[part 1 of 2: packages /EcuInstances to /CommunicationClusters/CAN1_Cluster4]
AUTOSAR XML (schema 00046)
package /EcuInstances
  ecu instance ECU4_CRN:
    associated-com-i-pdu-group=[ECU4_CRN_CAN1_Cluster4_Tx_PNC_All_Active, ECU4_CRN_CAN1_Cluster4_Tx_PNC_09, ECU4_CRN_CAN1_Cluster4_Tx_PNC_00, ECU4_CRN_CAN1_Cluster4_Rx_PNC_All_Active, ECU4_CRN_CAN1_Cluster4_Rx_PNC_09, ECU4_CRN_CAN1_Cluster4_Rx_PNC_00, ECU4_CRN_CANFD1_Cluster4_Tx_PNC_All_Active, ECU4_CRN_CANFD1_Cluster4_Tx_PNC_36, ECU4_CRN_CANFD1_Cluster4_Tx_PNC_00, ECU4_CRN_CANFD1_Cluster4_Rx_PNC_All_Active, ECU4_CRN_CANFD1_Cluster4_Rx_PNC_36, ECU4_CRN_CANFD1_Cluster4_Rx_PNC_00, PKG_Eth_Cluster4_1/ECU4_CRN_Eth_Cluster4_Tx_PNC_All_Active, PKG_Eth_Cluster4_127/ECU4_CRN_Eth_Cluster4_Tx_PNC_All_Active, PKG_Eth_Cluster4_20/ECU4_CRN_Eth_Cluster4_Tx_PNC_All_Active, PKG_Eth_Cluster4_127/ECU4_CRN_Eth_Cluster4_Tx_PNC_09, PKG_Eth_Cluster4_20/ECU4_CRN_Eth_Cluster4_Tx_PNC_09, ECU4_CRN_Eth_Cluster4_Tx_PNC_18, ECU4_CRN_Eth_Cluster4_Tx_PNC_27, PKG_Eth_Cluster4_127/ECU4_CRN_Eth_Cluster4_Tx_PNC_36, PKG_Eth_Cluster4_20/ECU4_CRN_Eth_Cluster4_Tx_PNC_36, PKG_Eth_Cluster4_127/ECU4_CRN_Eth_Cluster4_Tx_PNC_45, PKG_Eth_Cluster4_20/ECU4_CRN_Eth_Cluster4_Tx_PNC_45, PKG_Eth_Cluster4_127/ECU4_CRN_Eth_Cluster4_Tx_PNC_54, PKG_Eth_Cluster4_20/ECU4_CRN_Eth_Cluster4_Tx_PNC_54, PKG_Eth_Cluster4_127/ECU4_CRN_Eth_Cluster4_Tx_PNC_00, PKG_Eth_Cluster4_20/ECU4_CRN_Eth_Cluster4_Tx_PNC_00, PKG_Eth_Cluster4_2/ECU4_CRN_Eth_Cluster4_Rx_PNC_All_Active, PKG_Eth_Cluster4_20/ECU4_CRN_Eth_Cluster4_Rx_PNC_All_Active, ECU4_CRN_Eth_Cluster4_Rx_PNC_09, ECU4_CRN_Eth_Cluster4_Rx_PNC_36, ECU4_CRN_Eth_Cluster4_Rx_PNC_45, ECU4_CRN_Eth_Cluster4_Rx_PNC_54, ECU4_CRN_Eth_Cluster4_Rx_PNC_00, TxNorm_ECU4_CRN_LIN5_Cluster4, RxNorm_ECU4_CRN_LIN5_Cluster4]
    com-configuration-gw-time-base=0.005
    com-configuration-rx-time-base=0.005
    com-configuration-tx-time-base=0.005
    eth-switch-port-group-derivation=true
    pn-reset-time=1.1
    pnc-prepare-sleep-timer=1.3
    sleep-mode-supported=true
    wake-up-over-bus-supported=true
    can communication controller ECU4_CRN_CAN1_Cluster4: wake-up-by-controller-supported=true, can-controller-attributes=can-controller-configuration-requirements={max-number-of-time-quanta-per-bit=20, max-sample-point=81.25, max-sync-jump-width=20, min-number-of-time-quanta-per-bit=15, min-sample-point=80, min-sync-jump-width=18.75}
    can communication controller ECU4_CRN_CANFD1_Cluster4: wake-up-by-controller-supported=true, can-controller-attributes=can-controller-configuration-requirements={can-controller-fd-requirements={max-number-of-time-quanta-per-bit=20, max-sample-point=80, max-sync-jump-width=25, min-number-of-time-quanta-per-bit=20, min-sample-point=75, min-sync-jump-width=20, padding-value=0, tx-bit-rate-switch=true}, max-number-of-time-quanta-per-bit=80, max-sample-point=80, max-sync-jump-width=20, min-number-of-time-quanta-per-bit=80, min-sample-point=80, min-sync-jump-width=20}
    ethernet communication controller ECU4_CRN_Eth_Cluster4: mac-unicast-address=00:11:22:33:44:04, maximum-receive-buffer-length=1522, maximum-transmit-buffer-length=1522
      coupling port COUPLING_PORT: connection-negotiation-behavior=MASTER, coupling-port-details=global-time-props=propagation-delay=0, coupling-port-role=STANDARD-PORT, mac-multicast-address=[MACMULTICASTADDRESS_01_00_5e_01_00_08, MACMULTICASTADDRESS_01_00_5e_7f_00_01], physical-layer-type=100BASE-T1  # ECU4_CRN
        vlan-memberships:
          default-priority=0, send-activity=NOT-SENT, vlan=Eth_Cluster4_1
          default-priority=0, send-activity=NOT-SENT, vlan=Eth_Cluster4_2
          default-priority=5, send-activity=NOT-SENT, vlan=Eth_Cluster4_20
          default-priority=5, send-activity=NOT-SENT, vlan=Eth_Cluster4_127
    lin master ECU4_CRN_LIN5_Cluster4: wake-up-by-controller-supported=true, protocol-version=LIN2.1, time-base=0.005, time-base-jitter=0.000176
      lin-slave-config configured-nad=5, function-id=0, initial-nad=5, supplier-id=3, variant-id=0:
        ident IDENT_ECU_IF_Cluster4_LIN_S4
    can communication connector ECU4_CRN_CAN1_Cluster4_6it1ke922hxi7y4c8scsqzzry: comm-controller=ECU4_CRN_CAN1_Cluster4, pnc-gateway-type=ACTIVE, pnc-wakeup-data-mask=131328
    can communication connector ECU4_CRN_CANFD1_Cluster4_bx4qzxpu7xp7napnh6bsrtlzq: comm-controller=ECU4_CRN_CANFD1_Cluster4, pnc-gateway-type=ACTIVE, pnc-wakeup-data-mask=17592186044672
    ethernet communication connector ECU4_CRN_Eth_Cluster4_7f3fu4rgtopbi2t35la2b13rd: comm-controller=ECU4_CRN_Eth_Cluster4, pnc-gateway-type=NONE, maximum-transmission-unit=1500, neighbor-cache-size=128, network-endpoint=NE_dhcpv4AndFixed_169_254_17_4, pnc-filter-data-mask=4620710844295151872
    ethernet communication connector ECU4_CRN_Eth_Cluster4_3g6xoesclytkmkqofl9pi6ol1: comm-controller=ECU4_CRN_Eth_Cluster4, pnc-gateway-type=PASSIVE, maximum-transmission-unit=1500, neighbor-cache-size=128, network-endpoint=[NE_Multicast_Rx_fixed_239_127_0_1, NE_fixed_10_127_1_4], pnc-filter-data-mask=4620710844295151872
    ethernet communication connector ECU4_CRN_Eth_Cluster4_a4tivcve7b3dlvxw1emxbqzmz: comm-controller=ECU4_CRN_Eth_Cluster4, pnc-gateway-type=NONE, maximum-transmission-unit=1500, neighbor-cache-size=128, network-endpoint=[NE_Multicast_Rx_fixed_239_2_0_17, NE_fixed_10_2_1_4], pnc-filter-data-mask=4620710844295151872
    ethernet communication connector ECU4_CRN_Eth_Cluster4_3l8iyw65auc022so95pkbhyzp: comm-controller=ECU4_CRN_Eth_Cluster4, pnc-gateway-type=NONE, maximum-transmission-unit=1500, neighbor-cache-size=128, network-endpoint=[NE_fixed_10_20_1_4, NE_Multicast_Rx_Any, NE_Multicast_Rx_fixed_239_20_0_2], pnc-filter-data-mask=4620710844295151872
    lin communication connector ECU4_CRN_LIN5_Cluster4_b21l9awrmlmhxxw03j6k8wiqt: comm-controller=ECU4_CRN_LIN5_Cluster4
package /Systems
  system SYSTEM_XDIS: category=SYSTEM_EXTRACT, container-i-pdu-header-byte-order=big-endian, ecu-extract-version=2020.45.00, pnc-vector-length=7, pnc-vector-offset=1, system-version=2020.45.00
package /SystemSignalGroups
  24 x system signal group:
    COM_C04_SGR01_P05: system-signal=[COM_C04_Sig004, CRC_COM_C04_SGR01_P05, SQC_COM_C04_SGR01_P05]
    COM_C04_SGR01_P05_5t2743h81pbparal6h2spw309: system-signal=[COM_C04_Sig004, CRC_COM_C04_SGR01_P05, SQC_COM_C04_SGR01_P05]  # COM_C04_SGR01_P05 (degraded)
    DI_Odo_Pr5_ST3: system-signal=[CRC_DI_Odo_Pr5_ST3, Odo_ST3, SQC_DI_Odo_Pr5_ST3]  # DriverInformation Odometer
    DI_Odo_Pr5_ST3_e68xmtlkywxgxsdwekdjjhw3t: system-signal=[CRC_DI_Odo_Pr5_ST3, Odo_ST3, SQC_DI_Odo_Pr5_ST3]  # DriverInformation Odometer (degraded)
    Diag_RoE_C04_SigGrp01: system-signal=[Diag_RoE_C04_Sig00, Diag_RoE_C04_Sig01, Diag_RoE_C04_Sig02, Diag_RoE_C04_Sig03, Diag_RoE_C04_Sig04, Diag_RoE_C04_Sig05, Diag_RoE_C04_Sig06, Diag_RoE_C04_Sig07]  # Diag RoE C14 Sig Grp 01
    Diag_RoE_C04_SigGrp01_2ksq5hjijyze6lf3nboiafq6k: system-signal=[Diag_RoE_C04_Sig00, Diag_RoE_C04_Sig01, Diag_RoE_C04_Sig02, Diag_RoE_C04_Sig03, Diag_RoE_C04_Sig04, Diag_RoE_C04_Sig05, Diag_RoE_C04_Sig06, Diag_RoE_C04_Sig07]  # Diag RoE C14 Sig Grp 01 (degraded)
    Ign_Stat_Pr5_ST3: system-signal=[CRC_Ign_Stat_Pr5_ST3, ISw_Stat_ST3, KG_StartSw_Psd_ST3, SQC_Ign_Stat_Pr5_ST3, Veh_Op_Mode_ST3]  # Zuendungsstatus / Ignition state
    Ign_Stat_Pr5_ST3_csgs1dv6drms80o1i9p49677w: system-signal=[CRC_Ign_Stat_Pr5_ST3, ISw_Stat_ST3, KG_StartSw_Psd_ST3, SQC_Ign_Stat_Pr5_ST3, Veh_Op_Mode_ST3]  # Zuendungsstatus (degraded) / Ignition state (degraded)
    PT4_PTCoor4_Pr5_ST3: system-signal=[CRC_PT4_PTCoor4_Pr5_ST3, PT4_PTCoor_EngStartPN14_Stat_ST3, PT4_PTCoor_PT_Rdy_ST3, PT4_PTCoor_SSA_EngSp_ST3, Rsrv1_PT4_PTCoor_PT_Rdy_Pr5_ST3, SQC_PT4_PTCoor4_Pr5_ST3]
    PT4_PTCoor4_Pr5_ST3_af4fxb1ykieox3itqdfzs0kpb: system-signal=[CRC_PT4_PTCoor4_Pr5_ST3, PT4_PTCoor_EngStartPN14_Stat_ST3, PT4_PTCoor_PT_Rdy_ST3, PT4_PTCoor_SSA_EngSp_ST3, Rsrv1_PT4_PTCoor_PT_Rdy_Pr5_ST3, SQC_PT4_PTCoor4_Pr5_ST3]  # PT4_PTCoor4_Pr5_ST3 (degraded)
    VehSpd8_Pr5_ST3: system-signal=[CRC_VehSpd8_Pr5_ST3, SQC_VehSpd8_Pr5_ST3, VehSpd8_ST3]  # Fahrzeug Spd 8 ST3 / vehicle Spd 8 ST3
    VehSpd8_Pr5_ST3_168m1ogyookfwuxfakr38tbmv: system-signal=[CRC_VehSpd8_Pr5_ST3, SQC_VehSpd8_Pr5_ST3, VehSpd8_ST3]  # Fahrzeug Spd 8 ST3 (degraded) / vehicle Spd 8 ST3 (degraded)
    VSS_TP_Auth_ST3: system-signal=[VSS_TP_Auth_0_ST3, VSS_TP_Auth_1_ST3, VSS_TP_Auth_2_ST3, VSS_TP_Auth_3_ST3, VSS_TP_Auth_4_ST3, VSS_TP_Auth_5_ST3, VSS_TP_Auth_6_ST3, VSS_TP_Auth_7_ST3]  # VSS-Transportprotokoll für Authentifizierung / Vehicle Security System Transport Protocol for authentication broadcast
    VSS_TP_Auth_ST3_6j4id7sghlvlbroli4wjozjik: system-signal=[VSS_TP_Auth_0_ST3, VSS_TP_Auth_1_ST3, VSS_TP_Auth_2_ST3, VSS_TP_Auth_3_ST3, VSS_TP_Auth_4_ST3, VSS_TP_Auth_5_ST3, VSS_TP_Auth_6_ST3, VSS_TP_Auth_7_ST3]  # VSS-Transportprotokoll für Authentifizierung (degraded) / Vehicle Security System Transport Protocol for authentication broadcast (degraded)
    VSS_TP_RealTmOffset_ST3: system-signal=[VSS_TP_RealTmOffset_0_ST3, VSS_TP_RealTmOffset_1_ST3, VSS_TP_RealTmOffset_2_ST3, VSS_TP_RealTmOffset_3_ST3, VSS_TP_RealTmOffset_4_ST3, VSS_TP_RealTmOffset_5_ST3, VSS_TP_RealTmOffset_6_ST3, VSS_TP_RealTmOffset_7_ST3]  # VSS-Transportprotokoll für Echtzeit-Offset / Vehicle Security System Transport Protocol for real time offset broadcast
    VSS_TP_RealTmOffset_ST3_1t7vc44gftc0wv35k5kgc2in9: system-signal=[VSS_TP_RealTmOffset_0_ST3, VSS_TP_RealTmOffset_1_ST3, VSS_TP_RealTmOffset_2_ST3, VSS_TP_RealTmOffset_3_ST3, VSS_TP_RealTmOffset_4_ST3, VSS_TP_RealTmOffset_5_ST3, VSS_TP_RealTmOffset_6_ST3, VSS_TP_RealTmOffset_7_ST3]  # VSS-Transportprotokoll für Echtzeit-Offset (degraded) / Vehicle Security System Transport Protocol for real time offset broadcast (degraded)
    VSS_TP_SecTickCount_Lvl1_ST3: system-signal=[VSS_TP_SecTickCount_Lvl1_0_ST3, VSS_TP_SecTickCount_Lvl1_1_ST3, VSS_TP_SecTickCount_Lvl1_2_ST3, VSS_TP_SecTickCount_Lvl1_3_ST3, VSS_TP_SecTickCount_Lvl1_4_ST3, VSS_TP_SecTickCount_Lvl1_5_ST3, VSS_TP_SecTickCount_Lvl1_6_ST3, VSS_TP_SecTickCount_Lvl1_7_ST3]  # VSS-Transportprotokoll für sichere Zeit Stufe 1 / Vehicle Security System Transport Protocol for secure tick count level #1
    VSS_TP_SecTickCount_Lvl1_ST3_mzmfdqtqz5kvv1kfpvg0kql3: system-signal=[VSS_TP_SecTickCount_Lvl1_0_ST3, VSS_TP_SecTickCount_Lvl1_1_ST3, VSS_TP_SecTickCount_Lvl1_2_ST3, VSS_TP_SecTickCount_Lvl1_3_ST3, VSS_TP_SecTickCount_Lvl1_4_ST3, VSS_TP_SecTickCount_Lvl1_5_ST3, VSS_TP_SecTickCount_Lvl1_6_ST3, VSS_TP_SecTickCount_Lvl1_7_ST3]  # VSS-Transportprotokoll für sichere Zeit Stufe 1 (degraded) / Vehicle Security System Transport Protocol for secure tick count level #1 (degraded)
    VSS_TP_SecTickCount_Lvl2_ST3: system-signal=[VSS_TP_SecTickCount_Lvl2_0_ST3, VSS_TP_SecTickCount_Lvl2_1_ST3, VSS_TP_SecTickCount_Lvl2_2_ST3, VSS_TP_SecTickCount_Lvl2_3_ST3, VSS_TP_SecTickCount_Lvl2_4_ST3, VSS_TP_SecTickCount_Lvl2_5_ST3, VSS_TP_SecTickCount_Lvl2_6_ST3, VSS_TP_SecTickCount_Lvl2_7_ST3]  # VSS-Transportprotokoll für sichere Zeit Stufe 2 / Vehicle Security System Transport Protocol for secure tick count level #2
    VSS_TP_SecTickCount_Lvl2_ST3_9eubq13iosat764o0lqh5xb6r: system-signal=[VSS_TP_SecTickCount_Lvl2_0_ST3, VSS_TP_SecTickCount_Lvl2_1_ST3, VSS_TP_SecTickCount_Lvl2_2_ST3, VSS_TP_SecTickCount_Lvl2_3_ST3, VSS_TP_SecTickCount_Lvl2_4_ST3, VSS_TP_SecTickCount_Lvl2_5_ST3, VSS_TP_SecTickCount_Lvl2_6_ST3, VSS_TP_SecTickCount_Lvl2_7_ST3]  # VSS-Transportprotokoll für sichere Zeit Stufe 2 (degraded) / Vehicle Security System Transport Protocol for secure tick count level #2 (degraded)
    VSS_TP_SharedSecret_ST3: system-signal=[VSS_TP_SharedSecret_0_ST3, VSS_TP_SharedSecret_1_ST3, VSS_TP_SharedSecret_2_ST3, VSS_TP_SharedSecret_3_ST3, VSS_TP_SharedSecret_4_ST3, VSS_TP_SharedSecret_5_ST3, VSS_TP_SharedSecret_6_ST3, VSS_TP_SharedSecret_7_ST3]  # VSS-Transportprotokoll für gemeinsames Geheimnis / Vehicle Security System Transport Protocol for shared secret broadcast
    VSS_TP_SharedSecret_ST3_8pj4t8t4rm3tw3pk5hj7vonti: system-signal=[VSS_TP_SharedSecret_0_ST3, VSS_TP_SharedSecret_1_ST3, VSS_TP_SharedSecret_2_ST3, VSS_TP_SharedSecret_3_ST3, VSS_TP_SharedSecret_4_ST3, VSS_TP_SharedSecret_5_ST3, VSS_TP_SharedSecret_6_ST3, VSS_TP_SharedSecret_7_ST3]  # VSS-Transportprotokoll für gemeinsames Geheimnis (degraded) / Vehicle Security System Transport Protocol for shared secret broadcast (degraded)
    VSS_TP_VIN_ST3: system-signal=[VSS_TP_VIN_0_ST3, VSS_TP_VIN_1_ST3, VSS_TP_VIN_2_ST3, VSS_TP_VIN_3_ST3, VSS_TP_VIN_4_ST3, VSS_TP_VIN_5_ST3, VSS_TP_VIN_6_ST3, VSS_TP_VIN_7_ST3]  # VSS-Transportprotokoll für Fahrzeugidentifikationsnummer / Vehicle Security System Transport Protocol for Vehicle Identification Number
    VSS_TP_VIN_ST3_bz1xsv84cxzl09j028gn39p69: system-signal=[VSS_TP_VIN_0_ST3, VSS_TP_VIN_1_ST3, VSS_TP_VIN_2_ST3, VSS_TP_VIN_3_ST3, VSS_TP_VIN_4_ST3, VSS_TP_VIN_5_ST3, VSS_TP_VIN_6_ST3, VSS_TP_VIN_7_ST3]  # VSS-Transportprotokoll für Fahrzeugidentifikationsnummer (degraded) / Vehicle Security System Transport Protocol for Vehicle Identification Number (degraded)
package /Pdus/CAN1_Cluster4/PKG_CAN1_Cluster4
  pdu Ign_Stat_ST3: length=4, minimum-delay=0.02, transmission-mode-true-timing={cyclic-timing={time-offset=0.01, time-period=0.1}, event-controlled-timing=number-of-repetitions=0}, unused-bit-pattern=255  # Zuendungsstatus / Ignition state
    signal CRC_Ign_Stat_Pr5_ST3: start 0, 16 bit, little-endian, data-type-policy=OVERRIDE, i-signal-type=PRIMITIVE, init-value=20886, base-type=uint16, data-constr=c16_CRC_woSNA, transfer-property=PENDING  # CRC-Checksumme der Signal Gruppe gemäß AUTOSAR Profil 5 / CRC-checksum of signal group according to AUTOSAR Profile 5
    signal ISw_Stat_ST3: start 24, 3 bit, little-endian, data-type-policy=OVERRIDE, i-signal-type=PRIMITIVE, init-value=7, base-type=uint8, invalid-value=7, compu-method=c03_ISw_Stat, data-constr=c03_ISw_Stat, transfer-property=TRIGGERED-ON-CHANGE  # Klemmenstatus / Ignition switch state
    signal KG_StartSw_Psd_ST3: start 31, 1 bit, little-endian, data-type-policy=OVERRIDE, i-signal-type=PRIMITIVE, init-value=0, base-type=boolean, transfer-property=TRIGGERED-ON-CHANGE  # Keyless Go Starttaster betätigt / Keyless Go start switch pressed
    signal SQC_Ign_Stat_Pr5_ST3: start 16, 8 bit, little-endian, data-type-policy=OVERRIDE, i-signal-type=PRIMITIVE, init-value=0, base-type=uint8, compu-method=none_1_0, data-constr=c08_0_255_1_SNA_na, transfer-property=PENDING  # Sequenzzähler / Sequence counter
    signal Veh_Op_Mode_ST3: start 27, 4 bit, little-endian, data-type-policy=OVERRIDE, i-signal-type=PRIMITIVE, init-value=0, base-type=uint8, invalid-value=15, compu-method=c04_VehOpMode, data-constr=c04_VehOpMode, transfer-property=TRIGGERED-ON-CHANGE  # Fahrzeug Betriebsmodus / Operating Mode Vehicle
    mapping Ign_Stat_Pr5_ST3_csgs1dv6drms80o1i9p49677w: i-signal-group=Ign_Stat_ST3/Ign_Stat_Pr5_ST3_csgs1dv6drms80o1i9p49677w, packing-byte-order=little-endian, transfer-property=TRIGGERED-ON-CHANGE
  dcm i pdu SDU_DIAG_C10_ExtEth_RQ_CAN1_CTP: length=4095, diag-pdu-type=DIAG-REQUEST
  dcm i pdu SDU_DIAG_C10_ExtEth_RS_CAN1_CTP: length=4095, diag-pdu-type=DIAG-RESPONSE
  dcm i pdu SDU_DIAG_C10_IntEth_RQ_CAN1_CTP: length=4095, diag-pdu-type=DIAG-REQUEST
  dcm i pdu SDU_DIAG_C10_IntEth_RS_CAN1_CTP: length=4095, diag-pdu-type=DIAG-RESPONSE
  dcm i pdu SDU_DIAG_GLOBAL_ExtEth_RQ_CAN1_ST3: length=7, diag-pdu-type=DIAG-REQUEST
  dcm i pdu SDU_DIAG_GLOBAL_IntEth_RQ_CAN1_ST3: length=7, diag-pdu-type=DIAG-REQUEST
package /Pdus/CANFD1_Cluster4/PKG_CANFD1_Cluster4
  secured i pdu C04_CANFD_1_Container_ST3_C04_CANFD_1_Container_ST3_Ign_Stat_ST3_secured: length=8, contained-i-pdu-props={collection-semantics=LAST-IS-BEST, header-id-short-header=32768, timeout=0.01, trigger=NEVER}, authentication-props=SECOC_AP_CMAC_AES_128_24, freshness-props=SECOC_FP_10000_40_8_true, payload=C04_CANFD_1_Container_ST3_C04_CANFD_1_Container_ST3_Ign_Stat_ST3_eexaxtkd214droewntksh6wv, secure-communication-props={authentication-retries=0, data-id=28212, freshness-value-id=1}
  dcm i pdu SDU_DIAG_C19_ExtEth_RQ_CANFD1_CTP: length=4095, diag-pdu-type=DIAG-REQUEST
  dcm i pdu SDU_DIAG_C19_ExtEth_RS_CANFD1_CTP: length=4095, diag-pdu-type=DIAG-RESPONSE
  dcm i pdu SDU_DIAG_C19_IntEth_RQ_CANFD1_CTP: length=4095, diag-pdu-type=DIAG-REQUEST
  dcm i pdu SDU_DIAG_C19_IntEth_RS_CANFD1_CTP: length=4095, diag-pdu-type=DIAG-RESPONSE
  dcm i pdu SDU_DIAG_ECU4_CTP_03_ExtCAN_RQ_FD1_ST3: length=4095, diag-pdu-type=DIAG-REQUEST
  dcm i pdu SDU_DIAG_ECU4_CTP_03_ExtCAN_RS_FD1_ST3: length=4095, diag-pdu-type=DIAG-RESPONSE
  dcm i pdu SDU_DIAG_GLOBAL_ExtCAN_RQ_CANFD1_ST3: length=7, diag-pdu-type=DIAG-REQUEST
  dcm i pdu SDU_DIAG_GLOBAL_ExtEth_RQ_CANFD1_ST3: length=7, diag-pdu-type=DIAG-REQUEST
  dcm i pdu SDU_DIAG_GLOBAL_IntEth_RQ_CANFD1_ST3: length=7, diag-pdu-type=DIAG-REQUEST
  pdu SDU_TPA_CANFD_Eth_ST3: length=800, minimum-delay=0.005, transmission-mode-true-timing=event-controlled-timing=number-of-repetitions=0
    signal TPA_CANFD_Eth_ST3_ISignal: start 0, 6400 bit, opaque, i-signal-type=ARRAY, base-type=uint8, dynamic-length=true, transfer-property=TRIGGERED  # Transport Protokoll zwischen CAN-FD ECU und Ethernet ECU / Transport protocol between CAN-FD ECU and Ethernet ECU
  pdu SDU_TPA_Eth_CANFD_ST3: length=55, minimum-delay=0.005, transmission-mode-true-timing=event-controlled-timing=number-of-repetitions=0
    signal TPA_Eth_CANFD_ST3_ISignal: start 0, 440 bit, opaque, i-signal-type=ARRAY, base-type=uint8, dynamic-length=true, transfer-property=TRIGGERED  # Transport Protokoll zwischen Ethernet ECU und CAN-FD ECU / Transport protocol between Ethernet ECU and CAN-FD ECU
package /Pdus/CANFD1_Cluster4/PKG_CANFD1_Cluster4/C04_CANFD_1_Container_ST3
  pdu C04_CANFD_1_Container_ST3_Ign_Stat_ST3: length=4, minimum-delay=0.02, transmission-mode-true-timing={cyclic-timing=time-period=0.1, event-controlled-timing=number-of-repetitions=0}, unused-bit-pattern=255  # Zuendungsstatus / Ignition state
    signal CRC_Ign_Stat_Pr5_ST3: start 0, 16 bit, little-endian, data-type-policy=OVERRIDE, i-signal-type=PRIMITIVE, init-value=20886, base-type=uint16, data-constr=c16_CRC_woSNA, transfer-property=PENDING  # CRC-Checksumme der Signal Gruppe gemäß AUTOSAR Profil 5 / CRC-checksum of signal group according to AUTOSAR Profile 5
    signal ISw_Stat_ST3: start 24, 3 bit, little-endian, data-type-policy=OVERRIDE, i-signal-type=PRIMITIVE, init-value=7, base-type=uint8, invalid-value=7, compu-method=c03_ISw_Stat, data-constr=c03_ISw_Stat, transfer-property=TRIGGERED-ON-CHANGE  # Klemmenstatus / Ignition switch state
    signal KG_StartSw_Psd_ST3: start 31, 1 bit, little-endian, data-type-policy=OVERRIDE, i-signal-type=PRIMITIVE, init-value=0, base-type=boolean, transfer-property=TRIGGERED-ON-CHANGE  # Keyless Go Starttaster betätigt / Keyless Go start switch pressed
    signal SQC_Ign_Stat_Pr5_ST3: start 16, 8 bit, little-endian, data-type-policy=OVERRIDE, i-signal-type=PRIMITIVE, init-value=0, base-type=uint8, compu-method=none_1_0, data-constr=c08_0_255_1_SNA_na, transfer-property=PENDING  # Sequenzzähler / Sequence counter
    signal Veh_Op_Mode_ST3: start 27, 4 bit, little-endian, data-type-policy=OVERRIDE, i-signal-type=PRIMITIVE, init-value=0, base-type=uint8, invalid-value=15, compu-method=c04_VehOpMode, data-constr=c04_VehOpMode, transfer-property=TRIGGERED-ON-CHANGE  # Fahrzeug Betriebsmodus / Operating Mode Vehicle
    mapping Ign_Stat_Pr5_ST3_csgs1dv6drms80o1i9p49677w: i-signal-group=C04_CANFD_1_Container_ST3_Ign_Stat_ST3/Ign_Stat_Pr5_ST3_csgs1dv6drms80o1i9p49677w, packing-byte-order=little-endian, transfer-property=TRIGGERED-ON-CHANGE
  pdu C04_CANFD_1_Container_ST3_VSS_TP_Auth_ST3: length=8, contained-i-pdu-props={collection-semantics=LAST-IS-BEST, header-id-short-header=4259841, timeout=0.01, trigger=NEVER}, minimum-delay=0.02, transmission-mode-true-timing=event-controlled-timing=number-of-repetitions=0, unused-bit-pattern=255  # VSS-Transportprotokoll für Authentifizierung / Vehicle Security System Transport Protocol for authentication broadcast
    signal VSS_TP_Auth_0_ST3: start 0, 8 bit, little-endian, data-type-policy=OVERRIDE, i-signal-type=PRIMITIVE, init-value=255, base-type=uint8, data-constr=c08_UInt_SNA_na  # VSS-Transportprotokoll für Authentifizierung, Byte 0 / Vehicle Security System Transport Protocol for authentication broadcast, Byte 0
    signal VSS_TP_Auth_1_ST3: start 8, 8 bit, little-endian, data-type-policy=OVERRIDE, i-signal-type=PRIMITIVE, init-value=255, base-type=uint8, data-constr=c08_UInt_SNA_na  # VSS-Transportprotokoll für Authentifizierung, Byte 1 / Vehicle Security System Transport Protocol for authentication broadcast, Byte 1
    signal VSS_TP_Auth_2_ST3: start 16, 8 bit, little-endian, data-type-policy=OVERRIDE, i-signal-type=PRIMITIVE, init-value=255, base-type=uint8, data-constr=c08_UInt_SNA_na  # VSS-Transportprotokoll für Authentifizierung, Byte 2 / Vehicle Security System Transport Protocol for authentication broadcast, Byte 2
    signal VSS_TP_Auth_3_ST3: start 24, 8 bit, little-endian, data-type-policy=OVERRIDE, i-signal-type=PRIMITIVE, init-value=255, base-type=uint8, data-constr=c08_UInt_SNA_na  # VSS-Transportprotokoll für Authentifizierung, Byte 3 / Vehicle Security System Transport Protocol for authentication broadcast, Byte 3
    signal VSS_TP_Auth_4_ST3: start 32, 8 bit, little-endian, data-type-policy=OVERRIDE, i-signal-type=PRIMITIVE, init-value=255, base-type=uint8, data-constr=c08_UInt_SNA_na  # VSS-Transportprotokoll für Authentifizierung, Byte 4 / Vehicle Security System Transport Protocol for authentication broadcast, Byte 4
    signal VSS_TP_Auth_5_ST3: start 40, 8 bit, little-endian, data-type-policy=OVERRIDE, i-signal-type=PRIMITIVE, init-value=255, base-type=uint8, data-constr=c08_UInt_SNA_na  # VSS-Transportprotokoll für Authentifizierung, Byte 5 / Vehicle Security System Transport Protocol for authentication broadcast, Byte 5
    signal VSS_TP_Auth_6_ST3: start 48, 8 bit, little-endian, data-type-policy=OVERRIDE, i-signal-type=PRIMITIVE, init-value=255, base-type=uint8, data-constr=c08_UInt_SNA_na  # VSS-Transportprotokoll für Authentifizierung, Byte 6 / Vehicle Security System Transport Protocol for authentication broadcast, Byte 6
    signal VSS_TP_Auth_7_ST3: start 56, 8 bit, little-endian, data-type-policy=OVERRIDE, i-signal-type=PRIMITIVE, init-value=255, base-type=uint8, data-constr=c08_UInt_SNA_na  # VSS-Transportprotokoll für Authentifizierung, Byte 7 / Vehicle Security System Transport Protocol for authentication broadcast, Byte 7
    mapping VSS_TP_Auth_ST3_6j4id7sghlvlbroli4wjozjik: i-signal-group=C04_CANFD_1_Container_ST3_VSS_TP_Auth_ST3/VSS_TP_Auth_ST3_6j4id7sghlvlbroli4wjozjik, packing-byte-order=little-endian, transfer-property=TRIGGERED
  pdu C04_CANFD_1_Container_ST3_VSS_TP_RealTmOffset_ST3: length=8, contained-i-pdu-props={collection-semantics=LAST-IS-BEST, header-id-short-header=4259842, timeout=0.01, trigger=NEVER}, minimum-delay=0.02, transmission-mode-true-timing=event-controlled-timing=number-of-repetitions=0, unused-bit-pattern=255  # VSS-Transportprotokoll für Echtzeit-Offset / Vehicle Security System Transport Protocol for real time offset broadcast
    signal VSS_TP_RealTmOffset_0_ST3: start 0, 8 bit, little-endian, data-type-policy=OVERRIDE, i-signal-type=PRIMITIVE, init-value=255, base-type=uint8, data-constr=c08_UInt_SNA_na  # VSS-Transportprotokoll für Echtzeit-Offset, Byte 0 / Vehicle Security System Transport Protocol for real time offset broadcast, Byte 0
    signal VSS_TP_RealTmOffset_1_ST3: start 8, 8 bit, little-endian, data-type-policy=OVERRIDE, i-signal-type=PRIMITIVE, init-value=255, base-type=uint8, data-constr=c08_UInt_SNA_na  # VSS-Transportprotokoll für Echtzeit-Offset, Byte 1 / Vehicle Security System Transport Protocol for real time offset broadcast, Byte 1
    signal VSS_TP_RealTmOffset_2_ST3: start 16, 8 bit, little-endian, data-type-policy=OVERRIDE, i-signal-type=PRIMITIVE, init-value=255, base-type=uint8, data-constr=c08_UInt_SNA_na  # VSS-Transportprotokoll für Echtzeit-Offset, Byte 2 / Vehicle Security System Transport Protocol for real time offset broadcast, Byte 2
    signal VSS_TP_RealTmOffset_3_ST3: start 24, 8 bit, little-endian, data-type-policy=OVERRIDE, i-signal-type=PRIMITIVE, init-value=255, base-type=uint8, data-constr=c08_UInt_SNA_na  # VSS-Transportprotokoll für Echtzeit-Offset, Byte 3 / Vehicle Security System Transport Protocol for real time offset broadcast, Byte 3
    signal VSS_TP_RealTmOffset_4_ST3: start 32, 8 bit, little-endian, data-type-policy=OVERRIDE, i-signal-type=PRIMITIVE, init-value=255, base-type=uint8, data-constr=c08_UInt_SNA_na  # VSS-Transportprotokoll für Echtzeit-Offset, Byte 4 / Vehicle Security System Transport Protocol for real time offset broadcast, Byte 4
    signal VSS_TP_RealTmOffset_5_ST3: start 40, 8 bit, little-endian, data-type-policy=OVERRIDE, i-signal-type=PRIMITIVE, init-value=255, base-type=uint8, data-constr=c08_UInt_SNA_na  # VSS-Transportprotokoll für Echtzeit-Offset, Byte 5 / Vehicle Security System Transport Protocol for real time offset broadcast, Byte 5
    signal VSS_TP_RealTmOffset_6_ST3: start 48, 8 bit, little-endian, data-type-policy=OVERRIDE, i-signal-type=PRIMITIVE, init-value=255, base-type=uint8, data-constr=c08_UInt_SNA_na  # VSS-Transportprotokoll für Echtzeit-Offset, Byte 6 / Vehicle Security System Transport Protocol for real time offset broadcast, Byte 6
    signal VSS_TP_RealTmOffset_7_ST3: start 56, 8 bit, little-endian, data-type-policy=OVERRIDE, i-signal-type=PRIMITIVE, init-value=255, base-type=uint8, data-constr=c08_UInt_SNA_na  # VSS-Transportprotokoll für Echtzeit-Offset, Byte 7 / Vehicle Security System Transport Protocol for real time offset broadcast, Byte 7
    mapping VSS_TP_RealTmOffset_ST3_1t7vc44gftc0wv35k5kgc2in9: i-signal-group=C04_CANFD_1_Container_ST3_VSS_TP_RealTmOffset_ST3/VSS_TP_RealTmOffset_ST3_1t7vc44gftc0wv35k5kgc2in9, packing-byte-order=little-endian, transfer-property=TRIGGERED
  pdu C04_CANFD_1_Container_ST3_VSS_TP_SecTickCount_Lvl2_ST3: length=8, contained-i-pdu-props={collection-semantics=LAST-IS-BEST, header-id-short-header=4259845, timeout=0, trigger=ALWAYS}, minimum-delay=0.02, transmission-mode-true-timing=event-controlled-timing=number-of-repetitions=0, unused-bit-pattern=255  # VSS-Transportprotokoll für sichere Zeit Stufe 2 / Vehicle Security System Transport Protocol for secure tick count level #2
    signal VSS_TP_SecTickCount_Lvl2_0_ST3: start 0, 8 bit, little-endian, data-type-policy=OVERRIDE, i-signal-type=PRIMITIVE, init-value=255, base-type=uint8, data-constr=c08_UInt_SNA_na  # VSS-Transportprotokoll für sichere Zeit Stufe 2, Byte 0 / Vehicle Security System Transport Protocol for secure tick count level #2, Byte 0
    signal VSS_TP_SecTickCount_Lvl2_1_ST3: start 8, 8 bit, little-endian, data-type-policy=OVERRIDE, i-signal-type=PRIMITIVE, init-value=255, base-type=uint8, data-constr=c08_UInt_SNA_na  # VSS-Transportprotokoll für sichere Zeit Stufe 2, Byte 1 / Vehicle Security System Transport Protocol for secure tick count level #2, Byte 1
    signal VSS_TP_SecTickCount_Lvl2_2_ST3: start 16, 8 bit, little-endian, data-type-policy=OVERRIDE, i-signal-type=PRIMITIVE, init-value=255, base-type=uint8, data-constr=c08_UInt_SNA_na  # VSS-Transportprotokoll für sichere Zeit Stufe 2, Byte 2 / Vehicle Security System Transport Protocol for secure tick count level #2, Byte 2
    signal VSS_TP_SecTickCount_Lvl2_3_ST3: start 24, 8 bit, little-endian, data-type-policy=OVERRIDE, i-signal-type=PRIMITIVE, init-value=255, base-type=uint8, data-constr=c08_UInt_SNA_na  # VSS-Transportprotokoll für sichere Zeit Stufe 2, Byte 3 / Vehicle Security System Transport Protocol for secure tick count level #2, Byte 3
    signal VSS_TP_SecTickCount_Lvl2_4_ST3: start 32, 8 bit, little-endian, data-type-policy=OVERRIDE, i-signal-type=PRIMITIVE, init-value=255, base-type=uint8, data-constr=c08_UInt_SNA_na  # VSS-Transportprotokoll für sichere Zeit Stufe 2, Byte 4 / Vehicle Security System Transport Protocol for secure tick count level #2, Byte 4
    signal VSS_TP_SecTickCount_Lvl2_5_ST3: start 40, 8 bit, little-endian, data-type-policy=OVERRIDE, i-signal-type=PRIMITIVE, init-value=255, base-type=uint8, data-constr=c08_UInt_SNA_na  # VSS-Transportprotokoll für sichere Zeit Stufe 2, Byte 5 / Vehicle Security System Transport Protocol for secure tick count level #2, Byte 5
    signal VSS_TP_SecTickCount_Lvl2_6_ST3: start 48, 8 bit, little-endian, data-type-policy=OVERRIDE, i-signal-type=PRIMITIVE, init-value=255, base-type=uint8, data-constr=c08_UInt_SNA_na  # VSS-Transportprotokoll für sichere Zeit Stufe 2, Byte 6 / Vehicle Security System Transport Protocol for secure tick count level #2, Byte 6
    signal VSS_TP_SecTickCount_Lvl2_7_ST3: start 56, 8 bit, little-endian, data-type-policy=OVERRIDE, i-signal-type=PRIMITIVE, init-value=255, base-type=uint8, data-constr=c08_UInt_SNA_na  # VSS-Transportprotokoll für sichere Zeit Stufe 2, Byte 7 / Vehicle Security System Transport Protocol for secure tick count level #2, Byte 7
    mapping VSS_TP_SecTickCount_Lvl2_ST3_9eubq13iosat764o0lqh5xb6r: i-signal-group=C04_CANFD_1_Container_ST3_VSS_TP_SecTickCount_Lvl2_ST3/VSS_TP_SecTickCount_Lvl2_ST3_9eubq13iosat764o0lqh5xb6r, packing-byte-order=little-endian, transfer-property=TRIGGERED
  pdu C04_CANFD_1_Container_ST3_VSS_TP_SharedSecret_ST3: length=8, contained-i-pdu-props={collection-semantics=LAST-IS-BEST, header-id-short-header=4259843, timeout=0.01, trigger=NEVER}, minimum-delay=0.02, transmission-mode-true-timing=event-controlled-timing=number-of-repetitions=0, unused-bit-pattern=255  # VSS-Transportprotokoll für gemeinsames Geheimnis / Vehicle Security System Transport Protocol for shared secret broadcast
    signal VSS_TP_SharedSecret_0_ST3: start 0, 8 bit, little-endian, data-type-policy=OVERRIDE, i-signal-type=PRIMITIVE, init-value=255, base-type=uint8, data-constr=c08_UInt_SNA_na  # VSS-Transportprotokoll für gemeinsames Geheimnis, Byte 0 / Vehicle Security System Transport Protocol for shared secret broadcast, Byte 0
    signal VSS_TP_SharedSecret_1_ST3: start 8, 8 bit, little-endian, data-type-policy=OVERRIDE, i-signal-type=PRIMITIVE, init-value=255, base-type=uint8, data-constr=c08_UInt_SNA_na  # VSS-Transportprotokoll für gemeinsames Geheimnis, Byte 1 / Vehicle Security System Transport Protocol for shared secret broadcast, Byte 1
    signal VSS_TP_SharedSecret_2_ST3: start 16, 8 bit, little-endian, data-type-policy=OVERRIDE, i-signal-type=PRIMITIVE, init-value=255, base-type=uint8, data-constr=c08_UInt_SNA_na  # VSS-Transportprotokoll für gemeinsames Geheimnis, Byte 2 / Vehicle Security System Transport Protocol for shared secret broadcast, Byte 2
    signal VSS_TP_SharedSecret_3_ST3: start 24, 8 bit, little-endian, data-type-policy=OVERRIDE, i-signal-type=PRIMITIVE, init-value=255, base-type=uint8, data-constr=c08_UInt_SNA_na  # VSS-Transportprotokoll für gemeinsames Geheimnis, Byte 3 / Vehicle Security System Transport Protocol for shared secret broadcast, Byte 3
    signal VSS_TP_SharedSecret_4_ST3: start 32, 8 bit, little-endian, data-type-policy=OVERRIDE, i-signal-type=PRIMITIVE, init-value=255, base-type=uint8, data-constr=c08_UInt_SNA_na  # VSS-Transportprotokoll für gemeinsames Geheimnis, Byte 4 / Vehicle Security System Transport Protocol for shared secret broadcast, Byte 4
    signal VSS_TP_SharedSecret_5_ST3: start 40, 8 bit, little-endian, data-type-policy=OVERRIDE, i-signal-type=PRIMITIVE, init-value=255, base-type=uint8, data-constr=c08_UInt_SNA_na  # VSS-Transportprotokoll für gemeinsames Geheimnis, Byte 5 / Vehicle Security System Transport Protocol for shared secret broadcast, Byte 5
    signal VSS_TP_SharedSecret_6_ST3: start 48, 8 bit, little-endian, data-type-policy=OVERRIDE, i-signal-type=PRIMITIVE, init-value=255, base-type=uint8, data-constr=c08_UInt_SNA_na  # VSS-Transportprotokoll für gemeinsames Geheimnis, Byte 6 / Vehicle Security System Transport Protocol for shared secret broadcast, Byte 6
    signal VSS_TP_SharedSecret_7_ST3: start 56, 8 bit, little-endian, data-type-policy=OVERRIDE, i-signal-type=PRIMITIVE, init-value=255, base-type=uint8, data-constr=c08_UInt_SNA_na  # VSS-Transportprotokoll für gemeinsames Geheimnis, Byte 7 / Vehicle Security System Transport Protocol for shared secret broadcast, Byte 7
    mapping VSS_TP_SharedSecret_ST3_8pj4t8t4rm3tw3pk5hj7vonti: i-signal-group=C04_CANFD_1_Container_ST3_VSS_TP_SharedSecret_ST3/VSS_TP_SharedSecret_ST3_8pj4t8t4rm3tw3pk5hj7vonti, packing-byte-order=little-endian, transfer-property=TRIGGERED
  pdu C04_CANFD_1_Container_ST3_VSS_TP_VIN_ST3: length=8, contained-i-pdu-props={collection-semantics=LAST-IS-BEST, header-id-short-header=4259840, timeout=0.01, trigger=NEVER}, minimum-delay=0.02, transmission-mode-true-timing=event-controlled-timing=number-of-repetitions=0, unused-bit-pattern=255  # VSS-Transportprotokoll für Fahrzeugidentifikationsnummer / Vehicle Security System Transport Protocol for Vehicle Identification Number
    signal VSS_TP_VIN_0_ST3: start 0, 8 bit, little-endian, data-type-policy=OVERRIDE, i-signal-type=PRIMITIVE, init-value=63, base-type=uint8, data-constr=c08_UInt_SNA_na  # VSS-Transportprotokoll für Fahrzeugidentifikationsnummer, Byte 0 / Vehicle Security System Transport Protocol for Vehicle Identification Number, Byte 0
    signal VSS_TP_VIN_1_ST3: start 8, 8 bit, little-endian, data-type-policy=OVERRIDE, i-signal-type=PRIMITIVE, init-value=63, base-type=uint8, data-constr=c08_UInt_SNA_na  # VSS-Transportprotokoll für Fahrzeugidentifikationsnummer, Byte 1 / Vehicle Security System Transport Protocol for Vehicle Identification Number, Byte 1
    signal VSS_TP_VIN_2_ST3: start 16, 8 bit, little-endian, data-type-policy=OVERRIDE, i-signal-type=PRIMITIVE, init-value=63, base-type=uint8, data-constr=c08_UInt_SNA_na  # VSS-Transportprotokoll für Fahrzeugidentifikationsnummer, Byte 2 / Vehicle Security System Transport Protocol for Vehicle Identification Number, Byte 2
    signal VSS_TP_VIN_3_ST3: start 24, 8 bit, little-endian, data-type-policy=OVERRIDE, i-signal-type=PRIMITIVE, init-value=63, base-type=uint8, data-constr=c08_UInt_SNA_na  # VSS-Transportprotokoll für Fahrzeugidentifikationsnummer, Byte 3 / Vehicle Security System Transport Protocol for Vehicle Identification Number, Byte 3
    signal VSS_TP_VIN_4_ST3: start 32, 8 bit, little-endian, data-type-policy=OVERRIDE, i-signal-type=PRIMITIVE, init-value=63, base-type=uint8, data-constr=c08_UInt_SNA_na  # VSS-Transportprotokoll für Fahrzeugidentifikationsnummer, Byte 4 / Vehicle Security System Transport Protocol for Vehicle Identification Number, Byte 4
    signal VSS_TP_VIN_5_ST3: start 40, 8 bit, little-endian, data-type-policy=OVERRIDE, i-signal-type=PRIMITIVE, init-value=63, base-type=uint8, data-constr=c08_UInt_SNA_na  # VSS-Transportprotokoll für Fahrzeugidentifikationsnummer, Byte 5 / Vehicle Security System Transport Protocol for Vehicle Identification Number, Byte 5
    signal VSS_TP_VIN_6_ST3: start 48, 8 bit, little-endian, data-type-policy=OVERRIDE, i-signal-type=PRIMITIVE, init-value=63, base-type=uint8, data-constr=c08_UInt_SNA_na  # VSS-Transportprotokoll für Fahrzeugidentifikationsnummer, Byte 6 / Vehicle Security System Transport Protocol for Vehicle Identification Number, Byte 6
    signal VSS_TP_VIN_7_ST3: start 56, 8 bit, little-endian, data-type-policy=OVERRIDE, i-signal-type=PRIMITIVE, init-value=63, base-type=uint8, data-constr=c08_UInt_SNA_na  # VSS-Transportprotokoll für Fahrzeugidentifikationsnummer, Byte 7 / Vehicle Security System Transport Protocol for Vehicle Identification Number, Byte 7
    mapping VSS_TP_VIN_ST3_bz1xsv84cxzl09j028gn39p69: i-signal-group=C04_CANFD_1_Container_ST3_VSS_TP_VIN_ST3/VSS_TP_VIN_ST3_bz1xsv84cxzl09j028gn39p69, packing-byte-order=little-endian, transfer-property=TRIGGERED
package /Pdus/CANFD1_Cluster4/PKG_CANFD1_Cluster4/COM_C04_Frm05
  pdu COM_C04_Frm05_COM_C04_Pdu05: length=16, contained-i-pdu-props={collection-semantics=QUEUED, header-id-short-header=4194817, timeout=0.01, trigger=NEVER}, minimum-delay=0.1, transmission-mode-true-timing=event-controlled-timing=number-of-repetitions=0, unused-bit-pattern=255  # COM C04 Pdu 05
    signal COM_C04_Sig004: start 24, 32 bit, little-endian, data-type-policy=OVERRIDE, i-signal-type=PRIMITIVE, init-value=4294967295, base-type=uint32, invalid-value=4294967295, data-constr=DT_Uint32  # COM C04 Sig 004
    signal COM_C04_Sig005: start 56, 32 bit, little-endian, data-type-policy=OVERRIDE, i-signal-type=PRIMITIVE, init-value=2147483647, base-type=sint32, data-constr=DT_SInt32, transfer-property=TRIGGERED  # COM C04 Sig 005
    signal CRC_COM_C04_SGR01_P05: start 0, 16 bit, little-endian, data-type-policy=OVERRIDE, i-signal-type=PRIMITIVE, init-value=13866, base-type=uint16, data-constr=c16_CRC_woSNA_1  # CRC-Checksumme der Signal Gruppe gemäß AUTOSAR Profil 5 / CRC-checksum of signal group according to AUTOSAR Profile 5
    signal SQC_COM_C04_SGR01_P05: start 16, 8 bit, little-endian, data-type-policy=OVERRIDE, i-signal-type=PRIMITIVE, init-value=0, base-type=uint8, compu-method=none_1_0, data-constr=c08_0_255_1_SNA_na  # Sequenzzähler / Sequence counter
    mapping COM_C04_SGR01_P05_5t2743h81pbparal6h2spw309: i-signal-group=COM_C04_SGR01_P05_5t2743h81pbparal6h2spw309, packing-byte-order=little-endian, transfer-property=TRIGGERED
  pdu COM_C04_Frm05_COM_C04_Pdu06: length=16, contained-i-pdu-props={collection-semantics=QUEUED, header-id-short-header=4194818, timeout=0.01, trigger=NEVER}, minimum-delay=0.005, transmission-mode-true-timing=event-controlled-timing={number-of-repetitions=100, repetition-period=0.1}, unused-bit-pattern=0  # COM C04 Pdu 06
    signal COM_C04_Sig006: start 0, 16 bit, little-endian, data-type-policy=OVERRIDE, i-signal-type=PRIMITIVE, init-value=65535, base-type=uint16, data-constr=DT_Uint16, transfer-property=TRIGGERED-ON-CHANGE  # COM C04 Sig 006
    signal COM_C04_Sig007: start 32, 16 bit, little-endian, data-type-policy=OVERRIDE, i-signal-type=PRIMITIVE, init-value=32767, base-type=sint16, data-constr=sint16_s16, transfer-property=TRIGGERED-ON-CHANGE  # COM C04 Sig 007
  pdu COM_C04_Frm05_COM_C04_Pdu07: length=4, contained-i-pdu-props={collection-semantics=QUEUED, header-id-short-header=4194819, timeout=0.01, trigger=NEVER}, minimum-delay=0.1, transmission-mode-true-timing={cyclic-timing={time-offset=0, time-period=0.5}, event-controlled-timing=number-of-repetitions=0}, unused-bit-pattern=255  # COM C04 Pdu 07
    signal COM_C04_Sig008: start 0, 32 bit, little-endian, data-type-policy=OVERRIDE, i-signal-type=PRIMITIVE, init-value=-1, base-type=sint32, data-constr=DT_SInt32, transfer-property=TRIGGERED-ON-CHANGE  # replicated from COM C04 Sig 008
package /Pdus/CANFD1_Cluster4/PKG_CANFD1_Cluster4/COM_C19_Frm02
  pdu COM_C19_Frm02_COM_C19_Pdu02: length=16, contained-i-pdu-props={collection-semantics=QUEUED, header-id-short-header=1638657, timeout=0.01, trigger=NEVER}, minimum-delay=0.01, transmission-mode-true-timing=event-controlled-timing=number-of-repetitions=0, unused-bit-pattern=255  # COM C04 Pdu 05
    signal COM_C19_Sig002: start 32, 32 bit, little-endian, data-type-policy=OVERRIDE, i-signal-type=PRIMITIVE, init-value=-1, base-type=sint32, data-constr=DT_SInt32, transfer-property=TRIGGERED, to ECU4_CRN
    signal COM_C19_Sig003: start 0, 32 bit, little-endian, data-type-policy=OVERRIDE, i-signal-type=PRIMITIVE, init-value=4294967295, base-type=uint32, invalid-value=4294967295, data-constr=DT_Uint32, transfer-property=TRIGGERED, to ECU4_CRN
  pdu COM_C19_Frm02_COM_C19_Pdu03: length=4, contained-i-pdu-props={collection-semantics=QUEUED, header-id-short-header=1638658, timeout=0.01, trigger=NEVER}, minimum-delay=0.01, transmission-mode-true-timing=event-controlled-timing=number-of-repetitions=0, unused-bit-pattern=255  # COM C04 Pdu 07
    signal COM_C19_Sig004: start 0, 32 bit, little-endian, data-type-policy=OVERRIDE, i-signal-type=PRIMITIVE, init-value=-1, base-type=sint32, data-constr=DT_SInt32, transfer-property=TRIGGERED, to ECU4_CRN
  pdu COM_C19_Frm02_COM_C19_Pdu04: length=16, contained-i-pdu-props={collection-semantics=QUEUED, header-id-short-header=1638659, timeout=0.01, trigger=NEVER}, minimum-delay=0.01, transmission-mode-true-timing=event-controlled-timing=number-of-repetitions=0, unused-bit-pattern=0  # COM C04 Pdu 06
    signal COM_C19_Sig005: start 32, 16 bit, little-endian, data-type-policy=OVERRIDE, i-signal-type=PRIMITIVE, init-value=32767, base-type=sint16, data-constr=sint16_s16, transfer-property=TRIGGERED, to ECU4_CRN
    signal COM_C19_Sig006: start 0, 16 bit, little-endian, data-type-policy=OVERRIDE, i-signal-type=PRIMITIVE, init-value=65535, base-type=uint16, data-constr=DT_Uint16, transfer-property=TRIGGERED, to ECU4_CRN
package /Pdus/Eth_Cluster4/PKG_Eth_Cluster4_20
  pdu CANFD_Eth_ST3_TPA: length=800, minimum-delay=0.02, transmission-mode-true-timing=event-controlled-timing=number-of-repetitions=0, unused-bit-pattern=255  # Transport Protokoll zwischen CAN-FD ECU und Ethernet ECU / Transport protocol between CAN-FD ECU and Ethernet ECU
    signal CANFD_Eth_ST3_TPA: start 0, 6400 bit, opaque, data-type-policy=OVERRIDE, i-signal-type=ARRAY, init-value=[0, 0, 0, 0, 0, 0, 0, 0, 0, 0, 0, 0, 0, 0, 0, 0, 0, 0, 0, 0, 0, 0, 0, 0, 0, 0, 0, 0, 0, 0, 0, 0, 0, 0, 0, 0, 0, 0, 0, 0, 0, 0, 0, 0, 0, 0, 0, 0, 0, 0, 0, 0, 0, 0, 0, 0, 0, 0, 0, 0, 0, 0, 0, 0, 0, 0, 0, 0, 0, 0, 0, 0, 0, 0, 0, 0, 0, 0, 0, 0, 0, 0, 0, 0, 0, 0, 0, 0, 0, 0, 0, 0, 0, 0, 0, 0, 0, 0, 0, 0, 0, 0, 0, 0, 0, 0, 0, 0, 0, 0, 0, 0, 0, 0, 0, 0, 0, 0, 0, 0, 0, 0, 0, 0, 0, 0, 0, 0, 0, 0, 0, 0, 0, 0, 0, 0, 0, 0, 0, 0, 0, 0, 0, 0, 0, 0, 0, 0, 0, 0, 0, 0, 0, 0, 0, 0, 0, 0, 0, 0, 0, 0, 0, 0, 0, 0, 0, 0, 0, 0, 0, 0, 0, 0, 0, 0, 0, 0, 0, 0, 0, 0, 0, 0, 0, 0, 0, 0, 0, 0, 0, 0, 0, 0, 0, 0, 0, 0, 0, 0, 0, 0, 0, 0, 0, 0, 0, 0, 0, 0, 0, 0, 0, 0, 0, 0, 0, 0, 0, 0, 0, 0, 0, 0, 0, 0, 0, 0, 0, 0, 0, 0, 0, 0, 0, 0, 0, 0, 0, 0, 0, 0, 0, 0, 0, 0, 0, 0, 0, 0, 0, 0, 0, 0, 0, 0, 0, 0, 0, 0, 0, 0, 0, 0, 0, 0, 0, 0, 0, 0, 0, 0, 0, 0, 0, 0, 0, 0, 0, 0, 0, 0, 0, 0, 0, 0, 0, 0, 0, 0, 0, 0, 0, 0, 0, 0, 0, 0, 0, 0, 0, 0, 0, 0, 0, 0, 0, 0, 0, 0, 0, 0, 0, 0, 0, 0, 0, 0, 0, 0, 0, 0, 0, 0, 0, 0, 0, 0, 0, 0, 0, 0, 0, 0, 0, 0, 0, 0, 0, 0, 0, 0, 0, 0, 0, 0, 0, 0, 0, 0, 0, 0, 0, 0, 0, 0, 0, 0, 0, 0, 0, 0, 0, 0, 0, 0, 0, 0, 0, 0, 0, 0, 0, 0, 0, 0, 0, 0, 0, 0, 0, 0, 0, 0, 0, 0, 0, 0, 0, 0, 0, 0, 0, 0, 0, 0, 0, 0, 0, 0, 0, 0, 0, 0, 0, 0, 0, 0, 0, 0, 0, 0, 0, 0, 0, 0, 0, 0, 0, 0, 0, 0, 0, 0, 0, 0, 0, 0, 0, 0, 0, 0, 0, 0, 0, 0, 0, 0, 0, 0, 0, 0, 0, 0, 0, 0, 0, 0, 0, 0, 0, 0, 0, 0, 0, 0, 0, 0, 0, 0, 0, 0, 0, 0, 0, 0, 0, 0, 0, 0, 0, 0, 0, 0, 0, 0, 0, 0, 0, 0, 0, 0, 0, 0, 0, 0, 0, 0, 0, 0, 0, 0, 0, 0, 0, 0, 0, 0, 0, 0, 0, 0, 0, 0, 0, 0, 0, 0, 0, 0, 0, 0, 0, 0, 0, 0, 0, 0, 0, 0, 0, 0, 0, 0, 0, 0, 0, 0, 0, 0, 0, 0, 0, 0, 0, 0, 0, 0, 0, 0, 0, 0, 0, 0, 0, 0, 0, 0, 0, 0, 0, 0, 0, 0, 0, 0, 0, 0, 0, 0, 0, 0, 0, 0, 0, 0, 0, 0, 0, 0, 0, 0, 0, 0, 0, 0, 0, 0, 0, 0, 0, 0, 0, 0, 0, 0, 0, 0, 0, 0, 0, 0, 0, 0, 0, 0, 0, 0, 0, 0, 0, 0, 0, 0, 0, 0, 0, 0, 0, 0, 0, 0, 0, 0, 0, 0, 0, 0, 0, 0, 0, 0, 0, 0, 0, 0, 0, 0, 0, 0, 0, 0, 0, 0, 0, 0, 0, 0, 0, 0, 0, 0, 0, 0, 0, 0, 0, 0, 0, 0, 0, 0, 0, 0, 0, 0, 0, 0, 0, 0, 0, 0, 0, 0, 0, 0, 0, 0, 0, 0, 0, 0, 0, 0, 0, 0, 0, 0, 0, 0, 0, 0, 0, 0, 0, 0, 0, 0, 0, 0, 0, 0, 0, 0, 0, 0, 0, 0, 0, 0, 0, 0, 0, 0, 0, 0, 0, 0, 0, 0, 0, 0, 0, 0, 0, 0, 0, 0, 0, 0, 0, 0, 0, 0, 0, 0, 0, 0, 0, 0, 0, 0, 0, 0, 0, 0, 0, 0, 0, 0, 0, 0, 0, 0, 0, 0, 0, 0, 0, 0, 0, 0, 0, 0, 0, 0, 0, 0, 0, 0, 0, 0, 0, 0, 0, 0, 0, 0, 0, 0, 0, 0, 0, 0, 0, 0, 0, 0, 0, 0, 0, 0, 0, 0, 0, 0, 0, 0, 0, 0, 0, 0, 0, 0, 0, 0, 0, 0, 0, 255], base-type=uint8, dynamic-length=true, transfer-property=TRIGGERED  # Transportprotokoll dummy Signal / transport protocol dummy signal
  pdu COM_C01_Pdu01_PN08: length=8, transmission-mode-true-timing=cyclic-timing=time-period=1, unused-bit-pattern=0
    signal COM_C01_Sig01_PN08: start 0, 8 bit, little-endian, data-type-policy=OVERRIDE, i-signal-type=PRIMITIVE, init-value=255, base-type=uint8, data-constr=DT_uint8, transfer-property=PENDING, to ECU4_CRN(timeout 1.1 s)
  pdu COM_C01_Pdu01_PN17: length=8, transmission-mode-true-timing=cyclic-timing=time-period=1, unused-bit-pattern=0
    signal COM_C01_Sig01_PN17: start 0, 8 bit, little-endian, data-type-policy=OVERRIDE, i-signal-type=PRIMITIVE, init-value=255, base-type=uint8, data-constr=DT_uint8, transfer-property=PENDING, to ECU4_CRN(timeout 1.1 s)
  pdu COM_C01_Pdu01_PN44: length=8, transmission-mode-true-timing=cyclic-timing=time-period=1, unused-bit-pattern=0
    signal COM_C01_Sig01_PN44: start 0, 8 bit, little-endian, data-type-policy=OVERRIDE, i-signal-type=PRIMITIVE, init-value=255, base-type=uint8, data-constr=DT_uint8, transfer-property=PENDING, to ECU4_CRN(timeout 1.1 s)
  pdu COM_C01_Pdu01_PN53: length=8, transmission-mode-true-timing=cyclic-timing=time-period=1, unused-bit-pattern=0
    signal COM_C01_Sig01_PN53: start 0, 8 bit, little-endian, data-type-policy=OVERRIDE, i-signal-type=PRIMITIVE, init-value=255, base-type=uint8, data-constr=DT_uint8, transfer-property=PENDING, to ECU4_CRN(timeout 1.1 s)
  pdu COM_C01_Pdu01_PN62: length=8, transmission-mode-true-timing=cyclic-timing=time-period=1, unused-bit-pattern=0
    signal COM_C01_Sig01_PN62: start 0, 8 bit, little-endian, data-type-policy=OVERRIDE, i-signal-type=PRIMITIVE, init-value=255, base-type=uint8, data-constr=DT_uint8, transfer-property=PENDING, to ECU4_CRN(timeout 1.1 s)
  pdu COM_C04_C08_Pdu02_TpConnection: length=5000, minimum-delay=0.04, transmission-mode-true-timing=event-controlled-timing=number-of-repetitions=0
    signal COM_C04_C08_Pdu02_TpConnection_ISignal: start 0, 1500 bit, opaque, i-signal-type=ARRAY, base-type=uint8, dynamic-length=true, transfer-property=TRIGGERED
  pdu COM_C04_C14_Pdu01_TpConnection: length=4095, minimum-delay=0.04, transmission-mode-true-timing=event-controlled-timing=number-of-repetitions=0
    signal COM_C04_C14_Pdu01_TpConnection_ISignal: start 0, 1500 bit, opaque, i-signal-type=ARRAY, base-type=uint8, dynamic-length=true, transfer-property=TRIGGERED
  pdu COM_C04_Pdu01_PN08: length=8, transmission-mode-true-timing=cyclic-timing={time-offset=0, time-period=1}, unused-bit-pattern=0
    signal COM_C04_Sig01_PN08: start 0, 8 bit, little-endian, data-type-policy=OVERRIDE, i-signal-type=PRIMITIVE, init-value=255, base-type=uint8, data-constr=DT_uint8, transfer-property=PENDING
  pdu COM_C04_Pdu01_PN17: length=8, transmission-mode-true-timing=cyclic-timing={time-offset=0.005, time-period=1}, unused-bit-pattern=0
    signal COM_C04_Sig01_PN17: start 0, 8 bit, little-endian, data-type-policy=OVERRIDE, i-signal-type=PRIMITIVE, init-value=255, base-type=uint8, data-constr=DT_uint8, transfer-property=PENDING
  pdu COM_C04_Pdu01_PN44: length=8, transmission-mode-true-timing=cyclic-timing={time-offset=0.01, time-period=1}, unused-bit-pattern=0
    signal COM_C04_Sig01_PN44: start 0, 8 bit, little-endian, data-type-policy=OVERRIDE, i-signal-type=PRIMITIVE, init-value=255, base-type=uint8, data-constr=DT_uint8, transfer-property=PENDING
  pdu COM_C04_Pdu01_PN53: length=8, transmission-mode-true-timing=cyclic-timing={time-offset=0.015, time-period=1}, unused-bit-pattern=0
    signal COM_C04_Sig01_PN53: start 0, 8 bit, little-endian, data-type-policy=OVERRIDE, i-signal-type=PRIMITIVE, init-value=255, base-type=uint8, data-constr=DT_uint8, transfer-property=PENDING
  pdu COM_C04_Pdu01_PN62: length=8, transmission-mode-true-timing=cyclic-timing={time-offset=0.02, time-period=1}, unused-bit-pattern=0
    signal COM_C04_Sig01_PN62: start 0, 8 bit, little-endian, data-type-policy=OVERRIDE, i-signal-type=PRIMITIVE, init-value=255, base-type=uint8, data-constr=DT_uint8, transfer-property=PENDING
  pdu COM_C04_Pdu02: length=10, transmission-mode-true-timing=event-controlled-timing=number-of-repetitions=0  # COM C04 PDU 02
    signal COM_C04_Sig002: start 0, 80 bit, opaque, data-transformations=SOME_IP_No_E2E_8Bit, data-type-policy=TRANSFORMING-I-SIGNAL, i-signal-type=ARRAY, someip-transformation-i-signal-props{transformer=SOME_IP_8Bit, implements-someip-string-handling=true, interface-version=1, message-type=RESPONSE}, transfer-property=TRIGGERED  # COM C04 Sig 002
  pdu COM_C04_Pdu02_Call: length=9, transmission-mode-true-timing=event-controlled-timing=number-of-repetitions=0  # COM C04 Pdu 02
    signal COM_C04_Sig002_Call: start 0, 72 bit, opaque, data-transformations=SOME_IP_No_E2E_8Bit, data-type-policy=TRANSFORMING-I-SIGNAL, i-signal-type=ARRAY, someip-transformation-i-signal-props{transformer=SOME_IP_8Bit, implements-someip-string-handling=true, interface-version=1, message-type=REQUEST}, transfer-property=TRIGGERED, to ECU4_CRN  # COM C04 Sig 002
  pdu COM_C04_Pdu03: length=3013, transmission-mode-true-timing=event-controlled-timing=number-of-repetitions=0  # COM P04 Pdu 03
    signal COM_C04_Sig003: start 0, 24104 bit, opaque, data-transformations=SOME_IP_Profile_6_8Bit, data-type-policy=TRANSFORMING-I-SIGNAL, i-signal-type=ARRAY, transfer-property=TRIGGERED  # COM C04 Sig 003
  pdu COM_C04_Pdu10: length=10, transmission-mode-true-timing=event-controlled-timing=number-of-repetitions=0  # COM C04 Pdu 10
    signal COM_C04_Sig110: start 0, 80 bit, opaque, data-transformations=SOME_IP_No_E2E_8Bit, data-type-policy=TRANSFORMING-I-SIGNAL, i-signal-type=ARRAY, someip-transformation-i-signal-props{transformer=SOME_IP_8Bit, implements-someip-string-handling=true, interface-version=1, message-type=NOTIFICATION}, transfer-property=TRIGGERED  # COM C04 Sig 110
  pdu COM_C04_Pdu11: length=15, transmission-mode-true-timing=event-controlled-timing=number-of-repetitions=0  # COM C04 Pdu 11
    signal COM_C04_Sig111: start 0, 120 bit, opaque, data-transformations=SOME_IP_No_E2E_8Bit, data-type-policy=TRANSFORMING-I-SIGNAL, i-signal-type=ARRAY, someip-transformation-i-signal-props{transformer=SOME_IP_8Bit, implements-someip-string-handling=true, interface-version=1, message-type=NOTIFICATION}, transfer-property=TRIGGERED  # COM C04 Sig 111
  pdu COM_C04_Pdu12: length=15, transmission-mode-true-timing=event-controlled-timing=number-of-repetitions=0  # COM C04 Pdu 12
    signal COM_C04_Sig112: start 0, 120 bit, opaque, data-transformations=SOME_IP_No_E2E_8Bit, data-type-policy=TRANSFORMING-I-SIGNAL, i-signal-type=ARRAY, someip-transformation-i-signal-props{transformer=SOME_IP_8Bit, implements-someip-string-handling=true, interface-version=1, message-type=NOTIFICATION}, transfer-property=TRIGGERED  # COM C04 Sig 112
  pdu COM_C04_Pdu13: length=15, transmission-mode-true-timing=event-controlled-timing=number-of-repetitions=0  # COM C04 Pdu 13
    signal COM_C04_Sig113: start 0, 120 bit, opaque, data-transformations=SOME_IP_No_E2E_8Bit, data-type-policy=TRANSFORMING-I-SIGNAL, i-signal-type=ARRAY, someip-transformation-i-signal-props{transformer=SOME_IP_8Bit, implements-someip-string-handling=true, interface-version=1, message-type=NOTIFICATION}, transfer-property=TRIGGERED  # COM C04 Sig 113
  pdu COM_C04_Pdu14: length=15, transmission-mode-true-timing=event-controlled-timing=number-of-repetitions=0  # COM C04 Pdu 14
    signal COM_C04_Sig114: start 0, 120 bit, opaque, data-transformations=SOME_IP_No_E2E_8Bit, data-type-policy=TRANSFORMING-I-SIGNAL, i-signal-type=ARRAY, someip-transformation-i-signal-props{transformer=SOME_IP_8Bit, implements-someip-string-handling=true, interface-version=1, message-type=NOTIFICATION}, transfer-property=TRIGGERED  # COM C04 Sig 114
  pdu COM_C04_Pdu15: length=15, transmission-mode-true-timing=event-controlled-timing=number-of-repetitions=0  # COM C04 Pdu 15
    signal COM_C04_Sig115: start 0, 120 bit, opaque, data-transformations=SOME_IP_No_E2E_8Bit, data-type-policy=TRANSFORMING-I-SIGNAL, i-signal-type=ARRAY, someip-transformation-i-signal-props{transformer=SOME_IP_8Bit, implements-someip-string-handling=true, interface-version=1, message-type=NOTIFICATION}, transfer-property=TRIGGERED  # COM C04 Sig 115
  pdu COM_C04_Pdu16: length=15, transmission-mode-true-timing=event-controlled-timing=number-of-repetitions=0  # COM C04 Pdu 16
    signal COM_C04_Sig116: start 0, 120 bit, opaque, data-transformations=SOME_IP_No_E2E_8Bit, data-type-policy=TRANSFORMING-I-SIGNAL, i-signal-type=ARRAY, someip-transformation-i-signal-props{transformer=SOME_IP_8Bit, implements-someip-string-handling=true, interface-version=1, message-type=NOTIFICATION}, transfer-property=TRIGGERED  # COM C04 Sig 116
  pdu COM_C04_Pdu17: length=15, transmission-mode-true-timing=event-controlled-timing=number-of-repetitions=0  # COM C04 Pdu 17
    signal COM_C04_Sig117: start 0, 120 bit, opaque, data-transformations=SOME_IP_No_E2E_8Bit, data-type-policy=TRANSFORMING-I-SIGNAL, i-signal-type=ARRAY, someip-transformation-i-signal-props{transformer=SOME_IP_8Bit, implements-someip-string-handling=true, interface-version=1, message-type=NOTIFICATION}, transfer-property=TRIGGERED  # COM C04 Sig 117
  pdu COM_C04_Pdu18: length=15, transmission-mode-true-timing=event-controlled-timing=number-of-repetitions=0  # COM C04 Pdu 18
    signal COM_C04_Sig118: start 0, 120 bit, opaque, data-transformations=SOME_IP_No_E2E_8Bit, data-type-policy=TRANSFORMING-I-SIGNAL, i-signal-type=ARRAY, someip-transformation-i-signal-props{transformer=SOME_IP_8Bit, implements-someip-string-handling=true, interface-version=1, message-type=NOTIFICATION}, transfer-property=TRIGGERED  # COM C04 Sig 118
  pdu COM_C04_Pdu19: length=15, transmission-mode-true-timing=event-controlled-timing=number-of-repetitions=0  # COM C04 Pdu 19
    signal COM_C04_Sig119: start 0, 120 bit, opaque, data-transformations=SOME_IP_No_E2E_8Bit, data-type-policy=TRANSFORMING-I-SIGNAL, i-signal-type=ARRAY, someip-transformation-i-signal-props{transformer=SOME_IP_8Bit, implements-someip-string-handling=true, interface-version=1, message-type=NOTIFICATION}, transfer-property=TRIGGERED  # COM C04 Sig 119
  pdu COM_C04_Pdu20: length=15, transmission-mode-true-timing=event-controlled-timing=number-of-repetitions=0  # COM C04 Pdu 20
    signal COM_C04_Sig120: start 0, 120 bit, opaque, data-transformations=SOME_IP_No_E2E_8Bit, data-type-policy=TRANSFORMING-I-SIGNAL, i-signal-type=ARRAY, someip-transformation-i-signal-props{transformer=SOME_IP_8Bit, implements-someip-string-handling=true, interface-version=1, message-type=NOTIFICATION}, transfer-property=TRIGGERED  # COM C04 Sig 120
  pdu COM_C04_Pdu21: length=9, transmission-mode-true-timing=cyclic-timing={time-offset=0.01, time-period=0.02}, unused-bit-pattern=255  # COM C04 Pdu 21
    signal COM_C04_Sig121: start 0, 4 bit, little-endian, data-type-policy=OVERRIDE, i-signal-type=PRIMITIVE, init-value=15, base-type=uint8, invalid-value=15, compu-method=COM_C04_Sig121, data-constr=COM_C04_Sig121, transfer-property=PENDING  # COM C04 Sig 121
    signal COM_C04_Sig221: start 14, 8 bit, little-endian, data-type-policy=OVERRIDE, i-signal-type=PRIMITIVE, init-value=255, base-type=uint8, invalid-value=255, compu-method=c08_perc_0_254_1, data-constr=c08_perc_0_254_1, transfer-property=PENDING  # COM C04 Sig 121
  pdu COM_C07_Pdu01_PN08: length=8, transmission-mode-true-timing=cyclic-timing=time-period=1, unused-bit-pattern=0
    signal COM_C07_Sig01_PN08: start 0, 8 bit, little-endian, data-type-policy=OVERRIDE, i-signal-type=PRIMITIVE, init-value=255, base-type=uint8, data-constr=DT_uint8, transfer-property=PENDING, to ECU4_CRN(timeout 1.1 s)
  pdu COM_C07_Pdu01_PN44: length=8, transmission-mode-true-timing=cyclic-timing=time-period=1, unused-bit-pattern=0
    signal COM_C07_Sig01_PN44: start 0, 8 bit, little-endian, data-type-policy=OVERRIDE, i-signal-type=PRIMITIVE, init-value=255, base-type=uint8, data-constr=DT_uint8, transfer-property=PENDING, to ECU4_CRN(timeout 1.1 s)
  pdu COM_C07_Pdu01_PN53: length=8, transmission-mode-true-timing=cyclic-timing=time-period=1, unused-bit-pattern=0
    signal COM_C07_Sig01_PN53: start 0, 8 bit, little-endian, data-type-policy=OVERRIDE, i-signal-type=PRIMITIVE, init-value=255, base-type=uint8, data-constr=DT_uint8, transfer-property=PENDING, to ECU4_CRN(timeout 1.1 s)
  pdu COM_C08_C04_Pdu02_TpConnection: length=5000, minimum-delay=0.04, transmission-mode-true-timing=event-controlled-timing=number-of-repetitions=0
    signal COM_C08_C04_Pdu02_TpConnection_ISignal: start 0, 1500 bit, opaque, i-signal-type=ARRAY, base-type=uint8, dynamic-length=true, transfer-property=TRIGGERED, to ECU4_CRN
  pdu COM_C0X_Pdu10: length=10, transmission-mode-true-timing=event-controlled-timing=number-of-repetitions=0  # COM C0X Pdu 10
    signal COM_C0X_Sig110: start 0, 80 bit, opaque, data-transformations=SOME_IP_No_E2E_8Bit, data-type-policy=TRANSFORMING-I-SIGNAL, i-signal-type=ARRAY, someip-transformation-i-signal-props{transformer=SOME_IP_8Bit, implements-someip-string-handling=true, interface-version=1, message-type=NOTIFICATION}, transfer-property=TRIGGERED, to ECU4_CRN  # COM C0X Sig 110
  pdu COM_C0X_Pdu11: length=15, transmission-mode-true-timing=event-controlled-timing=number-of-repetitions=0  # COM C0X Pdu 11
    signal COM_C0X_Sig111: start 0, 120 bit, opaque, data-transformations=SOME_IP_No_E2E_8Bit, data-type-policy=TRANSFORMING-I-SIGNAL, i-signal-type=ARRAY, someip-transformation-i-signal-props{transformer=SOME_IP_8Bit, implements-someip-string-handling=true, interface-version=1, message-type=NOTIFICATION}, transfer-property=TRIGGERED, to ECU4_CRN  # COM C0X Sig 111
  pdu COM_C0X_Pdu12: length=15, transmission-mode-true-timing=event-controlled-timing=number-of-repetitions=0  # COM C0X Pdu 12
    signal COM_C0X_Sig112: start 0, 120 bit, opaque, data-transformations=SOME_IP_No_E2E_8Bit, data-type-policy=TRANSFORMING-I-SIGNAL, i-signal-type=ARRAY, someip-transformation-i-signal-props{transformer=SOME_IP_8Bit, implements-someip-string-handling=true, interface-version=1, message-type=NOTIFICATION}, transfer-property=TRIGGERED, to ECU4_CRN  # COM C0X Sig 112
  pdu COM_C0X_Pdu13: length=15, transmission-mode-true-timing=event-controlled-timing=number-of-repetitions=0  # COM C0X Pdu 13
    signal COM_C0X_Sig113: start 0, 120 bit, opaque, data-transformations=SOME_IP_No_E2E_8Bit, data-type-policy=TRANSFORMING-I-SIGNAL, i-signal-type=ARRAY, someip-transformation-i-signal-props{transformer=SOME_IP_8Bit, implements-someip-string-handling=true, interface-version=1, message-type=NOTIFICATION}, transfer-property=TRIGGERED, to ECU4_CRN  # COM C0X Sig 113
  pdu COM_C0X_Pdu14: length=15, transmission-mode-true-timing=event-controlled-timing=number-of-repetitions=0  # COM C0X Pdu 14
    signal COM_C0X_Sig114: start 0, 120 bit, opaque, data-transformations=SOME_IP_No_E2E_8Bit, data-type-policy=TRANSFORMING-I-SIGNAL, i-signal-type=ARRAY, someip-transformation-i-signal-props{transformer=SOME_IP_8Bit, implements-someip-string-handling=true, interface-version=1, message-type=NOTIFICATION}, transfer-property=TRIGGERED, to ECU4_CRN  # COM C0X Sig 114
  pdu COM_C0X_Pdu15: length=15, transmission-mode-true-timing=event-controlled-timing=number-of-repetitions=0  # COM C0X Pdu 15
    signal COM_C0X_Sig115: start 0, 120 bit, opaque, data-transformations=SOME_IP_No_E2E_8Bit, data-type-policy=TRANSFORMING-I-SIGNAL, i-signal-type=ARRAY, someip-transformation-i-signal-props{transformer=SOME_IP_8Bit, implements-someip-string-handling=true, interface-version=1, message-type=NOTIFICATION}, transfer-property=TRIGGERED, to ECU4_CRN  # COM C0X Sig 115
  pdu COM_C0X_Pdu16: length=15, transmission-mode-true-timing=event-controlled-timing=number-of-repetitions=0  # COM C0X Pdu 16
    signal COM_C0X_Sig116: start 0, 120 bit, opaque, data-transformations=SOME_IP_No_E2E_8Bit, data-type-policy=TRANSFORMING-I-SIGNAL, i-signal-type=ARRAY, someip-transformation-i-signal-props{transformer=SOME_IP_8Bit, implements-someip-string-handling=true, interface-version=1, message-type=NOTIFICATION}, transfer-property=TRIGGERED, to ECU4_CRN  # COM C0X Sig 116
  pdu COM_C0X_Pdu17: length=15, transmission-mode-true-timing=event-controlled-timing=number-of-repetitions=0  # COM C0X Pdu 17
    signal COM_C0X_Sig117: start 0, 120 bit, opaque, data-transformations=SOME_IP_No_E2E_8Bit, data-type-policy=TRANSFORMING-I-SIGNAL, i-signal-type=ARRAY, someip-transformation-i-signal-props{transformer=SOME_IP_8Bit, implements-someip-string-handling=true, interface-version=1, message-type=NOTIFICATION}, transfer-property=TRIGGERED, to ECU4_CRN  # COM C0X Sig 117
  pdu COM_C0X_Pdu18: length=15, transmission-mode-true-timing=event-controlled-timing=number-of-repetitions=0  # COM C0X Pdu 18
    signal COM_C0X_Sig118: start 0, 120 bit, opaque, data-transformations=SOME_IP_No_E2E_8Bit, data-type-policy=TRANSFORMING-I-SIGNAL, i-signal-type=ARRAY, someip-transformation-i-signal-props{transformer=SOME_IP_8Bit, implements-someip-string-handling=true, interface-version=1, message-type=NOTIFICATION}, transfer-property=TRIGGERED, to ECU4_CRN  # COM C0X Sig 118
  pdu COM_C0X_Pdu19: length=15, transmission-mode-true-timing=event-controlled-timing=number-of-repetitions=0  # COM C0X Pdu 19
    signal COM_C0X_Sig119: start 0, 120 bit, opaque, data-transformations=SOME_IP_No_E2E_8Bit, data-type-policy=TRANSFORMING-I-SIGNAL, i-signal-type=ARRAY, someip-transformation-i-signal-props{transformer=SOME_IP_8Bit, implements-someip-string-handling=true, interface-version=1, message-type=NOTIFICATION}, transfer-property=TRIGGERED, to ECU4_CRN  # COM C0X Sig 119
  pdu COM_C0X_Pdu20: length=15, transmission-mode-true-timing=event-controlled-timing=number-of-repetitions=0  # COM C0X Pdu 20
    signal COM_C0X_Sig120: start 0, 120 bit, opaque, data-transformations=SOME_IP_No_E2E_8Bit, data-type-policy=TRANSFORMING-I-SIGNAL, i-signal-type=ARRAY, someip-transformation-i-signal-props{transformer=SOME_IP_8Bit, implements-someip-string-handling=true, interface-version=1, message-type=NOTIFICATION}, transfer-property=TRIGGERED, to ECU4_CRN  # COM C0X Sig 120
  pdu COM_C0X_Pdu21: length=9, minimum-delay=0.01, transmission-mode-true-timing={cyclic-timing=time-period=0.02, event-controlled-timing=number-of-repetitions=0}, unused-bit-pattern=255  # COM C0X Pdu 21
    signal COM_C0X_Sig121: start 0, 4 bit, little-endian, data-type-policy=OVERRIDE, i-signal-type=PRIMITIVE, init-value=15, base-type=uint8, invalid-value=15, compu-method=COM_C04_Sig121, data-constr=COM_C04_Sig121, transfer-property=TRIGGERED-ON-CHANGE, to ECU4_CRN  # COM C0X Sig 121
    signal COM_C0X_Sig221: start 14, 8 bit, little-endian, data-type-policy=OVERRIDE, i-signal-type=PRIMITIVE, init-value=255, base-type=uint8, invalid-value=255, compu-method=c08_perc_0_254_1, data-constr=c08_perc_0_254_1, transfer-property=PENDING, to ECU4_CRN  # COM C0X Sig 121
  pdu COM_C14_C04_Pdu01_TpConnection: length=4095, minimum-delay=0.04, transmission-mode-true-timing=event-controlled-timing=number-of-repetitions=0  # COM C14 C04 Pdu 01
    signal COM_C14_C04_Pdu01_TpConnection_ISignal: start 0, 1500 bit, opaque, i-signal-type=ARRAY, base-type=uint8, dynamic-length=true, transfer-property=TRIGGERED, to ECU4_CRN  # COM C14 C04 Pdu 01
  pdu DI_OdoSpeedometer_ST3: length=8, minimum-delay=0.1, transmission-mode-true-timing={cyclic-timing={time-offset=0, time-period=1}, event-controlled-timing=number-of-repetitions=0}, unused-bit-pattern=255  # Fahrerinformation Odometer und Tacho / DriverInformation Odometer and speedometer
    signal Odo_ST3: start 24, 24 bit, little-endian, data-type-policy=OVERRIDE, i-signal-type=PRIMITIVE, init-value=16777215, base-type=uint32, invalid-value=16777215, compu-method=c24_km_0_999999k9_0k1_Invld_SNA, data-constr=c24_km_0_999999k9_0k1_Invld_SNA, to ECU4_CRN  # Kilometerstand (für alle) / Odometer (for everyone)
    signal CRC_DI_Odo_Pr5_ST3: start 0, 16 bit, little-endian, data-type-policy=OVERRIDE, i-signal-type=PRIMITIVE, init-value=8633, base-type=uint16, data-constr=c16_CRC_woSNA, transfer-property=PENDING  # CRC-Checksumme der Signal Gruppe gemäß AUTOSAR Profil 5 / CRC-checksum of signal group according to AUTOSAR Profile 5
    signal SQC_DI_Odo_Pr5_ST3: start 16, 8 bit, little-endian, data-type-policy=OVERRIDE, i-signal-type=PRIMITIVE, init-value=0, base-type=uint8, compu-method=none_1_0, data-constr=c08_0_255_1_SNA_na, transfer-property=PENDING  # Sequenzzähler / Sequence counter
    signal VehSpd_Disp_ST3: start 48, 12 bit, little-endian, data-type-policy=OVERRIDE, i-signal-type=PRIMITIVE, init-value=4095, base-type=uint16, invalid-value=4095, compu-method=c12_km_p_h_0_409k4_0k1, data-constr=c12_km_p_h_0_409k4_0k1, transfer-property=PENDING  # Angezeigte Geschwindigkeit (ohne Zeigerdämpfung) / Displayed vehicle speed (without attenuation)
    mapping DI_Odo_Pr5_ST3_e68xmtlkywxgxsdwekdjjhw3t: i-signal-group=DI_Odo_Pr5_ST3_e68xmtlkywxgxsdwekdjjhw3t, packing-byte-order=little-endian, transfer-property=TRIGGERED-ON-CHANGE, update-indication-bit-position=63
  pdu Eth_CANFD_ST3_TPA: length=55, minimum-delay=0.02, transmission-mode-true-timing=event-controlled-timing=number-of-repetitions=0, unused-bit-pattern=255  # Transport Protokoll zwischen Ethernet ECU und CAN-FD ECU / Transport protocol between Ethernet ECU and CAN-FD ECU
    signal Eth_CANFD_ST3_TPA: start 0, 440 bit, opaque, data-type-policy=OVERRIDE, i-signal-type=ARRAY, init-value=[0, 0, 0, 0, 0, 0, 0, 0, 0, 0, 0, 0, 0, 0, 0, 0, 0, 0, 0, 0, 0, 0, 0, 0, 0, 0, 0, 0, 0, 0, 0, 0, 0, 0, 0, 0, 0, 0, 0, 0, 0, 0, 0, 0, 0, 0, 0, 0, 0, 0, 0, 0, 0, 0, 255], base-type=uint8, dynamic-length=true, transfer-property=TRIGGERED  # Transportprotokoll dummy Signal / transport protocol dummy signal
  pdu Ign_Stat_ST3: length=4, minimum-delay=0.02, transmission-mode-true-timing={cyclic-timing={time-offset=0.01, time-period=0.1}, event-controlled-timing=number-of-repetitions=0}, unused-bit-pattern=255  # Zuendungsstatus / Ignition state
    signal CRC_Ign_Stat_Pr5_ST3: start 0, 16 bit, little-endian, data-type-policy=OVERRIDE, i-signal-type=PRIMITIVE, init-value=20886, base-type=uint16, data-constr=c16_CRC_woSNA, transfer-property=PENDING, to ECU4_CRN  # CRC-Checksumme der Signal Gruppe gemäß AUTOSAR Profil 5 / CRC-checksum of signal group according to AUTOSAR Profile 5
    signal ISw_Stat_ST3: start 24, 3 bit, little-endian, data-type-policy=OVERRIDE, i-signal-type=PRIMITIVE, init-value=7, base-type=uint8, invalid-value=7, compu-method=c03_ISw_Stat, data-constr=c03_ISw_Stat, transfer-property=TRIGGERED-ON-CHANGE, to ECU4_CRN  # Klemmenstatus / Ignition switch state
    signal KG_StartSw_Psd_ST3: start 31, 1 bit, little-endian, data-type-policy=OVERRIDE, i-signal-type=PRIMITIVE, init-value=0, base-type=boolean, transfer-property=TRIGGERED-ON-CHANGE, to ECU4_CRN  # Keyless Go Starttaster betätigt / Keyless Go start switch pressed
    signal SQC_Ign_Stat_Pr5_ST3: start 16, 8 bit, little-endian, data-type-policy=OVERRIDE, i-signal-type=PRIMITIVE, init-value=0, base-type=uint8, compu-method=none_1_0, data-constr=c08_0_255_1_SNA_na, transfer-property=PENDING, to ECU4_CRN  # Sequenzzähler / Sequence counter
    signal Veh_Op_Mode_ST3: start 27, 4 bit, little-endian, data-type-policy=OVERRIDE, i-signal-type=PRIMITIVE, init-value=0, base-type=uint8, invalid-value=15, compu-method=c04_VehOpMode, data-constr=c04_VehOpMode, transfer-property=TRIGGERED-ON-CHANGE, to ECU4_CRN  # Fahrzeug Betriebsmodus / Operating Mode Vehicle
    mapping Ign_Stat_Pr5_ST3_csgs1dv6drms80o1i9p49677w: i-signal-group=Ign_Stat_ST3/Ign_Stat_Pr5_ST3_csgs1dv6drms80o1i9p49677w, packing-byte-order=little-endian, transfer-property=TRIGGERED-ON-CHANGE
  pdu PN14_Master_Stat1_ST3: length=8, transmission-mode-true-timing=cyclic-timing={time-offset=0.01, time-period=0.2}, unused-bit-pattern=255  # Status 12V Bordnetz Master / Powernetwork 12V master state
    signal PN14_ProdMd_Stat_ST3: start 5, 3 bit, little-endian, data-type-policy=OVERRIDE, i-signal-type=PRIMITIVE, init-value=7, base-type=uint8, invalid-value=7, compu-method=c03_PN14_ProdMd_Stat_ST3, data-constr=c03_PN14_ProdMd_Stat_ST3, transfer-property=PENDING, to ECU4_CRN  # Status des Bordnetz Produktionsmodus / Powernet production mode state
    signal PN14_SupBat_Volt_ST3: start 22, 10 bit, little-endian, data-type-policy=OVERRIDE, i-signal-type=PRIMITIVE, init-value=1023, base-type=uint16, invalid-value=1023, compu-method=c10_V_0_25k55_0k025, data-constr=c10_V_0_25k55_0k025, transfer-property=PENDING, to ECU4_CRN  # Versorgungsbatterie Istspannung / Supply battery voltage
    signal PN14_TransMd_Stat_ST3: start 0, 2 bit, little-endian, data-type-policy=OVERRIDE, i-signal-type=PRIMITIVE, init-value=3, base-type=uint8, invalid-value=3, compu-method=c02_TransMd_Stat, data-constr=c02_TransMd_Stat, transfer-property=PENDING, to ECU4_CRN  # Bordnetz Status Transportmodus / Powernet transport mode status
    signal PN14_DDP_Sw_Stat_ST3: start 2, 3 bit, little-endian, data-type-policy=OVERRIDE, i-signal-type=PRIMITIVE, init-value=0, base-type=uint8, invalid-value=7, compu-method=c03_PN14_TDP_Sw_Stat, data-constr=c03_PN14_TDP_Sw_Stat, transfer-property=PENDING  # Schalterstatus Tiefentladeschutz / Deep discharge protection switch state
    signal PN14_ExtBat_Charge_Actv_ST3: start 55, 2 bit, little-endian, data-type-policy=OVERRIDE, i-signal-type=PRIMITIVE, init-value=3, base-type=uint8, invalid-value=3, compu-method=c02_Ndef_False_True_ST3, data-constr=c02_Ndef_False_True_ST3, transfer-property=PENDING  # Externe Batterieladung erkannt / external barttery charging detected
    signal PN14_PNSec_RechargeEnable_ST3: start 53, 2 bit, little-endian, data-type-policy=OVERRIDE, i-signal-type=PRIMITIVE, init-value=3, base-type=uint8, invalid-value=3, compu-method=c02_Ndef_False_True_ST3, data-constr=c02_Ndef_False_True_ST3, transfer-property=PENDING  # Freigabe zum Nachladen der Sekundärbatterie / Enable for Recharge Secondary-Batterie
    signal PN14_ProdMd_BatStat_ST3: start 8, 7 bit, little-endian, data-type-policy=OVERRIDE, i-signal-type=PRIMITIVE, init-value=127, base-type=uint8, invalid-value=127, compu-method=c07_per_0to100_1_SNA, data-constr=c07_per_0to100_1_SNA, transfer-property=PENDING  # Der aktuelle Status der 12V Versorgungsbatterie während Produktions-Mode. / Actual 12V battery state during production mode
    signal PN14_SupBat_Curr_ST3: start 32, 13 bit, little-endian, data-type-policy=OVERRIDE, i-signal-type=PRIMITIVE, init-value=8191, base-type=uint16, invalid-value=8191, compu-method=c13_A_m409k6_409k4_0k1, data-constr=c13_A_m409k6_409k4_0k1, transfer-property=PENDING  # Versorgungsbatterie Iststrom / Supply battery current
    signal PN14_SupBat_Stat_ST3: start 15, 7 bit, little-endian, data-type-policy=OVERRIDE, i-signal-type=PRIMITIVE, init-value=127, base-type=uint8, invalid-value=127, compu-method=c07_0_111_1_SNA, data-constr=c07_0_111_1_SNA, transfer-property=PENDING  # Status Versorgungsbatterie / Supply battery state
    signal PN14_SupBat_Temp_ST3: start 45, 8 bit, little-endian, data-type-policy=OVERRIDE, i-signal-type=PRIMITIVE, init-value=255, base-type=uint8, invalid-value=255, compu-method=c08_degC_m40_85_0k5, data-constr=c08_degC_m40_85_0k5, transfer-property=PENDING  # Temperatur Versorgungsbatterie / Supply battery temperature
  pdu PT4_PTCoor4_ST3: length=4, minimum-delay=0.01, transmission-mode-true-timing={cyclic-timing={time-offset=0.005, time-period=0.1}, event-controlled-timing=number-of-repetitions=0}, unused-bit-pattern=255
    signal CRC_PT4_PTCoor4_Pr5_ST3: start 0, 16 bit, little-endian, data-type-policy=OVERRIDE, i-signal-type=PRIMITIVE, init-value=4203, base-type=uint16, data-constr=c16_CRC_woSNA, transfer-property=PENDING, to ECU4_CRN(timeout 1 s)  # CRC-Checksumme der Signal Gruppe gemäß AUTOSAR Profil 5 / CRC-checksum of signal group according to AUTOSAR Profile 5
    signal PT4_PTCoor_EngStartPN14_Stat_ST3: start 28, 3 bit, little-endian, data-type-policy=OVERRIDE, i-signal-type=PRIMITIVE, init-value=0, base-type=uint8, invalid-value=7, compu-method=c03_EngStartPN14_Stat, data-constr=c03_EngStartPN14_Stat, transfer-property=TRIGGERED-ON-CHANGE, to ECU4_CRN(timeout 1 s)  # Status PN14 bei Motorstart / PT4 Engine Start PN14 State
    signal PT4_PTCoor_PT_Rdy_ST3: start 24, 2 bit, little-endian, data-type-policy=OVERRIDE, i-signal-type=PRIMITIVE, init-value=0, base-type=uint8, invalid-value=3, compu-method=c02_PT_Rdy_V2, data-constr=c02_PT_Rdy_V2, transfer-property=TRIGGERED-ON-CHANGE, to ECU4_CRN(timeout 1 s)  # Antrieb bereit / Powertrain ready
    signal PT4_PTCoor_SSA_EngSp_ST3: start 26, 2 bit, little-endian, data-type-policy=OVERRIDE, i-signal-type=PRIMITIVE, init-value=3, base-type=uint8, invalid-value=3, compu-method=c02_Ndef_False_True_ST3, data-constr=c02_Ndef_False_True_ST3, transfer-property=TRIGGERED-ON-CHANGE, to ECU4_CRN(timeout 1 s)  # ASS Motorstopp / Stop/start automatic has engine stopped
    signal SQC_PT4_PTCoor4_Pr5_ST3: start 16, 8 bit, little-endian, data-type-policy=OVERRIDE, i-signal-type=PRIMITIVE, init-value=0, base-type=uint8, compu-method=none_1_0, data-constr=c08_0_255_1_SNA_na, transfer-property=PENDING, to ECU4_CRN(timeout 1 s)  # Sequenzzähler / Sequence counter
    signal Rsrv1_PT4_PTCoor_PT_Rdy_Pr5_ST3: start 31, 1 bit, little-endian, data-type-policy=OVERRIDE, i-signal-type=PRIMITIVE, init-value=1, base-type=uint8, data-constr=Rsrv01, transfer-property=PENDING, to ECU4_CRN  # Reserviert für zukünftige Verwendung / Reserved for future use
    mapping PT4_PTCoor4_Pr5_ST3_af4fxb1ykieox3itqdfzs0kpb: i-signal-group=PT4_PTCoor4_Pr5_ST3_af4fxb1ykieox3itqdfzs0kpb, packing-byte-order=little-endian, transfer-property=TRIGGERED-ON-CHANGE
  pdu VehSpd_8_ST3: length=4, transmission-mode-true-timing=cyclic-timing={time-offset=0.01, time-period=0.1}, unused-bit-pattern=255  # Fahrzeug Spd 8 Bit / Vehicle Spd 8 Bit
    signal CRC_VehSpd8_Pr5_ST3: start 0, 16 bit, little-endian, data-type-policy=OVERRIDE, i-signal-type=PRIMITIVE, init-value=19913, base-type=uint16, data-constr=c16_CRC_woSNA, to ECU4_CRN  # CRC-Checksumme der Signal Gruppe gemäß AUTOSAR Profil 5 / CRC-checksum of signal group according to AUTOSAR Profile 5
    signal SQC_VehSpd8_Pr5_ST3: start 16, 8 bit, little-endian, data-type-policy=OVERRIDE, i-signal-type=PRIMITIVE, init-value=0, base-type=uint8, compu-method=none_1_0, data-constr=c08_0_255_1_SNA_na, to ECU4_CRN  # Sequenzzähler / Sequence counter
    signal VehSpd8_ST3: start 24, 8 bit, little-endian, data-type-policy=OVERRIDE, i-signal-type=PRIMITIVE, init-value=255, base-type=uint8, invalid-value=255, compu-method=c08_km_p_h_0_254_1, data-constr=c08_km_p_h_0_254_1, to ECU4_CRN  # Eigengeschwindigkeit Fahrzeug / Vehicle speed
    mapping VehSpd8_Pr5_ST3_168m1ogyookfwuxfakr38tbmv: i-signal-group=VehSpd8_Pr5_ST3_168m1ogyookfwuxfakr38tbmv, packing-byte-order=little-endian, transfer-property=PENDING
  pdu VSS_TP_Auth_ST3: length=8, minimum-delay=0.02, transmission-mode-true-timing=event-controlled-timing=number-of-repetitions=0, unused-bit-pattern=255  # VSS-Transportprotokoll für Authentifizierung / Vehicle Security System Transport Protocol for authentication broadcast
    signal VSS_TP_Auth_0_ST3: start 0, 8 bit, little-endian, data-type-policy=OVERRIDE, i-signal-type=PRIMITIVE, init-value=255, base-type=uint8, data-constr=c08_UInt_SNA_na, to ECU4_CRN  # VSS-Transportprotokoll für Authentifizierung, Byte 0 / Vehicle Security System Transport Protocol for authentication broadcast, Byte 0
    signal VSS_TP_Auth_1_ST3: start 8, 8 bit, little-endian, data-type-policy=OVERRIDE, i-signal-type=PRIMITIVE, init-value=255, base-type=uint8, data-constr=c08_UInt_SNA_na, to ECU4_CRN  # VSS-Transportprotokoll für Authentifizierung, Byte 1 / Vehicle Security System Transport Protocol for authentication broadcast, Byte 1
    signal VSS_TP_Auth_2_ST3: start 16, 8 bit, little-endian, data-type-policy=OVERRIDE, i-signal-type=PRIMITIVE, init-value=255, base-type=uint8, data-constr=c08_UInt_SNA_na, to ECU4_CRN  # VSS-Transportprotokoll für Authentifizierung, Byte 2 / Vehicle Security System Transport Protocol for authentication broadcast, Byte 2
    signal VSS_TP_Auth_3_ST3: start 24, 8 bit, little-endian, data-type-policy=OVERRIDE, i-signal-type=PRIMITIVE, init-value=255, base-type=uint8, data-constr=c08_UInt_SNA_na, to ECU4_CRN  # VSS-Transportprotokoll für Authentifizierung, Byte 3 / Vehicle Security System Transport Protocol for authentication broadcast, Byte 3
    signal VSS_TP_Auth_4_ST3: start 32, 8 bit, little-endian, data-type-policy=OVERRIDE, i-signal-type=PRIMITIVE, init-value=255, base-type=uint8, data-constr=c08_UInt_SNA_na, to ECU4_CRN  # VSS-Transportprotokoll für Authentifizierung, Byte 4 / Vehicle Security System Transport Protocol for authentication broadcast, Byte 4
    signal VSS_TP_Auth_5_ST3: start 40, 8 bit, little-endian, data-type-policy=OVERRIDE, i-signal-type=PRIMITIVE, init-value=255, base-type=uint8, data-constr=c08_UInt_SNA_na, to ECU4_CRN  # VSS-Transportprotokoll für Authentifizierung, Byte 5 / Vehicle Security System Transport Protocol for authentication broadcast, Byte 5
    signal VSS_TP_Auth_6_ST3: start 48, 8 bit, little-endian, data-type-policy=OVERRIDE, i-signal-type=PRIMITIVE, init-value=255, base-type=uint8, data-constr=c08_UInt_SNA_na, to ECU4_CRN  # VSS-Transportprotokoll für Authentifizierung, Byte 6 / Vehicle Security System Transport Protocol for authentication broadcast, Byte 6
    signal VSS_TP_Auth_7_ST3: start 56, 8 bit, little-endian, data-type-policy=OVERRIDE, i-signal-type=PRIMITIVE, init-value=255, base-type=uint8, data-constr=c08_UInt_SNA_na, to ECU4_CRN  # VSS-Transportprotokoll für Authentifizierung, Byte 7 / Vehicle Security System Transport Protocol for authentication broadcast, Byte 7
    mapping VSS_TP_Auth_ST3_6j4id7sghlvlbroli4wjozjik: i-signal-group=VSS_TP_Auth_ST3/VSS_TP_Auth_ST3_6j4id7sghlvlbroli4wjozjik, packing-byte-order=little-endian, transfer-property=TRIGGERED
  pdu VSS_TP_RealTmOffset_ST3: length=8, minimum-delay=0.02, transmission-mode-true-timing=event-controlled-timing=number-of-repetitions=0, unused-bit-pattern=255  # VSS-Transportprotokoll für Echtzeit-Offset / Vehicle Security System Transport Protocol for real time offset broadcast
    signal VSS_TP_RealTmOffset_0_ST3: start 0, 8 bit, little-endian, data-type-policy=OVERRIDE, i-signal-type=PRIMITIVE, init-value=255, base-type=uint8, data-constr=c08_UInt_SNA_na, to ECU4_CRN  # VSS-Transportprotokoll für Echtzeit-Offset, Byte 0 / Vehicle Security System Transport Protocol for real time offset broadcast, Byte 0
    signal VSS_TP_RealTmOffset_1_ST3: start 8, 8 bit, little-endian, data-type-policy=OVERRIDE, i-signal-type=PRIMITIVE, init-value=255, base-type=uint8, data-constr=c08_UInt_SNA_na, to ECU4_CRN  # VSS-Transportprotokoll für Echtzeit-Offset, Byte 1 / Vehicle Security System Transport Protocol for real time offset broadcast, Byte 1
    signal VSS_TP_RealTmOffset_2_ST3: start 16, 8 bit, little-endian, data-type-policy=OVERRIDE, i-signal-type=PRIMITIVE, init-value=255, base-type=uint8, data-constr=c08_UInt_SNA_na, to ECU4_CRN  # VSS-Transportprotokoll für Echtzeit-Offset, Byte 2 / Vehicle Security System Transport Protocol for real time offset broadcast, Byte 2
    signal VSS_TP_RealTmOffset_3_ST3: start 24, 8 bit, little-endian, data-type-policy=OVERRIDE, i-signal-type=PRIMITIVE, init-value=255, base-type=uint8, data-constr=c08_UInt_SNA_na, to ECU4_CRN  # VSS-Transportprotokoll für Echtzeit-Offset, Byte 3 / Vehicle Security System Transport Protocol for real time offset broadcast, Byte 3
    signal VSS_TP_RealTmOffset_4_ST3: start 32, 8 bit, little-endian, data-type-policy=OVERRIDE, i-signal-type=PRIMITIVE, init-value=255, base-type=uint8, data-constr=c08_UInt_SNA_na, to ECU4_CRN  # VSS-Transportprotokoll für Echtzeit-Offset, Byte 4 / Vehicle Security System Transport Protocol for real time offset broadcast, Byte 4
    signal VSS_TP_RealTmOffset_5_ST3: start 40, 8 bit, little-endian, data-type-policy=OVERRIDE, i-signal-type=PRIMITIVE, init-value=255, base-type=uint8, data-constr=c08_UInt_SNA_na, to ECU4_CRN  # VSS-Transportprotokoll für Echtzeit-Offset, Byte 5 / Vehicle Security System Transport Protocol for real time offset broadcast, Byte 5
    signal VSS_TP_RealTmOffset_6_ST3: start 48, 8 bit, little-endian, data-type-policy=OVERRIDE, i-signal-type=PRIMITIVE, init-value=255, base-type=uint8, data-constr=c08_UInt_SNA_na, to ECU4_CRN  # VSS-Transportprotokoll für Echtzeit-Offset, Byte 6 / Vehicle Security System Transport Protocol for real time offset broadcast, Byte 6
    signal VSS_TP_RealTmOffset_7_ST3: start 56, 8 bit, little-endian, data-type-policy=OVERRIDE, i-signal-type=PRIMITIVE, init-value=255, base-type=uint8, data-constr=c08_UInt_SNA_na, to ECU4_CRN  # VSS-Transportprotokoll für Echtzeit-Offset, Byte 7 / Vehicle Security System Transport Protocol for real time offset broadcast, Byte 7
    mapping VSS_TP_RealTmOffset_ST3_1t7vc44gftc0wv35k5kgc2in9: i-signal-group=VSS_TP_RealTmOffset_ST3/VSS_TP_RealTmOffset_ST3_1t7vc44gftc0wv35k5kgc2in9, packing-byte-order=little-endian, transfer-property=TRIGGERED
  pdu VSS_TP_SecTickCount_Lvl1_ST3: length=8, minimum-delay=0.02, transmission-mode-true-timing=event-controlled-timing=number-of-repetitions=0, unused-bit-pattern=255  # VSS-Transportprotokoll für sichere Zeit Stufe 1 / Vehicle Security System Transport Protocol for secure tick count level #1
    signal VSS_TP_SecTickCount_Lvl1_0_ST3: start 0, 8 bit, little-endian, data-type-policy=OVERRIDE, i-signal-type=PRIMITIVE, init-value=255, base-type=uint8, data-constr=c08_UInt_SNA_na, to ECU4_CRN  # VSS-Transportprotokoll für sichere Zeit Stufe 1, Byte 0 / Vehicle Security System Transport Protocol for secure tick count level #1, Byte 0
    signal VSS_TP_SecTickCount_Lvl1_1_ST3: start 8, 8 bit, little-endian, data-type-policy=OVERRIDE, i-signal-type=PRIMITIVE, init-value=255, base-type=uint8, data-constr=c08_UInt_SNA_na, to ECU4_CRN  # VSS-Transportprotokoll für sichere Zeit Stufe 1, Byte 1 / Vehicle Security System Transport Protocol for secure tick count level #1, Byte 1
    signal VSS_TP_SecTickCount_Lvl1_2_ST3: start 16, 8 bit, little-endian, data-type-policy=OVERRIDE, i-signal-type=PRIMITIVE, init-value=255, base-type=uint8, data-constr=c08_UInt_SNA_na, to ECU4_CRN  # VSS-Transportprotokoll für sichere Zeit Stufe 1, Byte 2 / Vehicle Security System Transport Protocol for secure tick count level #1, Byte 2
    signal VSS_TP_SecTickCount_Lvl1_3_ST3: start 24, 8 bit, little-endian, data-type-policy=OVERRIDE, i-signal-type=PRIMITIVE, init-value=255, base-type=uint8, data-constr=c08_UInt_SNA_na, to ECU4_CRN  # VSS-Transportprotokoll für sichere Zeit Stufe 1, Byte 3 / Vehicle Security System Transport Protocol for secure tick count level #1, Byte 3
    signal VSS_TP_SecTickCount_Lvl1_4_ST3: start 32, 8 bit, little-endian, data-type-policy=OVERRIDE, i-signal-type=PRIMITIVE, init-value=255, base-type=uint8, data-constr=c08_UInt_SNA_na, to ECU4_CRN  # VSS-Transportprotokoll für sichere Zeit Stufe 1, Byte 4 / Vehicle Security System Transport Protocol for secure tick count level #1, Byte 4
    signal VSS_TP_SecTickCount_Lvl1_5_ST3: start 40, 8 bit, little-endian, data-type-policy=OVERRIDE, i-signal-type=PRIMITIVE, init-value=255, base-type=uint8, data-constr=c08_UInt_SNA_na, to ECU4_CRN  # VSS-Transportprotokoll für sichere Zeit Stufe 1, Byte 5 / Vehicle Security System Transport Protocol for secure tick count level #1, Byte 5
    signal VSS_TP_SecTickCount_Lvl1_6_ST3: start 48, 8 bit, little-endian, data-type-policy=OVERRIDE, i-signal-type=PRIMITIVE, init-value=255, base-type=uint8, data-constr=c08_UInt_SNA_na, to ECU4_CRN  # VSS-Transportprotokoll für sichere Zeit Stufe 1, Byte 6 / Vehicle Security System Transport Protocol for secure tick count level #1, Byte 6
    signal VSS_TP_SecTickCount_Lvl1_7_ST3: start 56, 8 bit, little-endian, data-type-policy=OVERRIDE, i-signal-type=PRIMITIVE, init-value=255, base-type=uint8, data-constr=c08_UInt_SNA_na, to ECU4_CRN  # VSS-Transportprotokoll für sichere Zeit Stufe 1, Byte 7 / Vehicle Security System Transport Protocol for secure tick count level #1, Byte 7
    mapping VSS_TP_SecTickCount_Lvl1_ST3_mzmfdqtqz5kvv1kfpvg0kql3: i-signal-group=VSS_TP_SecTickCount_Lvl1_ST3_mzmfdqtqz5kvv1kfpvg0kql3, packing-byte-order=little-endian, transfer-property=TRIGGERED
  pdu VSS_TP_SharedSecret_ST3: length=8, minimum-delay=0.02, transmission-mode-true-timing=event-controlled-timing=number-of-repetitions=0, unused-bit-pattern=255  # VSS-Transportprotokoll für gemeinsames Geheimnis / Vehicle Security System Transport Protocol for shared secret broadcast
    signal VSS_TP_SharedSecret_0_ST3: start 0, 8 bit, little-endian, data-type-policy=OVERRIDE, i-signal-type=PRIMITIVE, init-value=255, base-type=uint8, data-constr=c08_UInt_SNA_na, to ECU4_CRN  # VSS-Transportprotokoll für gemeinsames Geheimnis, Byte 0 / Vehicle Security System Transport Protocol for shared secret broadcast, Byte 0
    signal VSS_TP_SharedSecret_1_ST3: start 8, 8 bit, little-endian, data-type-policy=OVERRIDE, i-signal-type=PRIMITIVE, init-value=255, base-type=uint8, data-constr=c08_UInt_SNA_na, to ECU4_CRN  # VSS-Transportprotokoll für gemeinsames Geheimnis, Byte 1 / Vehicle Security System Transport Protocol for shared secret broadcast, Byte 1
    signal VSS_TP_SharedSecret_2_ST3: start 16, 8 bit, little-endian, data-type-policy=OVERRIDE, i-signal-type=PRIMITIVE, init-value=255, base-type=uint8, data-constr=c08_UInt_SNA_na, to ECU4_CRN  # VSS-Transportprotokoll für gemeinsames Geheimnis, Byte 2 / Vehicle Security System Transport Protocol for shared secret broadcast, Byte 2
    signal VSS_TP_SharedSecret_3_ST3: start 24, 8 bit, little-endian, data-type-policy=OVERRIDE, i-signal-type=PRIMITIVE, init-value=255, base-type=uint8, data-constr=c08_UInt_SNA_na, to ECU4_CRN  # VSS-Transportprotokoll für gemeinsames Geheimnis, Byte 3 / Vehicle Security System Transport Protocol for shared secret broadcast, Byte 3
    signal VSS_TP_SharedSecret_4_ST3: start 32, 8 bit, little-endian, data-type-policy=OVERRIDE, i-signal-type=PRIMITIVE, init-value=255, base-type=uint8, data-constr=c08_UInt_SNA_na, to ECU4_CRN  # VSS-Transportprotokoll für gemeinsames Geheimnis, Byte 4 / Vehicle Security System Transport Protocol for shared secret broadcast, Byte 4
    signal VSS_TP_SharedSecret_5_ST3: start 40, 8 bit, little-endian, data-type-policy=OVERRIDE, i-signal-type=PRIMITIVE, init-value=255, base-type=uint8, data-constr=c08_UInt_SNA_na, to ECU4_CRN  # VSS-Transportprotokoll für gemeinsames Geheimnis, Byte 5 / Vehicle Security System Transport Protocol for shared secret broadcast, Byte 5
    signal VSS_TP_SharedSecret_6_ST3: start 48, 8 bit, little-endian, data-type-policy=OVERRIDE, i-signal-type=PRIMITIVE, init-value=255, base-type=uint8, data-constr=c08_UInt_SNA_na, to ECU4_CRN  # VSS-Transportprotokoll für gemeinsames Geheimnis, Byte 6 / Vehicle Security System Transport Protocol for shared secret broadcast, Byte 6
    signal VSS_TP_SharedSecret_7_ST3: start 56, 8 bit, little-endian, data-type-policy=OVERRIDE, i-signal-type=PRIMITIVE, init-value=255, base-type=uint8, data-constr=c08_UInt_SNA_na, to ECU4_CRN  # VSS-Transportprotokoll für gemeinsames Geheimnis, Byte 7 / Vehicle Security System Transport Protocol for shared secret broadcast, Byte 7
    mapping VSS_TP_SharedSecret_ST3_8pj4t8t4rm3tw3pk5hj7vonti: i-signal-group=VSS_TP_SharedSecret_ST3/VSS_TP_SharedSecret_ST3_8pj4t8t4rm3tw3pk5hj7vonti, packing-byte-order=little-endian, transfer-property=TRIGGERED
  pdu VSS_TP_VIN_ST3: length=8, minimum-delay=0.02, transmission-mode-true-timing=event-controlled-timing=number-of-repetitions=0, unused-bit-pattern=255  # VSS-Transportprotokoll für Fahrzeugidentifikationsnummer / Vehicle Security System Transport Protocol for Vehicle Identification Number
    signal VSS_TP_VIN_0_ST3: start 0, 8 bit, little-endian, data-type-policy=OVERRIDE, i-signal-type=PRIMITIVE, init-value=63, base-type=uint8, data-constr=c08_UInt_SNA_na, to ECU4_CRN  # VSS-Transportprotokoll für Fahrzeugidentifikationsnummer, Byte 0 / Vehicle Security System Transport Protocol for Vehicle Identification Number, Byte 0
    signal VSS_TP_VIN_1_ST3: start 8, 8 bit, little-endian, data-type-policy=OVERRIDE, i-signal-type=PRIMITIVE, init-value=63, base-type=uint8, data-constr=c08_UInt_SNA_na, to ECU4_CRN  # VSS-Transportprotokoll für Fahrzeugidentifikationsnummer, Byte 1 / Vehicle Security System Transport Protocol for Vehicle Identification Number, Byte 1
    signal VSS_TP_VIN_2_ST3: start 16, 8 bit, little-endian, data-type-policy=OVERRIDE, i-signal-type=PRIMITIVE, init-value=63, base-type=uint8, data-constr=c08_UInt_SNA_na, to ECU4_CRN  # VSS-Transportprotokoll für Fahrzeugidentifikationsnummer, Byte 2 / Vehicle Security System Transport Protocol for Vehicle Identification Number, Byte 2
    signal VSS_TP_VIN_3_ST3: start 24, 8 bit, little-endian, data-type-policy=OVERRIDE, i-signal-type=PRIMITIVE, init-value=63, base-type=uint8, data-constr=c08_UInt_SNA_na, to ECU4_CRN  # VSS-Transportprotokoll für Fahrzeugidentifikationsnummer, Byte 3 / Vehicle Security System Transport Protocol for Vehicle Identification Number, Byte 3
    signal VSS_TP_VIN_4_ST3: start 32, 8 bit, little-endian, data-type-policy=OVERRIDE, i-signal-type=PRIMITIVE, init-value=63, base-type=uint8, data-constr=c08_UInt_SNA_na, to ECU4_CRN  # VSS-Transportprotokoll für Fahrzeugidentifikationsnummer, Byte 4 / Vehicle Security System Transport Protocol for Vehicle Identification Number, Byte 4
    signal VSS_TP_VIN_5_ST3: start 40, 8 bit, little-endian, data-type-policy=OVERRIDE, i-signal-type=PRIMITIVE, init-value=63, base-type=uint8, data-constr=c08_UInt_SNA_na, to ECU4_CRN  # VSS-Transportprotokoll für Fahrzeugidentifikationsnummer, Byte 5 / Vehicle Security System Transport Protocol for Vehicle Identification Number, Byte 5
    signal VSS_TP_VIN_6_ST3: start 48, 8 bit, little-endian, data-type-policy=OVERRIDE, i-signal-type=PRIMITIVE, init-value=63, base-type=uint8, data-constr=c08_UInt_SNA_na, to ECU4_CRN  # VSS-Transportprotokoll für Fahrzeugidentifikationsnummer, Byte 6 / Vehicle Security System Transport Protocol for Vehicle Identification Number, Byte 6
    signal VSS_TP_VIN_7_ST3: start 56, 8 bit, little-endian, data-type-policy=OVERRIDE, i-signal-type=PRIMITIVE, init-value=63, base-type=uint8, data-constr=c08_UInt_SNA_na, to ECU4_CRN  # VSS-Transportprotokoll für Fahrzeugidentifikationsnummer, Byte 7 / Vehicle Security System Transport Protocol for Vehicle Identification Number, Byte 7
    mapping VSS_TP_VIN_ST3_bz1xsv84cxzl09j028gn39p69: i-signal-group=VSS_TP_VIN_ST3/VSS_TP_VIN_ST3_bz1xsv84cxzl09j028gn39p69, packing-byte-order=little-endian, transfer-property=TRIGGERED
  secured i pdu COM_C04_Pdu03_secured: length=3017, authentication-props=SECOC_AP_CMAC_AES_128_24, freshness-props=SECOC_FP_10000_40_8_true, payload=COM_C04_Pdu03_bpm1c6e6o44uhe1w6yumyf8wa, secure-communication-props={authentication-retries=0, data-id=24029, freshness-value-id=1}
  secured i pdu COM_C04_Pdu20_secured: length=19, authentication-props=SECOC_AP_CMAC_AES_128_24, freshness-props=SECOC_FP_10000_40_8_true, payload=COM_C04_Pdu20_9id8jbpo37ngpr9vzagg7wxtz, secure-communication-props={authentication-retries=0, data-id=41925, freshness-value-id=1}
  secured i pdu COM_C04_Pdu21_secured: length=13, authentication-props=SECOC_AP_CMAC_AES_128_24, freshness-props=SECOC_FP_10000_40_8_true, payload=COM_C04_Pdu21_483xtibj7phlywn0mrpsj0p4u, secure-communication-props={authentication-retries=0, data-id=38145, freshness-value-id=1}
  secured i pdu COM_C0X_Pdu21_secured: length=13, authentication-props=SECOC_AP_CMAC_AES_128_24, freshness-props=SECOC_FP_10000_40_8_true, payload=COM_C0X_Pdu21_bm3n8flkrwzfl90nw3nm3vvzs, secure-communication-props={authentication-retries=0, data-id=3394, freshness-value-id=1}
  secured i pdu COM_C0X_Pdu20_secured: length=19, authentication-props=SECOC_AP_CMAC_AES_128_24, freshness-props=SECOC_FP_10000_40_8_true, payload=COM_C0X_Pdu20_dqc5kce35r6zcc0zkw8xmpfiv, secure-communication-props={authentication-retries=0, data-id=43676, freshness-value-id=1}
  secured i pdu DI_OdoSpeedometer_ST3_secured: length=12, authentication-props=SECOC_AP_CMAC_AES_128_24, freshness-props=SECOC_FP_10000_40_8_true, payload=DI_OdoSpeedometer_ST3_7jb3acjj567zcinfjaciyzmox, secure-communication-props={authentication-retries=0, data-id=64886, freshness-value-id=1}
  secured i pdu Ign_Stat_ST3_secured: length=8, authentication-props=SECOC_AP_CMAC_AES_128_24, freshness-props=SECOC_FP_10000_40_8_true, payload=Ign_Stat_ST3_30i7ve981yksfyg7upd5w1x1e, secure-communication-props={authentication-retries=0, data-id=28212, freshness-value-id=1}
  secured i pdu PN14_Master_Stat1_ST3_secured: length=12, authentication-props=SECOC_AP_CMAC_AES_128_24, freshness-props=SECOC_FP_10000_40_8_true, payload=PN14_Master_Stat1_ST3_1c1yt5wkb7eltvmd1nhzl575e, secure-communication-props={authentication-retries=0, data-id=57668, freshness-value-id=1}
  secured i pdu PT4_PTCoor4_ST3_secured: length=8, authentication-props=SECOC_AP_CMAC_AES_128_24, freshness-props=SECOC_FP_10000_40_8_true, payload=PT4_PTCoor4_ST3_1rx6hv5wn01u44037z5f7jia2, secure-communication-props={authentication-retries=0, data-id=26743, freshness-value-id=1}
  secured i pdu VehSpd_8_ST3_secured: length=8, authentication-props=SECOC_AP_CMAC_AES_128_24, freshness-props=SECOC_FP_10000_40_8_true, payload=VehSpd_8_ST3_rw4rwzepv4zq3afl7px8fqvx, secure-communication-props={authentication-retries=0, data-id=47310, freshness-value-id=1}
  general purpose pdu SD_Ctrl_Rx: category=SD, length=1472
  general purpose pdu SD_Ctrl_Rx_Multicast: category=SD, length=1472
  general purpose pdu SD_Ctrl_Tx: category=SD, length=1472
package /Pdus/Eth_Cluster4/PKG_Eth_Cluster4_2
  general purpose pdu DIAG_RQ_Eth_CTP: category=DoIP, length=1472  # DIAG RQ Eth 01
  general purpose pdu DIAG_RS_Eth_CTP: category=DoIP, length=1472  # DIAG RS Eth 01
  dcm i pdu SDU_DIAG_RQ_IntEth_MAIN_ONBD_ST3_ECU04_C04: length=1500, diag-pdu-type=DIAG-REQUEST
  dcm i pdu SDU_DIAG_RQ_IntEth_MAIN_ONBD_ST3_ECU04_C10: length=1500, diag-pdu-type=DIAG-REQUEST
  dcm i pdu SDU_DIAG_RQ_IntEth_MAIN_ONBD_ST3_ECU04_C19: length=1500, diag-pdu-type=DIAG-REQUEST
  dcm i pdu SDU_DIAG_RQ_IntEth_MAIN_ONBD_ST3_ECU04_GLOBAL: length=1500, diag-pdu-type=DIAG-REQUEST
  dcm i pdu SDU_DIAG_RQ_IntEth_MAIN_ONBD_ST3_ECU04_Lin_S5: length=1500, diag-pdu-type=DIAG-REQUEST
  dcm i pdu SDU_DIAG_RS_IntEth_MAIN_ONBD_ST3_ECU04_C04: length=1500, diag-pdu-type=DIAG-RESPONSE
  dcm i pdu SDU_DIAG_RS_IntEth_MAIN_ONBD_ST3_ECU04_C10: length=1500, diag-pdu-type=DIAG-RESPONSE
  dcm i pdu SDU_DIAG_RS_IntEth_MAIN_ONBD_ST3_ECU04_C19: length=1500, diag-pdu-type=DIAG-RESPONSE
  dcm i pdu SDU_DIAG_RS_IntEth_MAIN_ONBD_ST3_ECU04_Lin_S5: length=1500, diag-pdu-type=DIAG-RESPONSE
  general purpose pdu DIAG_RS_Eth_CTP_TCP: category=DoIP, length=1512
  general purpose pdu DIAG_RQ_Eth_CTP_TCP: category=DoIP, length=1512
  general purpose pdu DIAG_RQ_Eth_CTP_TCP_2: category=DoIP, length=1512
  general purpose pdu DIAG_RS_Eth_CTP_TCP_2: category=DoIP, length=1512
  general purpose pdu DIAG_RQ_Eth_CTP_2: category=DoIP, length=1472  # DIAG RQ Eth 01
  general purpose pdu DIAG_RS_Eth_CTP_2: category=DoIP, length=1472  # DIAG RS Eth 01
package /Pdus/Eth_Cluster4/PKG_Eth_Cluster4_2/DIAG_C01_ONBD_Container_ST3
  pdu DIAG_C01_ONBD_Container_ST3_DIAG_Stat_ST3: length=4, minimum-delay=0.04, transmission-mode-true-timing={cyclic-timing={time-offset=0.01, time-period=1}, event-controlled-timing=number-of-repetitions=0}, unused-bit-pattern=255  # Actv Line Status Tester pres / Actv Line state Tester pres
    signal Actv_Line_Stat_ST3: start 0, 2 bit, little-endian, data-type-policy=OVERRIDE, i-signal-type=PRIMITIVE, init-value=0, base-type=uint8, invalid-value=3, compu-method=c02_Inact_Act_ST3, data-constr=c02_Inact_Act_ST3, transfer-property=TRIGGERED-ON-CHANGE, to ECU4_CRN  # Aktivierungs Leitungsstatus / Activation Line state
    signal DidA_ExtTest_Pres_ST3: start 2, 2 bit, little-endian, data-type-policy=OVERRIDE, i-signal-type=PRIMITIVE, init-value=3, base-type=uint8, invalid-value=3, compu-method=c02_Ndef_False_True_ST3, data-constr=c02_Ndef_False_True_ST3, transfer-property=TRIGGERED-ON-CHANGE, to ECU4_CRN  # DidA Externer Tester erkannt / DidA external tester present
package /Pdus/Eth_Cluster4/PKG_Eth_Cluster4_1
  general purpose pdu DIAG_RQ_Eth_CTP: category=DoIP, length=1472  # DIAG RQ Eth 01
  general purpose pdu DIAG_RS_Eth_CTP: category=DoIP, length=1472  # DIAG RS Eth 01
  dcm i pdu SDU_DIAG_RQ_ExtEth_MAIN_OFBD_ST3_ECU04_C04: length=1500, diag-pdu-type=DIAG-REQUEST
  dcm i pdu SDU_DIAG_RQ_ExtEth_MAIN_OFBD_ST3_ECU04_C10: length=1500, diag-pdu-type=DIAG-REQUEST
  dcm i pdu SDU_DIAG_RQ_ExtEth_MAIN_OFBD_ST3_ECU04_C19: length=1500, diag-pdu-type=DIAG-REQUEST
  dcm i pdu SDU_DIAG_RQ_ExtEth_MAIN_OFBD_ST3_ECU04_GLOBAL: length=1500, diag-pdu-type=DIAG-REQUEST
  dcm i pdu SDU_DIAG_RQ_ExtEth_MAIN_OFBD_ST3_ECU04_Lin_S5: length=1500, diag-pdu-type=DIAG-REQUEST
  dcm i pdu SDU_DIAG_RS_ExtEth_MAIN_OFBD_ST3_ECU04_C04: length=1500, diag-pdu-type=DIAG-RESPONSE
  dcm i pdu SDU_DIAG_RS_ExtEth_MAIN_OFBD_ST3_ECU04_C10: length=1500, diag-pdu-type=DIAG-RESPONSE
  dcm i pdu SDU_DIAG_RS_ExtEth_MAIN_OFBD_ST3_ECU04_C19: length=1500, diag-pdu-type=DIAG-RESPONSE
  dcm i pdu SDU_DIAG_RS_ExtEth_MAIN_OFBD_ST3_ECU04_Lin_S5: length=1500, diag-pdu-type=DIAG-RESPONSE
  general purpose pdu DIAG_RS_Eth_CTP_TCP: category=DoIP, length=1512
  general purpose pdu DIAG_RQ_Eth_CTP_TCP: category=DoIP, length=1512
  general purpose pdu DIAG_RS_Eth_CTP_TCP_2: category=DoIP, length=1512
  general purpose pdu DIAG_RQ_Eth_CTP_TCP_2: category=DoIP, length=1512
  general purpose pdu DIAG_RS_Eth_CTP_2: category=DoIP, length=1472  # DIAG RS Eth 01
  general purpose pdu DIAG_RQ_Eth_CTP_2: category=DoIP, length=1472  # DIAG RQ Eth 01
package /Pdus/Eth_Cluster4/PKG_Eth_Cluster4_1/DIAG_ROE_C04_Container_ST3
  pdu DIAG_ROE_C04_Container_ST3_ROE_C04_PDU01: length=8, minimum-delay=0.2, transmission-mode-true-timing=event-controlled-timing=number-of-repetitions=0, unused-bit-pattern=255  # Diag Ro E C14 PDU01
    signal Diag_RoE_C04_Sig00: start 0, 8 bit, little-endian, data-type-policy=OVERRIDE, i-signal-type=PRIMITIVE, init-value=0, base-type=uint8, compu-method=c08_ROE_0, data-constr=c08_ROE_0  # Diag Ro E C14 Sig 00
    signal Diag_RoE_C04_Sig01: start 8, 8 bit, little-endian, data-type-policy=OVERRIDE, i-signal-type=PRIMITIVE, init-value=255, base-type=uint8, data-constr=c08_UInt_SNA_na  # Diag RoE C14 Sig 01
    signal Diag_RoE_C04_Sig02: start 16, 8 bit, little-endian, data-type-policy=OVERRIDE, i-signal-type=PRIMITIVE, init-value=255, base-type=uint8, data-constr=c08_UInt_SNA_na  # Diag RoE C14 Sig 02
    signal Diag_RoE_C04_Sig03: start 24, 8 bit, little-endian, data-type-policy=OVERRIDE, i-signal-type=PRIMITIVE, init-value=255, base-type=uint8, data-constr=c08_UInt_SNA_na  # Diag RoE C14 Sig 03
    signal Diag_RoE_C04_Sig04: start 32, 8 bit, little-endian, data-type-policy=OVERRIDE, i-signal-type=PRIMITIVE, init-value=255, base-type=uint8, data-constr=c08_UInt_SNA_na  # Diag RoE C14 Sig 04
    signal Diag_RoE_C04_Sig05: start 40, 8 bit, little-endian, data-type-policy=OVERRIDE, i-signal-type=PRIMITIVE, init-value=255, base-type=uint8, data-constr=c08_UInt_SNA_na  # Diag RoE C14 Sig 05
    signal Diag_RoE_C04_Sig06: start 48, 8 bit, little-endian, data-type-policy=OVERRIDE, i-signal-type=PRIMITIVE, init-value=255, base-type=uint8, data-constr=c08_UInt_SNA_na  # Diag RoE C14 Sig 06
    signal Diag_RoE_C04_Sig07: start 56, 8 bit, little-endian, data-type-policy=OVERRIDE, i-signal-type=PRIMITIVE, init-value=255, base-type=uint8, data-constr=c08_UInt_SNA_na  # Diag RoE C14 Sig 07
    mapping Diag_RoE_C04_SigGrp01_2ksq5hjijyze6lf3nboiafq6k: i-signal-group=Diag_RoE_C04_SigGrp01_2ksq5hjijyze6lf3nboiafq6k, packing-byte-order=little-endian, transfer-property=TRIGGERED
package /Pdus/Eth_Cluster4/PKG_Eth_Cluster4_127
  nm pdu NM_C04: length=8, nm-data-information=true, unused-bit-pattern=0  # NM C04
    signal NM_C04_PNC: start 8, 56 bit, opaque, data-type-policy=OVERRIDE, i-signal-type=ARRAY, init-value=7 x 0, base-type=uint8, transfer-property=PENDING  # PNC_Vector
  nm pdu NM_Dummy__ST3: length=8, nm-data-information=true, unused-bit-pattern=0  # NM_Dummy_ST3
    signal NM_Dummy__ST3_PNC: start 8, 56 bit, opaque, data-type-policy=OVERRIDE, i-signal-type=ARRAY, init-value=7 x 0, base-type=uint8, transfer-property=PENDING  # PNC_Vector
package /Pdus/Eth_Cluster4/PKG_Eth_Cluster4_127/ECU_Stat_C04_ETH_Container
  pdu ECU_Stat_C04_ETH_Container_ECU_Stat_C04_ETH: length=8, transmission-mode-true-timing=cyclic-timing={time-offset=0, time-period=1}, unused-bit-pattern=255
    signal Awake_Diag_Actv_ECU4: start 30, 1 bit, little-endian, data-type-policy=OVERRIDE, i-signal-type=PRIMITIVE, init-value=1, base-type=boolean, transfer-property=PENDING
    signal Awake_Ignition_On_C04: start 32, 1 bit, little-endian, data-type-policy=OVERRIDE, i-signal-type=PRIMITIVE, init-value=1, base-type=boolean, transfer-property=PENDING
    signal Awake_NwStart_Cluster_ECU4: start 31, 1 bit, little-endian, data-type-policy=OVERRIDE, i-signal-type=PRIMITIVE, init-value=0, base-type=boolean, transfer-property=PENDING
    signal ECU_ID_C04: start 0, 12 bit, little-endian, data-type-policy=OVERRIDE, i-signal-type=PRIMITIVE, init-value=4, base-type=uint16, invalid-value=4095, data-constr=c12_na_0_to_4095_1, transfer-property=PENDING
    signal NwId_C04_ETH_ECU4: start 12, 8 bit, little-endian, data-type-policy=OVERRIDE, i-signal-type=PRIMITIVE, init-value=4, base-type=uint8, invalid-value=255, data-constr=c08_na_0_to_255_1, transfer-property=PENDING  # Nw Id C04 ETH ECU4
    signal WakeupRsn_C04_ECU04: start 20, 10 bit, little-endian, data-type-policy=OVERRIDE, i-signal-type=PRIMITIVE, init-value=1023, base-type=uint16, invalid-value=1023, compu-method=c10_WU_REASON_ECUx, data-constr=c10_WU_REASON_ECUx, transfer-property=PENDING
package /Pdus/LIN5_Cluster4/PKG_LIN5_Cluster4
  dcm i pdu DIAG_NAD_5_RQ_LIN5_Cluster4_ST3: length=4095
  dcm i pdu DIAG_NAD_5_RS_LIN5_Cluster4_ST3: length=4095
package /DataTransformations
  data transformation set DATATRANSFORMATION_SET
    5 x data transformation:
      BaseTrans_Profile_5_ImportedAdaptivePilot_4: execute-despite-data-unavailability=true, transformer-chain=[ComBasedTransformer4, E2E_Profile_5]  # Base Transformer Base Profile 5
      BaseTrans_Profile_5_ImportedAdaptivePilot_7: execute-despite-data-unavailability=true, transformer-chain=[ComBasedTransformer7, E2E_Profile_5]  # Base Transformer Base Profile 5
      SOME_IP_No_E2E_8Bit: execute-despite-data-unavailability=false, transformer-chain=SOME_IP_8Bit  # Only Some IP
      SOME_IP_Profile_6_8Bit: execute-despite-data-unavailability=true, transformer-chain=[SOME_IP_8Bit_Profile_6, E2E_Profile_6]  # Only Some IP
      BaseTrans_Profile_5_ImportedAdaptivePilot_6: execute-despite-data-unavailability=true, transformer-chain=[ComBasedTransformer6, E2E_Profile_5]  # Base Transformer Base Profile 5
    7 x transformation technology:
      ComBasedTransformer4: buffer-properties={buffer-computation=compu-rational-coeffs={compu-numerator=4, compu-denominator=1}, header-length=0, in-place=false}, protocol=COMBased, transformer-class=SERIALIZER, version=1
      E2E_Profile_5:  # E2E Profile 5
        buffer-properties={header-length=0, in-place=true}
        needs-original-data=false
        protocol=E2E
        end-to-end-transformation-description{max-delta-counter=3, max-error-state-init=0, max-error-state-invalid=0, max-error-state-valid=0, min-ok-state-init=1, min-ok-state-invalid=1, min-ok-state-valid=1, offset=0, profile-name=PROFILE_05, upper-header-bits-to-shift=0, window-size=10}
        transformer-class=SAFETY
        version=1.0.0
      ComBasedTransformer7: buffer-properties={buffer-computation=compu-rational-coeffs={compu-numerator=7, compu-denominator=1}, header-length=0, in-place=false}, protocol=COMBased, transformer-class=SERIALIZER, version=1
      SOME_IP_8Bit: buffer-properties={buffer-computation=compu-rational-coeffs={compu-numerator=[8, 1], compu-denominator=1}, header-length=64, in-place=false}, needs-original-data=false, protocol=SOMEIP, someip-transformation-description{alignment=8, byte-order=little-endian, interface-version=1}, transformer-class=SERIALIZER, version=1  # some IP transformer
      SOME_IP_8Bit_Profile_6: buffer-properties={buffer-computation=compu-rational-coeffs={compu-numerator=[13, 1], compu-denominator=1}, header-length=64, in-place=false}, needs-original-data=false, protocol=SOMEIP, someip-transformation-description{alignment=8, byte-order=little-endian, interface-version=1}, transformer-class=SERIALIZER, version=1  # some IP transformer for E2E Profile 6 (different Buffer Size Computation Scaling due to Buffer in Place @ Profile 6)
      E2E_Profile_6:  # E2E Profile 6
        buffer-properties={header-length=40, in-place=true}
        needs-original-data=false
        protocol=E2E
        end-to-end-transformation-description{max-delta-counter=3, max-error-state-init=0, max-error-state-invalid=0, max-error-state-valid=0, min-ok-state-init=1, min-ok-state-invalid=1, min-ok-state-valid=1, offset=64, profile-name=PROFILE_06, upper-header-bits-to-shift=64, window-size=10}
        transformer-class=SAFETY
        version=1.0.0
      ComBasedTransformer6: buffer-properties={buffer-computation=compu-rational-coeffs={compu-numerator=6, compu-denominator=1}, header-length=0, in-place=false}, protocol=COMBased, transformer-class=SERIALIZER, version=1
package /ISignalGroups/CAN1_Cluster4/PKG_CAN1_Cluster4/Ign_Stat_ST3
  i signal group Ign_Stat_Pr5_ST3_csgs1dv6drms80o1i9p49677w:  # Zuendungsstatus (degraded) / Ignition state (degraded)
    com-based-signal-group-transformations=BaseTrans_Profile_5_ImportedAdaptivePilot_4
    i-signal=[Ign_Stat_ST3/CRC_Ign_Stat_Pr5_ST3, Ign_Stat_ST3/ISw_Stat_ST3, Ign_Stat_ST3/KG_StartSw_Psd_ST3, Ign_Stat_ST3/SQC_Ign_Stat_Pr5_ST3, Ign_Stat_ST3/Veh_Op_Mode_ST3]
    system-signal-group=Ign_Stat_Pr5_ST3_csgs1dv6drms80o1i9p49677w
    end-to-end-transformation-i-signal-props{transformer=E2E_Profile_5, data-ids=51, data-length=32}
package /ISignalGroups/CAN1_Cluster4/PKG_CAN1_Cluster4/VSS_TP_Auth_ST3
  i signal group VSS_TP_Auth_ST3_6j4id7sghlvlbroli4wjozjik: i-signal=[VSS_TP_Auth_ST3/VSS_TP_Auth_0_ST3, VSS_TP_Auth_ST3/VSS_TP_Auth_1_ST3, VSS_TP_Auth_ST3/VSS_TP_Auth_2_ST3, VSS_TP_Auth_ST3/VSS_TP_Auth_3_ST3, VSS_TP_Auth_ST3/VSS_TP_Auth_4_ST3, VSS_TP_Auth_ST3/VSS_TP_Auth_5_ST3, VSS_TP_Auth_ST3/VSS_TP_Auth_6_ST3, VSS_TP_Auth_ST3/VSS_TP_Auth_7_ST3], system-signal-group=VSS_TP_Auth_ST3_6j4id7sghlvlbroli4wjozjik  # VSS-Transportprotokoll für Authentifizierung (degraded) / Vehicle Security System Transport Protocol for authentication broadcast (degraded)
package /ISignalGroups/CAN1_Cluster4/PKG_CAN1_Cluster4/VSS_TP_RealTmOffset_ST3
  i signal group VSS_TP_RealTmOffset_ST3_1t7vc44gftc0wv35k5kgc2in9: i-signal=[VSS_TP_RealTmOffset_ST3/VSS_TP_RealTmOffset_0_ST3, VSS_TP_RealTmOffset_ST3/VSS_TP_RealTmOffset_1_ST3, VSS_TP_RealTmOffset_ST3/VSS_TP_RealTmOffset_2_ST3, VSS_TP_RealTmOffset_ST3/VSS_TP_RealTmOffset_3_ST3, VSS_TP_RealTmOffset_ST3/VSS_TP_RealTmOffset_4_ST3, VSS_TP_RealTmOffset_ST3/VSS_TP_RealTmOffset_5_ST3, VSS_TP_RealTmOffset_ST3/VSS_TP_RealTmOffset_6_ST3, VSS_TP_RealTmOffset_ST3/VSS_TP_RealTmOffset_7_ST3], system-signal-group=VSS_TP_RealTmOffset_ST3_1t7vc44gftc0wv35k5kgc2in9  # VSS-Transportprotokoll für Echtzeit-Offset (degraded) / Vehicle Security System Transport Protocol for real time offset broadcast (degraded)
package /ISignalGroups/CAN1_Cluster4/PKG_CAN1_Cluster4/VSS_TP_SecTickCount_Lvl2_ST3
  i signal group VSS_TP_SecTickCount_Lvl2_ST3_9eubq13iosat764o0lqh5xb6r: i-signal=[VSS_TP_SecTickCount_Lvl2_ST3/VSS_TP_SecTickCount_Lvl2_0_ST3, VSS_TP_SecTickCount_Lvl2_ST3/VSS_TP_SecTickCount_Lvl2_1_ST3, VSS_TP_SecTickCount_Lvl2_ST3/VSS_TP_SecTickCount_Lvl2_2_ST3, VSS_TP_SecTickCount_Lvl2_ST3/VSS_TP_SecTickCount_Lvl2_3_ST3, VSS_TP_SecTickCount_Lvl2_ST3/VSS_TP_SecTickCount_Lvl2_4_ST3, VSS_TP_SecTickCount_Lvl2_ST3/VSS_TP_SecTickCount_Lvl2_5_ST3, VSS_TP_SecTickCount_Lvl2_ST3/VSS_TP_SecTickCount_Lvl2_6_ST3, VSS_TP_SecTickCount_Lvl2_ST3/VSS_TP_SecTickCount_Lvl2_7_ST3], system-signal-group=VSS_TP_SecTickCount_Lvl2_ST3_9eubq13iosat764o0lqh5xb6r  # VSS-Transportprotokoll für sichere Zeit Stufe 2 (degraded) / Vehicle Security System Transport Protocol for secure tick count level #2 (degraded)
package /ISignalGroups/CAN1_Cluster4/PKG_CAN1_Cluster4/VSS_TP_SharedSecret_ST3
  i signal group VSS_TP_SharedSecret_ST3_8pj4t8t4rm3tw3pk5hj7vonti: i-signal=[VSS_TP_SharedSecret_ST3/VSS_TP_SharedSecret_0_ST3, VSS_TP_SharedSecret_ST3/VSS_TP_SharedSecret_1_ST3, VSS_TP_SharedSecret_ST3/VSS_TP_SharedSecret_2_ST3, VSS_TP_SharedSecret_ST3/VSS_TP_SharedSecret_3_ST3, VSS_TP_SharedSecret_ST3/VSS_TP_SharedSecret_4_ST3, VSS_TP_SharedSecret_ST3/VSS_TP_SharedSecret_5_ST3, VSS_TP_SharedSecret_ST3/VSS_TP_SharedSecret_6_ST3, VSS_TP_SharedSecret_ST3/VSS_TP_SharedSecret_7_ST3], system-signal-group=VSS_TP_SharedSecret_ST3_8pj4t8t4rm3tw3pk5hj7vonti  # VSS-Transportprotokoll für gemeinsames Geheimnis (degraded) / Vehicle Security System Transport Protocol for shared secret broadcast (degraded)
package /ISignalGroups/CAN1_Cluster4/PKG_CAN1_Cluster4/VSS_TP_VIN_ST3
  i signal group VSS_TP_VIN_ST3_bz1xsv84cxzl09j028gn39p69: i-signal=[VSS_TP_VIN_ST3/VSS_TP_VIN_0_ST3, VSS_TP_VIN_ST3/VSS_TP_VIN_1_ST3, VSS_TP_VIN_ST3/VSS_TP_VIN_2_ST3, VSS_TP_VIN_ST3/VSS_TP_VIN_3_ST3, VSS_TP_VIN_ST3/VSS_TP_VIN_4_ST3, VSS_TP_VIN_ST3/VSS_TP_VIN_5_ST3, VSS_TP_VIN_ST3/VSS_TP_VIN_6_ST3, VSS_TP_VIN_ST3/VSS_TP_VIN_7_ST3], system-signal-group=VSS_TP_VIN_ST3_bz1xsv84cxzl09j028gn39p69  # VSS-Transportprotokoll für Fahrzeugidentifikationsnummer (degraded) / Vehicle Security System Transport Protocol for Vehicle Identification Number (degraded)
package /ISignalGroups/CANFD1_Cluster4/PKG_CANFD1_Cluster4/C04_CANFD_1_Container_ST3_Ign_Stat_ST3
  i signal group Ign_Stat_Pr5_ST3_csgs1dv6drms80o1i9p49677w:  # Zuendungsstatus (degraded) / Ignition state (degraded)
    com-based-signal-group-transformations=BaseTrans_Profile_5_ImportedAdaptivePilot_4
    i-signal=[C04_CANFD_1_Container_ST3_Ign_Stat_ST3/CRC_Ign_Stat_Pr5_ST3, C04_CANFD_1_Container_ST3_Ign_Stat_ST3/ISw_Stat_ST3, C04_CANFD_1_Container_ST3_Ign_Stat_ST3/KG_StartSw_Psd_ST3, C04_CANFD_1_Container_ST3_Ign_Stat_ST3/SQC_Ign_Stat_Pr5_ST3, C04_CANFD_1_Container_ST3_Ign_Stat_ST3/Veh_Op_Mode_ST3]
    system-signal-group=Ign_Stat_Pr5_ST3_csgs1dv6drms80o1i9p49677w
    end-to-end-transformation-i-signal-props{transformer=E2E_Profile_5, data-ids=51, data-length=32}
package /ISignalGroups/CANFD1_Cluster4/PKG_CANFD1_Cluster4/C04_CANFD_1_Container_ST3_VSS_TP_Auth_ST3
  i signal group VSS_TP_Auth_ST3_6j4id7sghlvlbroli4wjozjik: i-signal=[C04_CANFD_1_Container_ST3_VSS_TP_Auth_ST3/VSS_TP_Auth_0_ST3, C04_CANFD_1_Container_ST3_VSS_TP_Auth_ST3/VSS_TP_Auth_1_ST3, C04_CANFD_1_Container_ST3_VSS_TP_Auth_ST3/VSS_TP_Auth_2_ST3, C04_CANFD_1_Container_ST3_VSS_TP_Auth_ST3/VSS_TP_Auth_3_ST3, C04_CANFD_1_Container_ST3_VSS_TP_Auth_ST3/VSS_TP_Auth_4_ST3, C04_CANFD_1_Container_ST3_VSS_TP_Auth_ST3/VSS_TP_Auth_5_ST3, C04_CANFD_1_Container_ST3_VSS_TP_Auth_ST3/VSS_TP_Auth_6_ST3, C04_CANFD_1_Container_ST3_VSS_TP_Auth_ST3/VSS_TP_Auth_7_ST3], system-signal-group=VSS_TP_Auth_ST3_6j4id7sghlvlbroli4wjozjik  # VSS-Transportprotokoll für Authentifizierung (degraded) / Vehicle Security System Transport Protocol for authentication broadcast (degraded)
package /ISignalGroups/CANFD1_Cluster4/PKG_CANFD1_Cluster4/C04_CANFD_1_Container_ST3_VSS_TP_RealTmOffset_ST3
  i signal group VSS_TP_RealTmOffset_ST3_1t7vc44gftc0wv35k5kgc2in9: i-signal=[C04_CANFD_1_Container_ST3_VSS_TP_RealTmOffset_ST3/VSS_TP_RealTmOffset_0_ST3, C04_CANFD_1_Container_ST3_VSS_TP_RealTmOffset_ST3/VSS_TP_RealTmOffset_1_ST3, C04_CANFD_1_Container_ST3_VSS_TP_RealTmOffset_ST3/VSS_TP_RealTmOffset_2_ST3, C04_CANFD_1_Container_ST3_VSS_TP_RealTmOffset_ST3/VSS_TP_RealTmOffset_3_ST3, C04_CANFD_1_Container_ST3_VSS_TP_RealTmOffset_ST3/VSS_TP_RealTmOffset_4_ST3, C04_CANFD_1_Container_ST3_VSS_TP_RealTmOffset_ST3/VSS_TP_RealTmOffset_5_ST3, C04_CANFD_1_Container_ST3_VSS_TP_RealTmOffset_ST3/VSS_TP_RealTmOffset_6_ST3, C04_CANFD_1_Container_ST3_VSS_TP_RealTmOffset_ST3/VSS_TP_RealTmOffset_7_ST3], system-signal-group=VSS_TP_RealTmOffset_ST3_1t7vc44gftc0wv35k5kgc2in9  # VSS-Transportprotokoll für Echtzeit-Offset (degraded) / Vehicle Security System Transport Protocol for real time offset broadcast (degraded)
package /ISignalGroups/CANFD1_Cluster4/PKG_CANFD1_Cluster4/C04_CANFD_1_Container_ST3_VSS_TP_SecTickCount_Lvl2_ST3
  i signal group VSS_TP_SecTickCount_Lvl2_ST3_9eubq13iosat764o0lqh5xb6r: i-signal=[C04_CANFD_1_Container_ST3_VSS_TP_SecTickCount_Lvl2_ST3/VSS_TP_SecTickCount_Lvl2_0_ST3, C04_CANFD_1_Container_ST3_VSS_TP_SecTickCount_Lvl2_ST3/VSS_TP_SecTickCount_Lvl2_1_ST3, C04_CANFD_1_Container_ST3_VSS_TP_SecTickCount_Lvl2_ST3/VSS_TP_SecTickCount_Lvl2_2_ST3, C04_CANFD_1_Container_ST3_VSS_TP_SecTickCount_Lvl2_ST3/VSS_TP_SecTickCount_Lvl2_3_ST3, C04_CANFD_1_Container_ST3_VSS_TP_SecTickCount_Lvl2_ST3/VSS_TP_SecTickCount_Lvl2_4_ST3, C04_CANFD_1_Container_ST3_VSS_TP_SecTickCount_Lvl2_ST3/VSS_TP_SecTickCount_Lvl2_5_ST3, C04_CANFD_1_Container_ST3_VSS_TP_SecTickCount_Lvl2_ST3/VSS_TP_SecTickCount_Lvl2_6_ST3, C04_CANFD_1_Container_ST3_VSS_TP_SecTickCount_Lvl2_ST3/VSS_TP_SecTickCount_Lvl2_7_ST3], system-signal-group=VSS_TP_SecTickCount_Lvl2_ST3_9eubq13iosat764o0lqh5xb6r  # VSS-Transportprotokoll für sichere Zeit Stufe 2 (degraded) / Vehicle Security System Transport Protocol for secure tick count level #2 (degraded)
package /ISignalGroups/CANFD1_Cluster4/PKG_CANFD1_Cluster4/C04_CANFD_1_Container_ST3_VSS_TP_SharedSecret_ST3
  i signal group VSS_TP_SharedSecret_ST3_8pj4t8t4rm3tw3pk5hj7vonti: i-signal=[C04_CANFD_1_Container_ST3_VSS_TP_SharedSecret_ST3/VSS_TP_SharedSecret_0_ST3, C04_CANFD_1_Container_ST3_VSS_TP_SharedSecret_ST3/VSS_TP_SharedSecret_1_ST3, C04_CANFD_1_Container_ST3_VSS_TP_SharedSecret_ST3/VSS_TP_SharedSecret_2_ST3, C04_CANFD_1_Container_ST3_VSS_TP_SharedSecret_ST3/VSS_TP_SharedSecret_3_ST3, C04_CANFD_1_Container_ST3_VSS_TP_SharedSecret_ST3/VSS_TP_SharedSecret_4_ST3, C04_CANFD_1_Container_ST3_VSS_TP_SharedSecret_ST3/VSS_TP_SharedSecret_5_ST3, C04_CANFD_1_Container_ST3_VSS_TP_SharedSecret_ST3/VSS_TP_SharedSecret_6_ST3, C04_CANFD_1_Container_ST3_VSS_TP_SharedSecret_ST3/VSS_TP_SharedSecret_7_ST3], system-signal-group=VSS_TP_SharedSecret_ST3_8pj4t8t4rm3tw3pk5hj7vonti  # VSS-Transportprotokoll für gemeinsames Geheimnis (degraded) / Vehicle Security System Transport Protocol for shared secret broadcast (degraded)
package /ISignalGroups/CANFD1_Cluster4/PKG_CANFD1_Cluster4/C04_CANFD_1_Container_ST3_VSS_TP_VIN_ST3
  i signal group VSS_TP_VIN_ST3_bz1xsv84cxzl09j028gn39p69: i-signal=[C04_CANFD_1_Container_ST3_VSS_TP_VIN_ST3/VSS_TP_VIN_0_ST3, C04_CANFD_1_Container_ST3_VSS_TP_VIN_ST3/VSS_TP_VIN_1_ST3, C04_CANFD_1_Container_ST3_VSS_TP_VIN_ST3/VSS_TP_VIN_2_ST3, C04_CANFD_1_Container_ST3_VSS_TP_VIN_ST3/VSS_TP_VIN_3_ST3, C04_CANFD_1_Container_ST3_VSS_TP_VIN_ST3/VSS_TP_VIN_4_ST3, C04_CANFD_1_Container_ST3_VSS_TP_VIN_ST3/VSS_TP_VIN_5_ST3, C04_CANFD_1_Container_ST3_VSS_TP_VIN_ST3/VSS_TP_VIN_6_ST3, C04_CANFD_1_Container_ST3_VSS_TP_VIN_ST3/VSS_TP_VIN_7_ST3], system-signal-group=VSS_TP_VIN_ST3_bz1xsv84cxzl09j028gn39p69  # VSS-Transportprotokoll für Fahrzeugidentifikationsnummer (degraded) / Vehicle Security System Transport Protocol for Vehicle Identification Number (degraded)
package /ISignalGroups/CANFD1_Cluster4/PKG_CANFD1_Cluster4/COM_C04_Frm05_COM_C04_Pdu05
  i signal group COM_C04_SGR01_P05_5t2743h81pbparal6h2spw309: com-based-signal-group-transformations=BaseTrans_Profile_5_ImportedAdaptivePilot_7, i-signal=[COM_C04_Sig004, CRC_COM_C04_SGR01_P05, SQC_COM_C04_SGR01_P05], system-signal-group=COM_C04_SGR01_P05_5t2743h81pbparal6h2spw309, end-to-end-transformation-i-signal-props{transformer=E2E_Profile_5, data-ids=124, data-length=56}  # COM_C04_SGR01_P05 (degraded)
package /ISignalGroups/Eth_Cluster4/PKG_Eth_Cluster4_20/DI_OdoSpeedometer_ST3
  i signal group DI_Odo_Pr5_ST3_e68xmtlkywxgxsdwekdjjhw3t: com-based-signal-group-transformations=BaseTrans_Profile_5_ImportedAdaptivePilot_6, i-signal=[CRC_DI_Odo_Pr5_ST3, Odo_ST3, SQC_DI_Odo_Pr5_ST3], system-signal-group=DI_Odo_Pr5_ST3_e68xmtlkywxgxsdwekdjjhw3t, end-to-end-transformation-i-signal-props{transformer=E2E_Profile_5, data-ids=186, data-length=48}  # DriverInformation Odometer (degraded)
package /ISignalGroups/Eth_Cluster4/PKG_Eth_Cluster4_20/Ign_Stat_ST3
  i signal group Ign_Stat_Pr5_ST3_csgs1dv6drms80o1i9p49677w:  # Zuendungsstatus (degraded) / Ignition state (degraded)
    com-based-signal-group-transformations=BaseTrans_Profile_5_ImportedAdaptivePilot_4
    i-signal=[Ign_Stat_ST3/CRC_Ign_Stat_Pr5_ST3, Ign_Stat_ST3/ISw_Stat_ST3, Ign_Stat_ST3/KG_StartSw_Psd_ST3, Ign_Stat_ST3/SQC_Ign_Stat_Pr5_ST3, Ign_Stat_ST3/Veh_Op_Mode_ST3]
    system-signal-group=Ign_Stat_Pr5_ST3_csgs1dv6drms80o1i9p49677w
    end-to-end-transformation-i-signal-props{transformer=E2E_Profile_5, data-ids=51, data-length=32}
package /ISignalGroups/Eth_Cluster4/PKG_Eth_Cluster4_20/PT4_PTCoor4_ST3
  i signal group PT4_PTCoor4_Pr5_ST3_af4fxb1ykieox3itqdfzs0kpb:  # PT4_PTCoor4_Pr5_ST3 (degraded)
    com-based-signal-group-transformations=BaseTrans_Profile_5_ImportedAdaptivePilot_4
    i-signal=[CRC_PT4_PTCoor4_Pr5_ST3, PT4_PTCoor_EngStartPN14_Stat_ST3, PT4_PTCoor_PT_Rdy_ST3, PT4_PTCoor_SSA_EngSp_ST3, Rsrv1_PT4_PTCoor_PT_Rdy_Pr5_ST3, SQC_PT4_PTCoor4_Pr5_ST3]
    system-signal-group=PT4_PTCoor4_Pr5_ST3_af4fxb1ykieox3itqdfzs0kpb
    end-to-end-transformation-i-signal-props{transformer=E2E_Profile_5, data-ids=196, data-length=32}
package /ISignalGroups/Eth_Cluster4/PKG_Eth_Cluster4_20/VehSpd_8_ST3
  i signal group VehSpd8_Pr5_ST3_168m1ogyookfwuxfakr38tbmv: com-based-signal-group-transformations=BaseTrans_Profile_5_ImportedAdaptivePilot_4, i-signal=[CRC_VehSpd8_Pr5_ST3, SQC_VehSpd8_Pr5_ST3, VehSpd8_ST3], system-signal-group=VehSpd8_Pr5_ST3_168m1ogyookfwuxfakr38tbmv, end-to-end-transformation-i-signal-props{transformer=E2E_Profile_5, data-ids=207, data-length=32}  # Fahrzeug Spd 8 ST3 (degraded) / vehicle Spd 8 ST3 (degraded)
package /ISignalGroups/Eth_Cluster4/PKG_Eth_Cluster4_20/VSS_TP_Auth_ST3
  i signal group VSS_TP_Auth_ST3_6j4id7sghlvlbroli4wjozjik: i-signal=[VSS_TP_Auth_ST3/VSS_TP_Auth_0_ST3, VSS_TP_Auth_ST3/VSS_TP_Auth_1_ST3, VSS_TP_Auth_ST3/VSS_TP_Auth_2_ST3, VSS_TP_Auth_ST3/VSS_TP_Auth_3_ST3, VSS_TP_Auth_ST3/VSS_TP_Auth_4_ST3, VSS_TP_Auth_ST3/VSS_TP_Auth_5_ST3, VSS_TP_Auth_ST3/VSS_TP_Auth_6_ST3, VSS_TP_Auth_ST3/VSS_TP_Auth_7_ST3], system-signal-group=VSS_TP_Auth_ST3_6j4id7sghlvlbroli4wjozjik  # VSS-Transportprotokoll für Authentifizierung (degraded) / Vehicle Security System Transport Protocol for authentication broadcast (degraded)
package /ISignalGroups/Eth_Cluster4/PKG_Eth_Cluster4_20/VSS_TP_RealTmOffset_ST3
  i signal group VSS_TP_RealTmOffset_ST3_1t7vc44gftc0wv35k5kgc2in9: i-signal=[VSS_TP_RealTmOffset_ST3/VSS_TP_RealTmOffset_0_ST3, VSS_TP_RealTmOffset_ST3/VSS_TP_RealTmOffset_1_ST3, VSS_TP_RealTmOffset_ST3/VSS_TP_RealTmOffset_2_ST3, VSS_TP_RealTmOffset_ST3/VSS_TP_RealTmOffset_3_ST3, VSS_TP_RealTmOffset_ST3/VSS_TP_RealTmOffset_4_ST3, VSS_TP_RealTmOffset_ST3/VSS_TP_RealTmOffset_5_ST3, VSS_TP_RealTmOffset_ST3/VSS_TP_RealTmOffset_6_ST3, VSS_TP_RealTmOffset_ST3/VSS_TP_RealTmOffset_7_ST3], system-signal-group=VSS_TP_RealTmOffset_ST3_1t7vc44gftc0wv35k5kgc2in9  # VSS-Transportprotokoll für Echtzeit-Offset (degraded) / Vehicle Security System Transport Protocol for real time offset broadcast (degraded)
package /ISignalGroups/Eth_Cluster4/PKG_Eth_Cluster4_20/VSS_TP_SecTickCount_Lvl1_ST3
  i signal group VSS_TP_SecTickCount_Lvl1_ST3_mzmfdqtqz5kvv1kfpvg0kql3: i-signal=[VSS_TP_SecTickCount_Lvl1_0_ST3, VSS_TP_SecTickCount_Lvl1_1_ST3, VSS_TP_SecTickCount_Lvl1_2_ST3, VSS_TP_SecTickCount_Lvl1_3_ST3, VSS_TP_SecTickCount_Lvl1_4_ST3, VSS_TP_SecTickCount_Lvl1_5_ST3, VSS_TP_SecTickCount_Lvl1_6_ST3, VSS_TP_SecTickCount_Lvl1_7_ST3], system-signal-group=VSS_TP_SecTickCount_Lvl1_ST3_mzmfdqtqz5kvv1kfpvg0kql3  # VSS-Transportprotokoll für sichere Zeit Stufe 1 (degraded) / Vehicle Security System Transport Protocol for secure tick count level #1 (degraded)
package /ISignalGroups/Eth_Cluster4/PKG_Eth_Cluster4_20/VSS_TP_SharedSecret_ST3
  i signal group VSS_TP_SharedSecret_ST3_8pj4t8t4rm3tw3pk5hj7vonti: i-signal=[VSS_TP_SharedSecret_ST3/VSS_TP_SharedSecret_0_ST3, VSS_TP_SharedSecret_ST3/VSS_TP_SharedSecret_1_ST3, VSS_TP_SharedSecret_ST3/VSS_TP_SharedSecret_2_ST3, VSS_TP_SharedSecret_ST3/VSS_TP_SharedSecret_3_ST3, VSS_TP_SharedSecret_ST3/VSS_TP_SharedSecret_4_ST3, VSS_TP_SharedSecret_ST3/VSS_TP_SharedSecret_5_ST3, VSS_TP_SharedSecret_ST3/VSS_TP_SharedSecret_6_ST3, VSS_TP_SharedSecret_ST3/VSS_TP_SharedSecret_7_ST3], system-signal-group=VSS_TP_SharedSecret_ST3_8pj4t8t4rm3tw3pk5hj7vonti  # VSS-Transportprotokoll für gemeinsames Geheimnis (degraded) / Vehicle Security System Transport Protocol for shared secret broadcast (degraded)
package /ISignalGroups/Eth_Cluster4/PKG_Eth_Cluster4_20/VSS_TP_VIN_ST3
  i signal group VSS_TP_VIN_ST3_bz1xsv84cxzl09j028gn39p69: i-signal=[VSS_TP_VIN_ST3/VSS_TP_VIN_0_ST3, VSS_TP_VIN_ST3/VSS_TP_VIN_1_ST3, VSS_TP_VIN_ST3/VSS_TP_VIN_2_ST3, VSS_TP_VIN_ST3/VSS_TP_VIN_3_ST3, VSS_TP_VIN_ST3/VSS_TP_VIN_4_ST3, VSS_TP_VIN_ST3/VSS_TP_VIN_5_ST3, VSS_TP_VIN_ST3/VSS_TP_VIN_6_ST3, VSS_TP_VIN_ST3/VSS_TP_VIN_7_ST3], system-signal-group=VSS_TP_VIN_ST3_bz1xsv84cxzl09j028gn39p69  # VSS-Transportprotokoll für Fahrzeugidentifikationsnummer (degraded) / Vehicle Security System Transport Protocol for Vehicle Identification Number (degraded)
package /ISignalGroups/Eth_Cluster4/PKG_Eth_Cluster4_1/DIAG_ROE_C04_Container_ST3_ROE_C04_PDU01
  i signal group Diag_RoE_C04_SigGrp01_2ksq5hjijyze6lf3nboiafq6k: i-signal=[Diag_RoE_C04_Sig00, Diag_RoE_C04_Sig01, Diag_RoE_C04_Sig02, Diag_RoE_C04_Sig03, Diag_RoE_C04_Sig04, Diag_RoE_C04_Sig05, Diag_RoE_C04_Sig06, Diag_RoE_C04_Sig07], system-signal-group=Diag_RoE_C04_SigGrp01_2ksq5hjijyze6lf3nboiafq6k  # Diag RoE C14 Sig Grp 01 (degraded)
package /SecureCommunicationPropsSet
  secure communication props set XDIS_singleton_SecCommPropsSet
    secure communication authentication props SECOC_AP_CMAC_AES_128_24: auth-algorithm=CMAC/AES-128, auth-info-tx-length=24
    secure communication freshness props SECOC_FP_10000_40_8_true: freshness-timestamp-time-period-factor=10000, freshness-value-length=40, freshness-value-tx-length=8, use-freshness-timestamp=true
package /CommunicationClusters/CAN1_Cluster4
  can cluster CAN1_Cluster4: baudrate=500000, protocol-name=CAN, protocol-version=can2.0b
    can physical channel CAN1_Cluster4: comm-connectors=ECU4_CRN_CAN1_Cluster4_6it1ke922hxi7y4c8scsqzzry
      frame GTS_Main_CAN_CTP: id 0x79, from ECU4_CRN, frame-length=8, can-addressing-mode=STANDARD  # Status Uhrsynchronisation / Clock synchronisation state
        carries pdu PKG_CAN1_Cluster4/GTS_Main_CAN_CTP: packing-byte-order=big-endian, start-position=7
        general purpose pdu GTS_Main_CAN_CTP: category=GLOBAL_TIME, length=8  # Status Uhrsynchronisation / Clock synchronisation state
      frame Ign_Stat_ST3: id 0x80, from ECU4_CRN, frame-length=8, can-addressing-mode=STANDARD  # Zuendungsstatus / Ignition state
        secured i pdu Ign_Stat_ST3_secured: length=8, authentication-props=SECOC_AP_CMAC_AES_128_24, freshness-props=SECOC_FP_10000_40_8_true, payload=Ign_Stat_ST3_b6hcke40sxoa8zr9fzlj382jh, secure-communication-props={authentication-retries=0, data-id=28212, freshness-value-id=1}
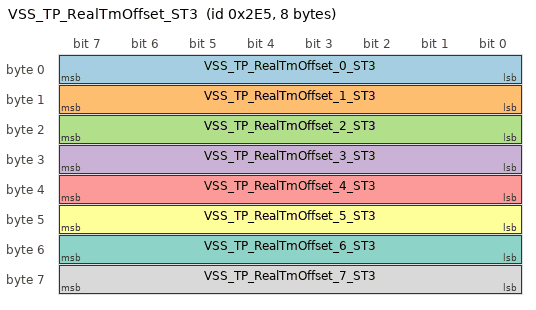
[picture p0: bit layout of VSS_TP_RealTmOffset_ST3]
      frame VSS_TP_RealTmOffset_ST3: id 0x2E5, from ECU4_CRN, frame-length=8, can-addressing-mode=STANDARD  # VSS-Transportprotokoll für Echtzeit-Offset / Vehicle Security System Transport Protocol for real time offset broadcast
        pdu VSS_TP_RealTmOffset_ST3: length=8, minimum-delay=0.02, transmission-mode-true-timing=event-controlled-timing=number-of-repetitions=0, unused-bit-pattern=255  # VSS-Transportprotokoll für Echtzeit-Offset / Vehicle Security System Transport Protocol for real time offset broadcast
          signal VSS_TP_RealTmOffset_0_ST3: start 0, 8 bit, little-endian, data-type-policy=OVERRIDE, i-signal-type=PRIMITIVE, init-value=255, base-type=uint8, data-constr=c08_UInt_SNA_na  # VSS-Transportprotokoll für Echtzeit-Offset, Byte 0 / Vehicle Security System Transport Protocol for real time offset broadcast, Byte 0
          signal VSS_TP_RealTmOffset_1_ST3: start 8, 8 bit, little-endian, data-type-policy=OVERRIDE, i-signal-type=PRIMITIVE, init-value=255, base-type=uint8, data-constr=c08_UInt_SNA_na  # VSS-Transportprotokoll für Echtzeit-Offset, Byte 1 / Vehicle Security System Transport Protocol for real time offset broadcast, Byte 1
          signal VSS_TP_RealTmOffset_2_ST3: start 16, 8 bit, little-endian, data-type-policy=OVERRIDE, i-signal-type=PRIMITIVE, init-value=255, base-type=uint8, data-constr=c08_UInt_SNA_na  # VSS-Transportprotokoll für Echtzeit-Offset, Byte 2 / Vehicle Security System Transport Protocol for real time offset broadcast, Byte 2
          signal VSS_TP_RealTmOffset_3_ST3: start 24, 8 bit, little-endian, data-type-policy=OVERRIDE, i-signal-type=PRIMITIVE, init-value=255, base-type=uint8, data-constr=c08_UInt_SNA_na  # VSS-Transportprotokoll für Echtzeit-Offset, Byte 3 / Vehicle Security System Transport Protocol for real time offset broadcast, Byte 3
          signal VSS_TP_RealTmOffset_4_ST3: start 32, 8 bit, little-endian, data-type-policy=OVERRIDE, i-signal-type=PRIMITIVE, init-value=255, base-type=uint8, data-constr=c08_UInt_SNA_na  # VSS-Transportprotokoll für Echtzeit-Offset, Byte 4 / Vehicle Security System Transport Protocol for real time offset broadcast, Byte 4
          signal VSS_TP_RealTmOffset_5_ST3: start 40, 8 bit, little-endian, data-type-policy=OVERRIDE, i-signal-type=PRIMITIVE, init-value=255, base-type=uint8, data-constr=c08_UInt_SNA_na  # VSS-Transportprotokoll für Echtzeit-Offset, Byte 5 / Vehicle Security System Transport Protocol for real time offset broadcast, Byte 5
          signal VSS_TP_RealTmOffset_6_ST3: start 48, 8 bit, little-endian, data-type-policy=OVERRIDE, i-signal-type=PRIMITIVE, init-value=255, base-type=uint8, data-constr=c08_UInt_SNA_na  # VSS-Transportprotokoll für Echtzeit-Offset, Byte 6 / Vehicle Security System Transport Protocol for real time offset broadcast, Byte 6
          signal VSS_TP_RealTmOffset_7_ST3: start 56, 8 bit, little-endian, data-type-policy=OVERRIDE, i-signal-type=PRIMITIVE, init-value=255, base-type=uint8, data-constr=c08_UInt_SNA_na  # VSS-Transportprotokoll für Echtzeit-Offset, Byte 7 / Vehicle Security System Transport Protocol for real time offset broadcast, Byte 7
          mapping VSS_TP_RealTmOffset_ST3_1t7vc44gftc0wv35k5kgc2in9: i-signal-group=VSS_TP_RealTmOffset_ST3/VSS_TP_RealTmOffset_ST3_1t7vc44gftc0wv35k5kgc2in9, packing-byte-order=little-endian, transfer-property=TRIGGERED
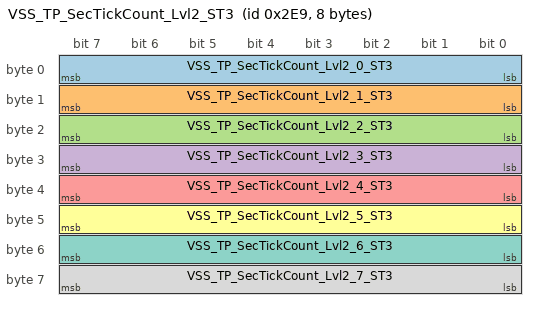
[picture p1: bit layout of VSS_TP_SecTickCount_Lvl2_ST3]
      frame VSS_TP_SecTickCount_Lvl2_ST3: id 0x2E9, from ECU4_CRN, frame-length=8, can-addressing-mode=STANDARD  # VSS-Transportprotokoll für sichere Zeit Stufe 2 / Vehicle Security System Transport Protocol for secure tick count level #2
        pdu VSS_TP_SecTickCount_Lvl2_ST3: length=8, minimum-delay=0.02, transmission-mode-true-timing=event-controlled-timing=number-of-repetitions=0, unused-bit-pattern=255  # VSS-Transportprotokoll für sichere Zeit Stufe 2 / Vehicle Security System Transport Protocol for secure tick count level #2
          signal VSS_TP_SecTickCount_Lvl2_0_ST3: start 0, 8 bit, little-endian, data-type-policy=OVERRIDE, i-signal-type=PRIMITIVE, init-value=255, base-type=uint8, data-constr=c08_UInt_SNA_na  # VSS-Transportprotokoll für sichere Zeit Stufe 2, Byte 0 / Vehicle Security System Transport Protocol for secure tick count level #2, Byte 0
          signal VSS_TP_SecTickCount_Lvl2_1_ST3: start 8, 8 bit, little-endian, data-type-policy=OVERRIDE, i-signal-type=PRIMITIVE, init-value=255, base-type=uint8, data-constr=c08_UInt_SNA_na  # VSS-Transportprotokoll für sichere Zeit Stufe 2, Byte 1 / Vehicle Security System Transport Protocol for secure tick count level #2, Byte 1
          signal VSS_TP_SecTickCount_Lvl2_2_ST3: start 16, 8 bit, little-endian, data-type-policy=OVERRIDE, i-signal-type=PRIMITIVE, init-value=255, base-type=uint8, data-constr=c08_UInt_SNA_na  # VSS-Transportprotokoll für sichere Zeit Stufe 2, Byte 2 / Vehicle Security System Transport Protocol for secure tick count level #2, Byte 2
          signal VSS_TP_SecTickCount_Lvl2_3_ST3: start 24, 8 bit, little-endian, data-type-policy=OVERRIDE, i-signal-type=PRIMITIVE, init-value=255, base-type=uint8, data-constr=c08_UInt_SNA_na  # VSS-Transportprotokoll für sichere Zeit Stufe 2, Byte 3 / Vehicle Security System Transport Protocol for secure tick count level #2, Byte 3
          signal VSS_TP_SecTickCount_Lvl2_4_ST3: start 32, 8 bit, little-endian, data-type-policy=OVERRIDE, i-signal-type=PRIMITIVE, init-value=255, base-type=uint8, data-constr=c08_UInt_SNA_na  # VSS-Transportprotokoll für sichere Zeit Stufe 2, Byte 4 / Vehicle Security System Transport Protocol for secure tick count level #2, Byte 4
          signal VSS_TP_SecTickCount_Lvl2_5_ST3: start 40, 8 bit, little-endian, data-type-policy=OVERRIDE, i-signal-type=PRIMITIVE, init-value=255, base-type=uint8, data-constr=c08_UInt_SNA_na  # VSS-Transportprotokoll für sichere Zeit Stufe 2, Byte 5 / Vehicle Security System Transport Protocol for secure tick count level #2, Byte 5
          signal VSS_TP_SecTickCount_Lvl2_6_ST3: start 48, 8 bit, little-endian, data-type-policy=OVERRIDE, i-signal-type=PRIMITIVE, init-value=255, base-type=uint8, data-constr=c08_UInt_SNA_na  # VSS-Transportprotokoll für sichere Zeit Stufe 2, Byte 6 / Vehicle Security System Transport Protocol for secure tick count level #2, Byte 6
          signal VSS_TP_SecTickCount_Lvl2_7_ST3: start 56, 8 bit, little-endian, data-type-policy=OVERRIDE, i-signal-type=PRIMITIVE, init-value=255, base-type=uint8, data-constr=c08_UInt_SNA_na  # VSS-Transportprotokoll für sichere Zeit Stufe 2, Byte 7 / Vehicle Security System Transport Protocol for secure tick count level #2, Byte 7
          mapping VSS_TP_SecTickCount_Lvl2_ST3_9eubq13iosat764o0lqh5xb6r: i-signal-group=VSS_TP_SecTickCount_Lvl2_ST3/VSS_TP_SecTickCount_Lvl2_ST3_9eubq13iosat764o0lqh5xb6r, packing-byte-order=little-endian, transfer-property=TRIGGERED
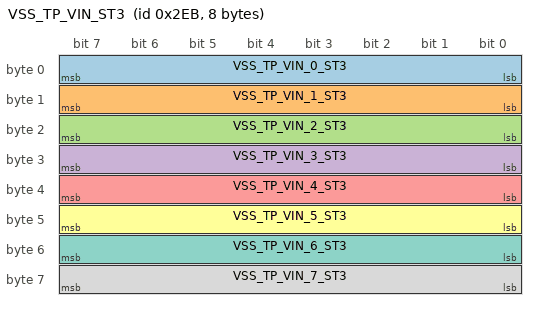
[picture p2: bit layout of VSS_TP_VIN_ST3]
      frame VSS_TP_VIN_ST3: id 0x2EB, from ECU4_CRN, frame-length=8, can-addressing-mode=STANDARD  # VSS-Transportprotokoll für Fahrzeugidentifikationsnummer / Vehicle Security System Transport Protocol for Vehicle Identification Number
        pdu VSS_TP_VIN_ST3: length=8, minimum-delay=0.02, transmission-mode-true-timing=event-controlled-timing=number-of-repetitions=0, unused-bit-pattern=255  # VSS-Transportprotokoll für Fahrzeugidentifikationsnummer / Vehicle Security System Transport Protocol for Vehicle Identification Number
          signal VSS_TP_VIN_0_ST3: start 0, 8 bit, little-endian, data-type-policy=OVERRIDE, i-signal-type=PRIMITIVE, init-value=63, base-type=uint8, data-constr=c08_UInt_SNA_na  # VSS-Transportprotokoll für Fahrzeugidentifikationsnummer, Byte 0 / Vehicle Security System Transport Protocol for Vehicle Identification Number, Byte 0
          signal VSS_TP_VIN_1_ST3: start 8, 8 bit, little-endian, data-type-policy=OVERRIDE, i-signal-type=PRIMITIVE, init-value=63, base-type=uint8, data-constr=c08_UInt_SNA_na  # VSS-Transportprotokoll für Fahrzeugidentifikationsnummer, Byte 1 / Vehicle Security System Transport Protocol for Vehicle Identification Number, Byte 1
          signal VSS_TP_VIN_2_ST3: start 16, 8 bit, little-endian, data-type-policy=OVERRIDE, i-signal-type=PRIMITIVE, init-value=63, base-type=uint8, data-constr=c08_UInt_SNA_na  # VSS-Transportprotokoll für Fahrzeugidentifikationsnummer, Byte 2 / Vehicle Security System Transport Protocol for Vehicle Identification Number, Byte 2
          signal VSS_TP_VIN_3_ST3: start 24, 8 bit, little-endian, data-type-policy=OVERRIDE, i-signal-type=PRIMITIVE, init-value=63, base-type=uint8, data-constr=c08_UInt_SNA_na  # VSS-Transportprotokoll für Fahrzeugidentifikationsnummer, Byte 3 / Vehicle Security System Transport Protocol for Vehicle Identification Number, Byte 3
          signal VSS_TP_VIN_4_ST3: start 32, 8 bit, little-endian, data-type-policy=OVERRIDE, i-signal-type=PRIMITIVE, init-value=63, base-type=uint8, data-constr=c08_UInt_SNA_na  # VSS-Transportprotokoll für Fahrzeugidentifikationsnummer, Byte 4 / Vehicle Security System Transport Protocol for Vehicle Identification Number, Byte 4
          signal VSS_TP_VIN_5_ST3: start 40, 8 bit, little-endian, data-type-policy=OVERRIDE, i-signal-type=PRIMITIVE, init-value=63, base-type=uint8, data-constr=c08_UInt_SNA_na  # VSS-Transportprotokoll für Fahrzeugidentifikationsnummer, Byte 5 / Vehicle Security System Transport Protocol for Vehicle Identification Number, Byte 5
          signal VSS_TP_VIN_6_ST3: start 48, 8 bit, little-endian, data-type-policy=OVERRIDE, i-signal-type=PRIMITIVE, init-value=63, base-type=uint8, data-constr=c08_UInt_SNA_na  # VSS-Transportprotokoll für Fahrzeugidentifikationsnummer, Byte 6 / Vehicle Security System Transport Protocol for Vehicle Identification Number, Byte 6
          signal VSS_TP_VIN_7_ST3: start 56, 8 bit, little-endian, data-type-policy=OVERRIDE, i-signal-type=PRIMITIVE, init-value=63, base-type=uint8, data-constr=c08_UInt_SNA_na  # VSS-Transportprotokoll für Fahrzeugidentifikationsnummer, Byte 7 / Vehicle Security System Transport Protocol for Vehicle Identification Number, Byte 7
          mapping VSS_TP_VIN_ST3_bz1xsv84cxzl09j028gn39p69: i-signal-group=VSS_TP_VIN_ST3/VSS_TP_VIN_ST3_bz1xsv84cxzl09j028gn39p69, packing-byte-order=little-endian, transfer-property=TRIGGERED
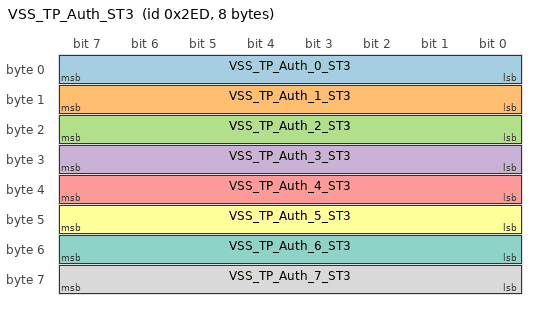
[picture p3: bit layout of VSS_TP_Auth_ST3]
      frame VSS_TP_Auth_ST3: id 0x2ED, from ECU4_CRN, frame-length=8, can-addressing-mode=STANDARD  # VSS-Transportprotokoll für Authentifizierung / Vehicle Security System Transport Protocol for authentication broadcast
        pdu VSS_TP_Auth_ST3: length=8, minimum-delay=0.02, transmission-mode-true-timing=event-controlled-timing=number-of-repetitions=0, unused-bit-pattern=255  # VSS-Transportprotokoll für Authentifizierung / Vehicle Security System Transport Protocol for authentication broadcast
          signal VSS_TP_Auth_0_ST3: start 0, 8 bit, little-endian, data-type-policy=OVERRIDE, i-signal-type=PRIMITIVE, init-value=255, base-type=uint8, data-constr=c08_UInt_SNA_na  # VSS-Transportprotokoll für Authentifizierung, Byte 0 / Vehicle Security System Transport Protocol for authentication broadcast, Byte 0
          signal VSS_TP_Auth_1_ST3: start 8, 8 bit, little-endian, data-type-policy=OVERRIDE, i-signal-type=PRIMITIVE, init-value=255, base-type=uint8, data-constr=c08_UInt_SNA_na  # VSS-Transportprotokoll für Authentifizierung, Byte 1 / Vehicle Security System Transport Protocol for authentication broadcast, Byte 1
          signal VSS_TP_Auth_2_ST3: start 16, 8 bit, little-endian, data-type-policy=OVERRIDE, i-signal-type=PRIMITIVE, init-value=255, base-type=uint8, data-constr=c08_UInt_SNA_na  # VSS-Transportprotokoll für Authentifizierung, Byte 2 / Vehicle Security System Transport Protocol for authentication broadcast, Byte 2
          signal VSS_TP_Auth_3_ST3: start 24, 8 bit, little-endian, data-type-policy=OVERRIDE, i-signal-type=PRIMITIVE, init-value=255, base-type=uint8, data-constr=c08_UInt_SNA_na  # VSS-Transportprotokoll für Authentifizierung, Byte 3 / Vehicle Security System Transport Protocol for authentication broadcast, Byte 3
          signal VSS_TP_Auth_4_ST3: start 32, 8 bit, little-endian, data-type-policy=OVERRIDE, i-signal-type=PRIMITIVE, init-value=255, base-type=uint8, data-constr=c08_UInt_SNA_na  # VSS-Transportprotokoll für Authentifizierung, Byte 4 / Vehicle Security System Transport Protocol for authentication broadcast, Byte 4
          signal VSS_TP_Auth_5_ST3: start 40, 8 bit, little-endian, data-type-policy=OVERRIDE, i-signal-type=PRIMITIVE, init-value=255, base-type=uint8, data-constr=c08_UInt_SNA_na  # VSS-Transportprotokoll für Authentifizierung, Byte 5 / Vehicle Security System Transport Protocol for authentication broadcast, Byte 5
          signal VSS_TP_Auth_6_ST3: start 48, 8 bit, little-endian, data-type-policy=OVERRIDE, i-signal-type=PRIMITIVE, init-value=255, base-type=uint8, data-constr=c08_UInt_SNA_na  # VSS-Transportprotokoll für Authentifizierung, Byte 6 / Vehicle Security System Transport Protocol for authentication broadcast, Byte 6
          signal VSS_TP_Auth_7_ST3: start 56, 8 bit, little-endian, data-type-policy=OVERRIDE, i-signal-type=PRIMITIVE, init-value=255, base-type=uint8, data-constr=c08_UInt_SNA_na  # VSS-Transportprotokoll für Authentifizierung, Byte 7 / Vehicle Security System Transport Protocol for authentication broadcast, Byte 7
          mapping VSS_TP_Auth_ST3_6j4id7sghlvlbroli4wjozjik: i-signal-group=VSS_TP_Auth_ST3/VSS_TP_Auth_ST3_6j4id7sghlvlbroli4wjozjik, packing-byte-order=little-endian, transfer-property=TRIGGERED
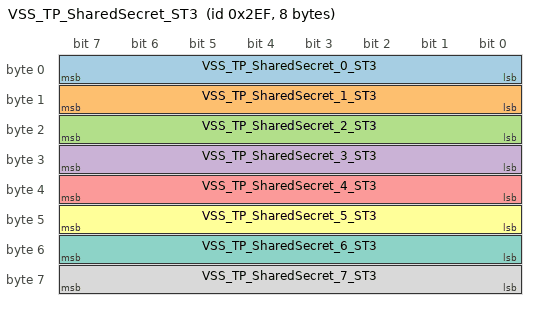
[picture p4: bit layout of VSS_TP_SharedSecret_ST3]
      frame VSS_TP_SharedSecret_ST3: id 0x2EF, from ECU4_CRN, frame-length=8, can-addressing-mode=STANDARD  # VSS-Transportprotokoll für gemeinsames Geheimnis / Vehicle Security System Transport Protocol for shared secret broadcast
        pdu VSS_TP_SharedSecret_ST3: length=8, minimum-delay=0.02, transmission-mode-true-timing=event-controlled-timing=number-of-repetitions=0, unused-bit-pattern=255  # VSS-Transportprotokoll für gemeinsames Geheimnis / Vehicle Security System Transport Protocol for shared secret broadcast
          signal VSS_TP_SharedSecret_0_ST3: start 0, 8 bit, little-endian, data-type-policy=OVERRIDE, i-signal-type=PRIMITIVE, init-value=255, base-type=uint8, data-constr=c08_UInt_SNA_na  # VSS-Transportprotokoll für gemeinsames Geheimnis, Byte 0 / Vehicle Security System Transport Protocol for shared secret broadcast, Byte 0
          signal VSS_TP_SharedSecret_1_ST3: start 8, 8 bit, little-endian, data-type-policy=OVERRIDE, i-signal-type=PRIMITIVE, init-value=255, base-type=uint8, data-constr=c08_UInt_SNA_na  # VSS-Transportprotokoll für gemeinsames Geheimnis, Byte 1 / Vehicle Security System Transport Protocol for shared secret broadcast, Byte 1
          signal VSS_TP_SharedSecret_2_ST3: start 16, 8 bit, little-endian, data-type-policy=OVERRIDE, i-signal-type=PRIMITIVE, init-value=255, base-type=uint8, data-constr=c08_UInt_SNA_na  # VSS-Transportprotokoll für gemeinsames Geheimnis, Byte 2 / Vehicle Security System Transport Protocol for shared secret broadcast, Byte 2
          signal VSS_TP_SharedSecret_3_ST3: start 24, 8 bit, little-endian, data-type-policy=OVERRIDE, i-signal-type=PRIMITIVE, init-value=255, base-type=uint8, data-constr=c08_UInt_SNA_na  # VSS-Transportprotokoll für gemeinsames Geheimnis, Byte 3 / Vehicle Security System Transport Protocol for shared secret broadcast, Byte 3
          signal VSS_TP_SharedSecret_4_ST3: start 32, 8 bit, little-endian, data-type-policy=OVERRIDE, i-signal-type=PRIMITIVE, init-value=255, base-type=uint8, data-constr=c08_UInt_SNA_na  # VSS-Transportprotokoll für gemeinsames Geheimnis, Byte 4 / Vehicle Security System Transport Protocol for shared secret broadcast, Byte 4
          signal VSS_TP_SharedSecret_5_ST3: start 40, 8 bit, little-endian, data-type-policy=OVERRIDE, i-signal-type=PRIMITIVE, init-value=255, base-type=uint8, data-constr=c08_UInt_SNA_na  # VSS-Transportprotokoll für gemeinsames Geheimnis, Byte 5 / Vehicle Security System Transport Protocol for shared secret broadcast, Byte 5
          signal VSS_TP_SharedSecret_6_ST3: start 48, 8 bit, little-endian, data-type-policy=OVERRIDE, i-signal-type=PRIMITIVE, init-value=255, base-type=uint8, data-constr=c08_UInt_SNA_na  # VSS-Transportprotokoll für gemeinsames Geheimnis, Byte 6 / Vehicle Security System Transport Protocol for shared secret broadcast, Byte 6
          signal VSS_TP_SharedSecret_7_ST3: start 56, 8 bit, little-endian, data-type-policy=OVERRIDE, i-signal-type=PRIMITIVE, init-value=255, base-type=uint8, data-constr=c08_UInt_SNA_na  # VSS-Transportprotokoll für gemeinsames Geheimnis, Byte 7 / Vehicle Security System Transport Protocol for shared secret broadcast, Byte 7
          mapping VSS_TP_SharedSecret_ST3_8pj4t8t4rm3tw3pk5hj7vonti: i-signal-group=VSS_TP_SharedSecret_ST3/VSS_TP_SharedSecret_ST3_8pj4t8t4rm3tw3pk5hj7vonti, packing-byte-order=little-endian, transfer-property=TRIGGERED
      frame COM_C04_Frm01_PN08: id 0xFF04008, from ECU4_CRN, frame-length=8, can-addressing-mode=EXTENDED
        pdu COM_C04_Pdu01_PN08: length=8, transmission-mode-true-timing=cyclic-timing={time-offset=0, time-period=1}, unused-bit-pattern=0
          signal COM_C04_Sig01_PN08: start 0, 8 bit, little-endian, data-type-policy=OVERRIDE, i-signal-type=PRIMITIVE, init-value=255, base-type=uint8, data-constr=DT_uint8, transfer-property=PENDING
      frame COM_C04_Frm01_PN17: id 0xFF04017, from ECU4_CRN, frame-length=8, can-addressing-mode=EXTENDED
        pdu COM_C04_Pdu01_PN17: length=8, transmission-mode-true-timing=cyclic-timing={time-offset=0.005, time-period=1}, unused-bit-pattern=0
          signal COM_C04_Sig01_PN17: start 0, 8 bit, little-endian, data-type-policy=OVERRIDE, i-signal-type=PRIMITIVE, init-value=255, base-type=uint8, data-constr=DT_uint8, transfer-property=PENDING
      frame COM_C10_Frm01_PN08: id 0xFF10008, to ECU4_CRN, frame-length=8, can-addressing-mode=EXTENDED
        pdu COM_C10_Pdu01_PN08: length=8, transmission-mode-true-timing=cyclic-timing=time-period=1, unused-bit-pattern=0
          signal COM_C10_Sig01_PN08: start 0, 8 bit, little-endian, data-type-policy=OVERRIDE, i-signal-type=PRIMITIVE, init-value=255, base-type=uint8, data-constr=DT_uint8, transfer-property=PENDING, to ECU4_CRN(timeout 1.1 s)
      frame COM_C10_Frm01_PN17: id 0xFF10017, to ECU4_CRN, frame-length=8, can-addressing-mode=EXTENDED
        pdu COM_C10_Pdu01_PN17: length=8, transmission-mode-true-timing=cyclic-timing=time-period=1, unused-bit-pattern=0
          signal COM_C10_Sig01_PN17: start 0, 8 bit, little-endian, data-type-policy=OVERRIDE, i-signal-type=PRIMITIVE, init-value=255, base-type=uint8, data-constr=DT_uint8, transfer-property=PENDING, to ECU4_CRN(timeout 1.1 s)
      frame NM_C04: id 0x14420004, from ECU4_CRN, frame-length=8, can-addressing-mode=EXTENDED  # NM C04
        nm pdu NM_C04: length=8, nm-data-information=true, unused-bit-pattern=0  # NM C04
          signal NM_C04_PNC: start 8, 56 bit, opaque, data-type-policy=OVERRIDE, i-signal-type=ARRAY, init-value=7 x 0, base-type=uint8, transfer-property=PENDING  # PNC_Vector
      frame NM_C10: id 0x14420010, to ECU4_CRN, frame-length=8, can-addressing-mode=EXTENDED, rx-identifier-range={lower-can-id=339869696, upper-can-id=339873791}  # NM C10
        nm pdu NM_C10: length=8, nm-data-information=true, unused-bit-pattern=0  # NM C10
          signal NM_C10_PNC: start 8, 56 bit, opaque, data-type-policy=OVERRIDE, i-signal-type=ARRAY, init-value=7 x 0, base-type=uint8, transfer-property=PENDING  # PNC_Vector
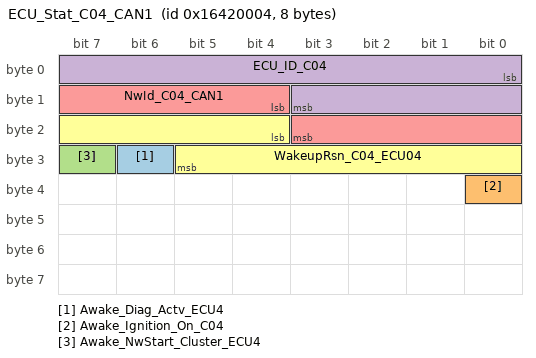
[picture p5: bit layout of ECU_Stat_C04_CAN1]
      frame ECU_Stat_C04_CAN1: id 0x16420004, from ECU4_CRN, frame-length=8, can-addressing-mode=EXTENDED
        pdu ECU_Stat_C04_CAN1: length=8, transmission-mode-true-timing=cyclic-timing={time-offset=0.01, time-period=1}, unused-bit-pattern=255
          signal Awake_Diag_Actv_ECU4: start 30, 1 bit, little-endian, data-type-policy=OVERRIDE, i-signal-type=PRIMITIVE, init-value=1, base-type=boolean, transfer-property=PENDING
          signal Awake_Ignition_On_C04: start 32, 1 bit, little-endian, data-type-policy=OVERRIDE, i-signal-type=PRIMITIVE, init-value=1, base-type=boolean, transfer-property=PENDING
          signal Awake_NwStart_Cluster_ECU4: start 31, 1 bit, little-endian, data-type-policy=OVERRIDE, i-signal-type=PRIMITIVE, init-value=0, base-type=boolean, transfer-property=PENDING
          signal ECU_ID_C04: start 0, 12 bit, little-endian, data-type-policy=OVERRIDE, i-signal-type=PRIMITIVE, init-value=4, base-type=uint16, invalid-value=4095, data-constr=c12_na_0_to_4095_1, transfer-property=PENDING
          signal NwId_C04_CAN1: start 12, 8 bit, little-endian, data-type-policy=OVERRIDE, i-signal-type=PRIMITIVE, init-value=32, base-type=uint8, invalid-value=255, data-constr=c08_na_0_to_255_1, transfer-property=PENDING
          signal WakeupRsn_C04_ECU04: start 20, 10 bit, little-endian, data-type-policy=OVERRIDE, i-signal-type=PRIMITIVE, init-value=1023, base-type=uint16, invalid-value=1023, compu-method=c10_WU_REASON_ECUx, data-constr=c10_WU_REASON_ECUx, transfer-property=PENDING
      frame DIAG_C10_ExtEth_RS_CAN1_CTP: id 0x18E01080, to ECU4_CRN, frame-length=8, can-addressing-mode=EXTENDED  # DIAG RS C10 Can UDS 01
        n pdu DIAG_C10_ExtEth_RS_CAN1_CTP: length=8  # DIAG C10 Ext Eth RS CAN1 CTP
      frame DIAG_C10_IntEth_RS_CAN1_CTP: id 0x18E01085, to ECU4_CRN, frame-length=8, can-addressing-mode=EXTENDED  # DIAG C10 Int Eth RS CAN1 CTP
        n pdu DIAG_C10_IntEth_RS_CAN1_CTP: length=8  # DIAG C10 Int Eth RS CAN1 CTP
      frame DIAG_C10_ExtEth_RQ_CAN1_CTP: id 0x18E01088, from ECU4_CRN, frame-length=8, can-addressing-mode=EXTENDED  # DIAG C10 Ext Eth RQ CAN1 CTP
        n pdu DIAG_C10_ExtEth_RQ_CAN1_CTP: length=8  # DIAG C10 Ext Eth RQ CAN1 CTP
      frame DIAG_C10_IntEth_RQ_CAN1_CTP: id 0x18E0108D, from ECU4_CRN, frame-length=8, can-addressing-mode=EXTENDED  # DIAG C10 Int Eth RQ CAN1 CTP
        n pdu DIAG_C10_IntEth_RQ_CAN1_CTP: length=8  # DIAG C10 Int Eth RQ CAN1 CTP
      frame DIAG_RQ_GLOBAL_ExtEth_ST3: id 0x18EEF888, from ECU4_CRN, frame-length=8, can-addressing-mode=EXTENDED  # Funktionaler Diagnose-Request vom Off-Board Tester (via Ethernet) / Functional Diagnostic Request from Off-Board Tester (via Ethernet)
        n pdu DIAG_RQ_GLOBAL_ExtEth_ST3: length=8  # Funktionale Diagnoseanfrage (UDS) vom ExtEth / Functional Diagnostic Request (UDS) from ExtEth
      frame DIAG_RQ_GLOBAL_IntEth_ST3: id 0x18EF0D8D, from ECU4_CRN, frame-length=8, can-addressing-mode=EXTENDED  # Funktionaler Diagnose-Request vom On-Board Tester (via Ethernet) / Functional Diagnostic Request from On-Board Tester (via Ethernet)
        n pdu DIAG_RQ_GLOBAL_IntEth_ST3: length=8  # Funktionale Diagnoseanfrage (UDS) vom IntEth / Functional Diagnostic Request (UDS) from IntEth
      pdu triggering Ign_Stat_ST3_b6hcke40sxoa8zr9fzlj382jh: pdu=PKG_CAN1_Cluster4/Ign_Stat_ST3, from ECU4_CRN
      pdu triggering SDU_DIAG_C10_ExtEth_RQ_CAN1_CTP_d4iii1s9z0h8hlc7hd91jnf9: pdu=SDU_DIAG_C10_ExtEth_RQ_CAN1_CTP, from ECU4_CRN
      pdu triggering SDU_DIAG_C10_ExtEth_RS_CAN1_CTP_45kqv8rapkarohdgmhy5qdbfv: pdu=SDU_DIAG_C10_ExtEth_RS_CAN1_CTP, to ECU4_CRN
      pdu triggering SDU_DIAG_C10_IntEth_RQ_CAN1_CTP_8e7f66cvttnp4uopo5ud8svmb: pdu=SDU_DIAG_C10_IntEth_RQ_CAN1_CTP, from ECU4_CRN
      pdu triggering SDU_DIAG_C10_IntEth_RS_CAN1_CTP_38dhwswv8v6eorqh74kzv6kpk: pdu=SDU_DIAG_C10_IntEth_RS_CAN1_CTP, to ECU4_CRN
      pdu triggering SDU_DIAG_GLOBAL_ExtEth_RQ_CAN1_ST3_4pxg5bdbxi1ved5j8nlzal2yb: pdu=SDU_DIAG_GLOBAL_ExtEth_RQ_CAN1_ST3, from ECU4_CRN
      pdu triggering SDU_DIAG_GLOBAL_IntEth_RQ_CAN1_ST3_apowalkvpk3lw0lvb9c7jm62x: pdu=SDU_DIAG_GLOBAL_IntEth_RQ_CAN1_ST3, from ECU4_CRN
